[part 3 of 4: packages /MICROSAR/Dcm_swc/Interfaces to /MICROSAR/Dcm_swc/ComponentTypes]
AUTOSAR XML (schema 00048)
package /MICROSAR/Dcm_swc/Interfaces  (continued)
  378 x client server interface, all with is-service=true, service-kind=DIAGNOSTIC-COMMUNICATION-MANAGER:  (continued)
    DataServices_Data_DiagnServi_TABROW_NeuMeasu_Read_35
      operation ReadData: possible-error=[DataServices_Data_DiagnServi_TABROW_NeuMeasu_Read_35/E_NOT_OK, DataServices_Data_DiagnServi_TABROW_NeuMeasu_Read_35/DCM_E_PENDING]
        arg OpStatus: type=Dcm_OpStatusType, direction=IN
        arg Data: type=Dcm_Data5ByteType, direction=OUT
      operation ConditionCheckRead: possible-error=[DataServices_Data_DiagnServi_TABROW_NeuMeasu_Read_35/E_NOT_OK, DataServices_Data_DiagnServi_TABROW_NeuMeasu_Read_35/DCM_E_PENDING]
        arg OpStatus: type=Dcm_OpStatusType, direction=IN
        arg ErrorCode: type=Dcm_NegativeResponseCodeType, direction=OUT
      error E_NOT_OK: error-code=1
      error DCM_E_PENDING: error-code=10
    DataServices_Data_DiagnServi_TABROW_NeuMeasu_Read_34
      operation ReadData: possible-error=[DataServices_Data_DiagnServi_TABROW_NeuMeasu_Read_34/E_NOT_OK, DataServices_Data_DiagnServi_TABROW_NeuMeasu_Read_34/DCM_E_PENDING]
        arg OpStatus: type=Dcm_OpStatusType, direction=IN
        arg Data: type=Dcm_Data1ByteType, direction=OUT
      operation ConditionCheckRead: possible-error=[DataServices_Data_DiagnServi_TABROW_NeuMeasu_Read_34/E_NOT_OK, DataServices_Data_DiagnServi_TABROW_NeuMeasu_Read_34/DCM_E_PENDING]
        arg OpStatus: type=Dcm_OpStatusType, direction=IN
        arg ErrorCode: type=Dcm_NegativeResponseCodeType, direction=OUT
      error E_NOT_OK: error-code=1
      error DCM_E_PENDING: error-code=10
    DataServices_Data_DiagnServi_TABROW_NeuMeasu_Read_33
      operation ReadData: possible-error=[DataServices_Data_DiagnServi_TABROW_NeuMeasu_Read_33/E_NOT_OK, DataServices_Data_DiagnServi_TABROW_NeuMeasu_Read_33/DCM_E_PENDING]
        arg OpStatus: type=Dcm_OpStatusType, direction=IN
        arg Data: type=Dcm_Data3ByteType, direction=OUT
      operation ConditionCheckRead: possible-error=[DataServices_Data_DiagnServi_TABROW_NeuMeasu_Read_33/E_NOT_OK, DataServices_Data_DiagnServi_TABROW_NeuMeasu_Read_33/DCM_E_PENDING]
        arg OpStatus: type=Dcm_OpStatusType, direction=IN
        arg ErrorCode: type=Dcm_NegativeResponseCodeType, direction=OUT
      error E_NOT_OK: error-code=1
      error DCM_E_PENDING: error-code=10
    DataServices_Data_DiagnServi_TABROW_NeuMeasu_Read_39
      operation ReadData: possible-error=[DataServices_Data_DiagnServi_TABROW_NeuMeasu_Read_39/E_NOT_OK, DataServices_Data_DiagnServi_TABROW_NeuMeasu_Read_39/DCM_E_PENDING]
        arg OpStatus: type=Dcm_OpStatusType, direction=IN
        arg Data: type=Dcm_Data1ByteType, direction=OUT
      operation ConditionCheckRead: possible-error=[DataServices_Data_DiagnServi_TABROW_NeuMeasu_Read_39/E_NOT_OK, DataServices_Data_DiagnServi_TABROW_NeuMeasu_Read_39/DCM_E_PENDING]
        arg OpStatus: type=Dcm_OpStatusType, direction=IN
        arg ErrorCode: type=Dcm_NegativeResponseCodeType, direction=OUT
      error E_NOT_OK: error-code=1
      error DCM_E_PENDING: error-code=10
    DataServices_Data_DiagnServi_TABROW_NeuMeasu_Read_38
      operation ReadData: possible-error=[DataServices_Data_DiagnServi_TABROW_NeuMeasu_Read_38/E_NOT_OK, DataServices_Data_DiagnServi_TABROW_NeuMeasu_Read_38/DCM_E_PENDING]
        arg OpStatus: type=Dcm_OpStatusType, direction=IN
        arg Data: type=Dcm_Data1ByteType, direction=OUT
      operation ConditionCheckRead: possible-error=[DataServices_Data_DiagnServi_TABROW_NeuMeasu_Read_38/E_NOT_OK, DataServices_Data_DiagnServi_TABROW_NeuMeasu_Read_38/DCM_E_PENDING]
        arg OpStatus: type=Dcm_OpStatusType, direction=IN
        arg ErrorCode: type=Dcm_NegativeResponseCodeType, direction=OUT
      error E_NOT_OK: error-code=1
      error DCM_E_PENDING: error-code=10
    DataServices_Data_DiagnServi_TABROW_NeuMeasu_Read_37
      operation ReadData: possible-error=[DataServices_Data_DiagnServi_TABROW_NeuMeasu_Read_37/E_NOT_OK, DataServices_Data_DiagnServi_TABROW_NeuMeasu_Read_37/DCM_E_PENDING]
        arg OpStatus: type=Dcm_OpStatusType, direction=IN
        arg Data: type=Dcm_Data2ByteType, direction=OUT
      operation ConditionCheckRead: possible-error=[DataServices_Data_DiagnServi_TABROW_NeuMeasu_Read_37/E_NOT_OK, DataServices_Data_DiagnServi_TABROW_NeuMeasu_Read_37/DCM_E_PENDING]
        arg OpStatus: type=Dcm_OpStatusType, direction=IN
        arg ErrorCode: type=Dcm_NegativeResponseCodeType, direction=OUT
      error E_NOT_OK: error-code=1
      error DCM_E_PENDING: error-code=10
    DataServices_Data_DiagnServi_TABROW_NeuMeasu_Read_46_1_1_1_1_1_1_2
      operation ReadData: possible-error=[DataServices_Data_DiagnServi_TABROW_NeuMeasu_Read_46_1_1_1_1_1_1_2/E_NOT_OK, DataServices_Data_DiagnServi_TABROW_NeuMeasu_Read_46_1_1_1_1_1_1_2/DCM_E_PENDING]
        arg OpStatus: type=Dcm_OpStatusType, direction=IN
        arg Data: type=Dcm_Data152ByteType, direction=OUT
      operation ConditionCheckRead: possible-error=[DataServices_Data_DiagnServi_TABROW_NeuMeasu_Read_46_1_1_1_1_1_1_2/E_NOT_OK, DataServices_Data_DiagnServi_TABROW_NeuMeasu_Read_46_1_1_1_1_1_1_2/DCM_E_PENDING]
        arg OpStatus: type=Dcm_OpStatusType, direction=IN
        arg ErrorCode: type=Dcm_NegativeResponseCodeType, direction=OUT
      error E_NOT_OK: error-code=1
      error DCM_E_PENDING: error-code=10
    DataServices_Data_DiagnServi_TABROW_NeuMeasu_Read_46_1_1_1_1_1_1_1
      operation ReadData: possible-error=[DataServices_Data_DiagnServi_TABROW_NeuMeasu_Read_46_1_1_1_1_1_1_1/E_NOT_OK, DataServices_Data_DiagnServi_TABROW_NeuMeasu_Read_46_1_1_1_1_1_1_1/DCM_E_PENDING]
        arg OpStatus: type=Dcm_OpStatusType, direction=IN
        arg Data: type=Dcm_Data152ByteType, direction=OUT
      operation ConditionCheckRead: possible-error=[DataServices_Data_DiagnServi_TABROW_NeuMeasu_Read_46_1_1_1_1_1_1_1/E_NOT_OK, DataServices_Data_DiagnServi_TABROW_NeuMeasu_Read_46_1_1_1_1_1_1_1/DCM_E_PENDING]
        arg OpStatus: type=Dcm_OpStatusType, direction=IN
        arg ErrorCode: type=Dcm_NegativeResponseCodeType, direction=OUT
      error E_NOT_OK: error-code=1
      error DCM_E_PENDING: error-code=10
    DataServices_Data_DiagnServi_TABROW_NeuMeasu_Read_43
      operation ReadData: possible-error=[DataServices_Data_DiagnServi_TABROW_NeuMeasu_Read_43/E_NOT_OK, DataServices_Data_DiagnServi_TABROW_NeuMeasu_Read_43/DCM_E_PENDING]
        arg OpStatus: type=Dcm_OpStatusType, direction=IN
        arg Data: type=Dcm_Data64ByteType, direction=OUT
      operation ConditionCheckRead: possible-error=[DataServices_Data_DiagnServi_TABROW_NeuMeasu_Read_43/E_NOT_OK, DataServices_Data_DiagnServi_TABROW_NeuMeasu_Read_43/DCM_E_PENDING]
        arg OpStatus: type=Dcm_OpStatusType, direction=IN
        arg ErrorCode: type=Dcm_NegativeResponseCodeType, direction=OUT
      error E_NOT_OK: error-code=1
      error DCM_E_PENDING: error-code=10
    DataServices_Data_DiagnServi_TABROW_NeuMeasu_Read_42
      operation ReadData: possible-error=[DataServices_Data_DiagnServi_TABROW_NeuMeasu_Read_42/E_NOT_OK, DataServices_Data_DiagnServi_TABROW_NeuMeasu_Read_42/DCM_E_PENDING]
        arg OpStatus: type=Dcm_OpStatusType, direction=IN
        arg Data: type=Dcm_Data1ByteType, direction=OUT
      operation ConditionCheckRead: possible-error=[DataServices_Data_DiagnServi_TABROW_NeuMeasu_Read_42/E_NOT_OK, DataServices_Data_DiagnServi_TABROW_NeuMeasu_Read_42/DCM_E_PENDING]
        arg OpStatus: type=Dcm_OpStatusType, direction=IN
        arg ErrorCode: type=Dcm_NegativeResponseCodeType, direction=OUT
      error E_NOT_OK: error-code=1
      error DCM_E_PENDING: error-code=10
    DataServices_Data_DiagnServi_TABROW_NeuMeasu_Read_41
      operation ReadData: possible-error=[DataServices_Data_DiagnServi_TABROW_NeuMeasu_Read_41/E_NOT_OK, DataServices_Data_DiagnServi_TABROW_NeuMeasu_Read_41/DCM_E_PENDING]
        arg OpStatus: type=Dcm_OpStatusType, direction=IN
        arg Data: type=Dcm_Data14ByteType, direction=OUT
      operation ConditionCheckRead: possible-error=[DataServices_Data_DiagnServi_TABROW_NeuMeasu_Read_41/E_NOT_OK, DataServices_Data_DiagnServi_TABROW_NeuMeasu_Read_41/DCM_E_PENDING]
        arg OpStatus: type=Dcm_OpStatusType, direction=IN
        arg ErrorCode: type=Dcm_NegativeResponseCodeType, direction=OUT
      error E_NOT_OK: error-code=1
      error DCM_E_PENDING: error-code=10
    DataServices_Data_DiagnServi_TABROW_NeuMeasu_Read_40
      operation ReadData: possible-error=[DataServices_Data_DiagnServi_TABROW_NeuMeasu_Read_40/E_NOT_OK, DataServices_Data_DiagnServi_TABROW_NeuMeasu_Read_40/DCM_E_PENDING]
        arg OpStatus: type=Dcm_OpStatusType, direction=IN
        arg Data: type=Dcm_Data4ByteType, direction=OUT
      operation ConditionCheckRead: possible-error=[DataServices_Data_DiagnServi_TABROW_NeuMeasu_Read_40/E_NOT_OK, DataServices_Data_DiagnServi_TABROW_NeuMeasu_Read_40/DCM_E_PENDING]
        arg OpStatus: type=Dcm_OpStatusType, direction=IN
        arg ErrorCode: type=Dcm_NegativeResponseCodeType, direction=OUT
      error E_NOT_OK: error-code=1
      error DCM_E_PENDING: error-code=10
    DataServices_Data_DiagnServi_Assembly_part_number_Read
      operation ReadData: possible-error=[DataServices_Data_DiagnServi_Assembly_part_number_Read/E_NOT_OK, DataServices_Data_DiagnServi_Assembly_part_number_Read/DCM_E_PENDING]
        arg OpStatus: type=Dcm_OpStatusType, direction=IN
        arg Data: type=Dcm_Data11ByteType, direction=OUT
      operation ConditionCheckRead: possible-error=[DataServices_Data_DiagnServi_Assembly_part_number_Read/E_NOT_OK, DataServices_Data_DiagnServi_Assembly_part_number_Read/DCM_E_PENDING]
        arg OpStatus: type=Dcm_OpStatusType, direction=IN
        arg ErrorCode: type=Dcm_NegativeResponseCodeType, direction=OUT
      operation WriteData: possible-error=[DataServices_Data_DiagnServi_Assembly_part_number_Read/E_NOT_OK, DataServices_Data_DiagnServi_Assembly_part_number_Read/DCM_E_PENDING]
        arg Data: type=Dcm_Data11ByteType, direction=IN
        arg OpStatus: type=Dcm_OpStatusType, direction=IN
        arg ErrorCode: type=Dcm_NegativeResponseCodeType, direction=OUT
      error E_NOT_OK: error-code=1
      error DCM_E_PENDING: error-code=10
    DataServices_Data_DiagnServi_TABROW_NeuMeasu_Read_47
      operation ReadData: possible-error=[DataServices_Data_DiagnServi_TABROW_NeuMeasu_Read_47/E_NOT_OK, DataServices_Data_DiagnServi_TABROW_NeuMeasu_Read_47/DCM_E_PENDING]
        arg OpStatus: type=Dcm_OpStatusType, direction=IN
        arg Data: type=Dcm_Data2ByteType, direction=OUT
      operation ConditionCheckRead: possible-error=[DataServices_Data_DiagnServi_TABROW_NeuMeasu_Read_47/E_NOT_OK, DataServices_Data_DiagnServi_TABROW_NeuMeasu_Read_47/DCM_E_PENDING]
        arg OpStatus: type=Dcm_OpStatusType, direction=IN
        arg ErrorCode: type=Dcm_NegativeResponseCodeType, direction=OUT
      error E_NOT_OK: error-code=1
      error DCM_E_PENDING: error-code=10
    DataServices_Data_DiagnServi_TABROW_NeuMeasu_Read_46
      operation ReadData: possible-error=[DataServices_Data_DiagnServi_TABROW_NeuMeasu_Read_46/E_NOT_OK, DataServices_Data_DiagnServi_TABROW_NeuMeasu_Read_46/DCM_E_PENDING]
        arg OpStatus: type=Dcm_OpStatusType, direction=IN
        arg Data: type=Dcm_Data152ByteType, direction=OUT
      operation ConditionCheckRead: possible-error=[DataServices_Data_DiagnServi_TABROW_NeuMeasu_Read_46/E_NOT_OK, DataServices_Data_DiagnServi_TABROW_NeuMeasu_Read_46/DCM_E_PENDING]
        arg OpStatus: type=Dcm_OpStatusType, direction=IN
        arg ErrorCode: type=Dcm_NegativeResponseCodeType, direction=OUT
      error E_NOT_OK: error-code=1
      error DCM_E_PENDING: error-code=10
    DataServices_Data_DiagnServi_TABROW_NeuMeasu_Read_45
      operation ReadData: possible-error=[DataServices_Data_DiagnServi_TABROW_NeuMeasu_Read_45/E_NOT_OK, DataServices_Data_DiagnServi_TABROW_NeuMeasu_Read_45/DCM_E_PENDING]
        arg OpStatus: type=Dcm_OpStatusType, direction=IN
        arg Data: type=Dcm_Data6ByteType, direction=OUT
      operation ConditionCheckRead: possible-error=[DataServices_Data_DiagnServi_TABROW_NeuMeasu_Read_45/E_NOT_OK, DataServices_Data_DiagnServi_TABROW_NeuMeasu_Read_45/DCM_E_PENDING]
        arg OpStatus: type=Dcm_OpStatusType, direction=IN
        arg ErrorCode: type=Dcm_NegativeResponseCodeType, direction=OUT
      error E_NOT_OK: error-code=1
      error DCM_E_PENDING: error-code=10
    DataServices_Data_DiagnServi_TABROW_NeuMeasu_Read_49
      operation ReadData: possible-error=[DataServices_Data_DiagnServi_TABROW_NeuMeasu_Read_49/E_NOT_OK, DataServices_Data_DiagnServi_TABROW_NeuMeasu_Read_49/DCM_E_PENDING]
        arg OpStatus: type=Dcm_OpStatusType, direction=IN
        arg Data: type=Dcm_Data2ByteType, direction=OUT
      operation ConditionCheckRead: possible-error=[DataServices_Data_DiagnServi_TABROW_NeuMeasu_Read_49/E_NOT_OK, DataServices_Data_DiagnServi_TABROW_NeuMeasu_Read_49/DCM_E_PENDING]
        arg OpStatus: type=Dcm_OpStatusType, direction=IN
        arg ErrorCode: type=Dcm_NegativeResponseCodeType, direction=OUT
      error E_NOT_OK: error-code=1
      error DCM_E_PENDING: error-code=10
    DataServices_Data_DiagnServi_TABROW_NeuMeasu_Read_48
      operation ReadData: possible-error=[DataServices_Data_DiagnServi_TABROW_NeuMeasu_Read_48/E_NOT_OK, DataServices_Data_DiagnServi_TABROW_NeuMeasu_Read_48/DCM_E_PENDING]
        arg OpStatus: type=Dcm_OpStatusType, direction=IN
        arg Data: type=Dcm_Data24ByteType, direction=OUT
      operation ConditionCheckRead: possible-error=[DataServices_Data_DiagnServi_TABROW_NeuMeasu_Read_48/E_NOT_OK, DataServices_Data_DiagnServi_TABROW_NeuMeasu_Read_48/DCM_E_PENDING]
        arg OpStatus: type=Dcm_OpStatusType, direction=IN
        arg ErrorCode: type=Dcm_NegativeResponseCodeType, direction=OUT
      error E_NOT_OK: error-code=1
      error DCM_E_PENDING: error-code=10
    DataServices_Data_DiagnServi_TABROW_TABROECUPr_Read
      operation ReadData: possible-error=[DataServices_Data_DiagnServi_TABROW_TABROECUPr_Read/E_NOT_OK, DataServices_Data_DiagnServi_TABROW_TABROECUPr_Read/DCM_E_PENDING]
        arg OpStatus: type=Dcm_OpStatusType, direction=IN
        arg Data: type=Dcm_Data1ByteType, direction=OUT
      operation ConditionCheckRead: possible-error=[DataServices_Data_DiagnServi_TABROW_TABROECUPr_Read/E_NOT_OK, DataServices_Data_DiagnServi_TABROW_TABROECUPr_Read/DCM_E_PENDING]
        arg OpStatus: type=Dcm_OpStatusType, direction=IN
        arg ErrorCode: type=Dcm_NegativeResponseCodeType, direction=OUT
      error E_NOT_OK: error-code=1
      error DCM_E_PENDING: error-code=10
    DataServices_Data_TABROW_TABROSyste_Read_1_1_1_1_1_1_1_1_1_1_1_1
      operation ReadData: possible-error=[DataServices_Data_TABROW_TABROSyste_Read_1_1_1_1_1_1_1_1_1_1_1_1/E_NOT_OK, DataServices_Data_TABROW_TABROSyste_Read_1_1_1_1_1_1_1_1_1_1_1_1/DCM_E_PENDING]
        arg OpStatus: type=Dcm_OpStatusType, direction=IN
        arg Data: type=Dcm_Data14ByteType, direction=OUT
      operation ConditionCheckRead: possible-error=[DataServices_Data_TABROW_TABROSyste_Read_1_1_1_1_1_1_1_1_1_1_1_1/E_NOT_OK, DataServices_Data_TABROW_TABROSyste_Read_1_1_1_1_1_1_1_1_1_1_1_1/DCM_E_PENDING]
        arg OpStatus: type=Dcm_OpStatusType, direction=IN
        arg ErrorCode: type=Dcm_NegativeResponseCodeType, direction=OUT
      error E_NOT_OK: error-code=1
      error DCM_E_PENDING: error-code=10
    DataServices_Data_DiagnServi_TABROW_NeuMeasu_Read_10
      operation ReadData: possible-error=[DataServices_Data_DiagnServi_TABROW_NeuMeasu_Read_10/E_NOT_OK, DataServices_Data_DiagnServi_TABROW_NeuMeasu_Read_10/DCM_E_PENDING]
        arg OpStatus: type=Dcm_OpStatusType, direction=IN
        arg Data: type=Dcm_Data2ByteType, direction=OUT
      operation ConditionCheckRead: possible-error=[DataServices_Data_DiagnServi_TABROW_NeuMeasu_Read_10/E_NOT_OK, DataServices_Data_DiagnServi_TABROW_NeuMeasu_Read_10/DCM_E_PENDING]
        arg OpStatus: type=Dcm_OpStatusType, direction=IN
        arg ErrorCode: type=Dcm_NegativeResponseCodeType, direction=OUT
      error E_NOT_OK: error-code=1
      error DCM_E_PENDING: error-code=10
    DataServices_Data_DiagnServi_TABROW_NeuMeasu_Read_43_1_1_1_1_1_1_1_1_1_1_1
      operation ReadData: possible-error=[DataServices_Data_DiagnServi_TABROW_NeuMeasu_Read_43_1_1_1_1_1_1_1_1_1_1_1/E_NOT_OK, DataServices_Data_DiagnServi_TABROW_NeuMeasu_Read_43_1_1_1_1_1_1_1_1_1_1_1/DCM_E_PENDING]
        arg OpStatus: type=Dcm_OpStatusType, direction=IN
        arg Data: type=Dcm_Data64ByteType, direction=OUT
      operation ConditionCheckRead: possible-error=[DataServices_Data_DiagnServi_TABROW_NeuMeasu_Read_43_1_1_1_1_1_1_1_1_1_1_1/E_NOT_OK, DataServices_Data_DiagnServi_TABROW_NeuMeasu_Read_43_1_1_1_1_1_1_1_1_1_1_1/DCM_E_PENDING]
        arg OpStatus: type=Dcm_OpStatusType, direction=IN
        arg ErrorCode: type=Dcm_NegativeResponseCodeType, direction=OUT
      error E_NOT_OK: error-code=1
      error DCM_E_PENDING: error-code=10
    DataServices_Data_Minimum_Discharge_Voltage_Read_Data_By_Identifier
      operation ReadData: possible-error=[DataServices_Data_Minimum_Discharge_Voltage_Read_Data_By_Identifier/E_NOT_OK, DataServices_Data_Minimum_Discharge_Voltage_Read_Data_By_Identifier/DCM_E_PENDING]
        arg OpStatus: type=Dcm_OpStatusType, direction=IN
        arg Data: type=Dcm_Data2ByteType, direction=OUT
      operation ConditionCheckRead: possible-error=[DataServices_Data_Minimum_Discharge_Voltage_Read_Data_By_Identifier/E_NOT_OK, DataServices_Data_Minimum_Discharge_Voltage_Read_Data_By_Identifier/DCM_E_PENDING]
        arg OpStatus: type=Dcm_OpStatusType, direction=IN
        arg ErrorCode: type=Dcm_NegativeResponseCodeType, direction=OUT
      error E_NOT_OK: error-code=1
      error DCM_E_PENDING: error-code=10
    DataServices_Data_DiagnServi_TABROW_NeuMeasu_Read_19
      operation ReadData: possible-error=[DataServices_Data_DiagnServi_TABROW_NeuMeasu_Read_19/E_NOT_OK, DataServices_Data_DiagnServi_TABROW_NeuMeasu_Read_19/DCM_E_PENDING]
        arg OpStatus: type=Dcm_OpStatusType, direction=IN
        arg Data: type=Dcm_Data3ByteType, direction=OUT
      operation ConditionCheckRead: possible-error=[DataServices_Data_DiagnServi_TABROW_NeuMeasu_Read_19/E_NOT_OK, DataServices_Data_DiagnServi_TABROW_NeuMeasu_Read_19/DCM_E_PENDING]
        arg OpStatus: type=Dcm_OpStatusType, direction=IN
        arg ErrorCode: type=Dcm_NegativeResponseCodeType, direction=OUT
      error E_NOT_OK: error-code=1
      error DCM_E_PENDING: error-code=10
    DataServices_Data_DiagnServi_TABROW_NeuMeasu_Read_14
      operation ReadData: possible-error=[DataServices_Data_DiagnServi_TABROW_NeuMeasu_Read_14/E_NOT_OK, DataServices_Data_DiagnServi_TABROW_NeuMeasu_Read_14/DCM_E_PENDING]
        arg OpStatus: type=Dcm_OpStatusType, direction=IN
        arg Data: type=Dcm_Data1ByteType, direction=OUT
      operation ConditionCheckRead: possible-error=[DataServices_Data_DiagnServi_TABROW_NeuMeasu_Read_14/E_NOT_OK, DataServices_Data_DiagnServi_TABROW_NeuMeasu_Read_14/DCM_E_PENDING]
        arg OpStatus: type=Dcm_OpStatusType, direction=IN
        arg ErrorCode: type=Dcm_NegativeResponseCodeType, direction=OUT
      error E_NOT_OK: error-code=1
      error DCM_E_PENDING: error-code=10
    DataServices_Data_DiagnServi_TABROW_NeuMeasu_Read_70_1
      operation ReadData: possible-error=[DataServices_Data_DiagnServi_TABROW_NeuMeasu_Read_70_1/E_NOT_OK, DataServices_Data_DiagnServi_TABROW_NeuMeasu_Read_70_1/DCM_E_PENDING]
        arg OpStatus: type=Dcm_OpStatusType, direction=IN
        arg Data: type=Dcm_Data1ByteType, direction=OUT
      operation ConditionCheckRead: possible-error=[DataServices_Data_DiagnServi_TABROW_NeuMeasu_Read_70_1/E_NOT_OK, DataServices_Data_DiagnServi_TABROW_NeuMeasu_Read_70_1/DCM_E_PENDING]
        arg OpStatus: type=Dcm_OpStatusType, direction=IN
        arg ErrorCode: type=Dcm_NegativeResponseCodeType, direction=OUT
      error E_NOT_OK: error-code=1
      error DCM_E_PENDING: error-code=10
    DataServices_Data_DiagnServi_TABROW_NeuMeasu_Read_13
      operation ReadData: possible-error=[DataServices_Data_DiagnServi_TABROW_NeuMeasu_Read_13/E_NOT_OK, DataServices_Data_DiagnServi_TABROW_NeuMeasu_Read_13/DCM_E_PENDING]
        arg OpStatus: type=Dcm_OpStatusType, direction=IN
        arg Data: type=Dcm_Data6ByteType, direction=OUT
      operation ConditionCheckRead: possible-error=[DataServices_Data_DiagnServi_TABROW_NeuMeasu_Read_13/E_NOT_OK, DataServices_Data_DiagnServi_TABROW_NeuMeasu_Read_13/DCM_E_PENDING]
        arg OpStatus: type=Dcm_OpStatusType, direction=IN
        arg ErrorCode: type=Dcm_NegativeResponseCodeType, direction=OUT
      error E_NOT_OK: error-code=1
      error DCM_E_PENDING: error-code=10
    DataServices_Data_DiagnServi_TABROW_NeuMeasu_Read_12
      operation ReadData: possible-error=[DataServices_Data_DiagnServi_TABROW_NeuMeasu_Read_12/E_NOT_OK, DataServices_Data_DiagnServi_TABROW_NeuMeasu_Read_12/DCM_E_PENDING]
        arg OpStatus: type=Dcm_OpStatusType, direction=IN
        arg Data: type=Dcm_Data3ByteType, direction=OUT
      operation ConditionCheckRead: possible-error=[DataServices_Data_DiagnServi_TABROW_NeuMeasu_Read_12/E_NOT_OK, DataServices_Data_DiagnServi_TABROW_NeuMeasu_Read_12/DCM_E_PENDING]
        arg OpStatus: type=Dcm_OpStatusType, direction=IN
        arg ErrorCode: type=Dcm_NegativeResponseCodeType, direction=OUT
      error E_NOT_OK: error-code=1
      error DCM_E_PENDING: error-code=10
    DataServices_Data_DiagnServi_TABROW_NeuMeasu_Read_11
      operation ReadData: possible-error=[DataServices_Data_DiagnServi_TABROW_NeuMeasu_Read_11/E_NOT_OK, DataServices_Data_DiagnServi_TABROW_NeuMeasu_Read_11/DCM_E_PENDING]
        arg OpStatus: type=Dcm_OpStatusType, direction=IN
        arg Data: type=Dcm_Data3ByteType, direction=OUT
      operation ConditionCheckRead: possible-error=[DataServices_Data_DiagnServi_TABROW_NeuMeasu_Read_11/E_NOT_OK, DataServices_Data_DiagnServi_TABROW_NeuMeasu_Read_11/DCM_E_PENDING]
        arg OpStatus: type=Dcm_OpStatusType, direction=IN
        arg ErrorCode: type=Dcm_NegativeResponseCodeType, direction=OUT
      error E_NOT_OK: error-code=1
      error DCM_E_PENDING: error-code=10
    DataServices_Data_DiagnServi_TABROW_NeuMeasu_Read_18
      operation ReadData: possible-error=[DataServices_Data_DiagnServi_TABROW_NeuMeasu_Read_18/E_NOT_OK, DataServices_Data_DiagnServi_TABROW_NeuMeasu_Read_18/DCM_E_PENDING]
        arg OpStatus: type=Dcm_OpStatusType, direction=IN
        arg Data: type=Dcm_Data1ByteType, direction=OUT
      operation ConditionCheckRead: possible-error=[DataServices_Data_DiagnServi_TABROW_NeuMeasu_Read_18/E_NOT_OK, DataServices_Data_DiagnServi_TABROW_NeuMeasu_Read_18/DCM_E_PENDING]
        arg OpStatus: type=Dcm_OpStatusType, direction=IN
        arg ErrorCode: type=Dcm_NegativeResponseCodeType, direction=OUT
      error E_NOT_OK: error-code=1
      error DCM_E_PENDING: error-code=10
    DataServices_Data_DiagnServi_TABROW_NeuMeasu_Read_17
      operation ReadData: possible-error=[DataServices_Data_DiagnServi_TABROW_NeuMeasu_Read_17/E_NOT_OK, DataServices_Data_DiagnServi_TABROW_NeuMeasu_Read_17/DCM_E_PENDING]
        arg OpStatus: type=Dcm_OpStatusType, direction=IN
        arg Data: type=Dcm_Data1ByteType, direction=OUT
      operation ConditionCheckRead: possible-error=[DataServices_Data_DiagnServi_TABROW_NeuMeasu_Read_17/E_NOT_OK, DataServices_Data_DiagnServi_TABROW_NeuMeasu_Read_17/DCM_E_PENDING]
        arg OpStatus: type=Dcm_OpStatusType, direction=IN
        arg ErrorCode: type=Dcm_NegativeResponseCodeType, direction=OUT
      error E_NOT_OK: error-code=1
      error DCM_E_PENDING: error-code=10
    DataServices_Data_DiagnServi_TABROW_NeuMeasu_Read_16
      operation ReadData: possible-error=[DataServices_Data_DiagnServi_TABROW_NeuMeasu_Read_16/E_NOT_OK, DataServices_Data_DiagnServi_TABROW_NeuMeasu_Read_16/DCM_E_PENDING]
        arg OpStatus: type=Dcm_OpStatusType, direction=IN
        arg Data: type=Dcm_Data1ByteType, direction=OUT
      operation ConditionCheckRead: possible-error=[DataServices_Data_DiagnServi_TABROW_NeuMeasu_Read_16/E_NOT_OK, DataServices_Data_DiagnServi_TABROW_NeuMeasu_Read_16/DCM_E_PENDING]
        arg OpStatus: type=Dcm_OpStatusType, direction=IN
        arg ErrorCode: type=Dcm_NegativeResponseCodeType, direction=OUT
      error E_NOT_OK: error-code=1
      error DCM_E_PENDING: error-code=10
    DataServices_Data_DiagnServi_TABROW_NeuMeasu_Read_15
      operation ReadData: possible-error=[DataServices_Data_DiagnServi_TABROW_NeuMeasu_Read_15/E_NOT_OK, DataServices_Data_DiagnServi_TABROW_NeuMeasu_Read_15/DCM_E_PENDING]
        arg OpStatus: type=Dcm_OpStatusType, direction=IN
        arg Data: type=Dcm_Data1ByteType, direction=OUT
      operation ConditionCheckRead: possible-error=[DataServices_Data_DiagnServi_TABROW_NeuMeasu_Read_15/E_NOT_OK, DataServices_Data_DiagnServi_TABROW_NeuMeasu_Read_15/DCM_E_PENDING]
        arg OpStatus: type=Dcm_OpStatusType, direction=IN
        arg ErrorCode: type=Dcm_NegativeResponseCodeType, direction=OUT
      error E_NOT_OK: error-code=1
      error DCM_E_PENDING: error-code=10
    DataServices_Data_DiagnServi_TABROW_NeuMeasu_Read_27_2_1_1
      operation ReadData: possible-error=[DataServices_Data_DiagnServi_TABROW_NeuMeasu_Read_27_2_1_1/E_NOT_OK, DataServices_Data_DiagnServi_TABROW_NeuMeasu_Read_27_2_1_1/DCM_E_PENDING]
        arg OpStatus: type=Dcm_OpStatusType, direction=IN
        arg Data: type=Dcm_Data27ByteType, direction=OUT
      operation ConditionCheckRead: possible-error=[DataServices_Data_DiagnServi_TABROW_NeuMeasu_Read_27_2_1_1/E_NOT_OK, DataServices_Data_DiagnServi_TABROW_NeuMeasu_Read_27_2_1_1/DCM_E_PENDING]
        arg OpStatus: type=Dcm_OpStatusType, direction=IN
        arg ErrorCode: type=Dcm_NegativeResponseCodeType, direction=OUT
      error E_NOT_OK: error-code=1
      error DCM_E_PENDING: error-code=10
    DataServices_Data_DiagnServi_TABROW_NeuMeasu_Read_20
      operation ReadData: possible-error=[DataServices_Data_DiagnServi_TABROW_NeuMeasu_Read_20/E_NOT_OK, DataServices_Data_DiagnServi_TABROW_NeuMeasu_Read_20/DCM_E_PENDING]
        arg OpStatus: type=Dcm_OpStatusType, direction=IN
        arg Data: type=Dcm_Data1ByteType, direction=OUT
      operation ConditionCheckRead: possible-error=[DataServices_Data_DiagnServi_TABROW_NeuMeasu_Read_20/E_NOT_OK, DataServices_Data_DiagnServi_TABROW_NeuMeasu_Read_20/DCM_E_PENDING]
        arg OpStatus: type=Dcm_OpStatusType, direction=IN
        arg ErrorCode: type=Dcm_NegativeResponseCodeType, direction=OUT
      error E_NOT_OK: error-code=1
      error DCM_E_PENDING: error-code=10
    DataServices_Data_DiagnServi_Assembly_production_data_Read
      operation ReadData: possible-error=[DataServices_Data_DiagnServi_Assembly_production_data_Read/E_NOT_OK, DataServices_Data_DiagnServi_Assembly_production_data_Read/DCM_E_PENDING]
        arg OpStatus: type=Dcm_OpStatusType, direction=IN
        arg Data: type=Dcm_Data22ByteType, direction=OUT
      operation ConditionCheckRead: possible-error=[DataServices_Data_DiagnServi_Assembly_production_data_Read/E_NOT_OK, DataServices_Data_DiagnServi_Assembly_production_data_Read/DCM_E_PENDING]
        arg OpStatus: type=Dcm_OpStatusType, direction=IN
        arg ErrorCode: type=Dcm_NegativeResponseCodeType, direction=OUT
      operation WriteData: possible-error=[DataServices_Data_DiagnServi_Assembly_production_data_Read/E_NOT_OK, DataServices_Data_DiagnServi_Assembly_production_data_Read/DCM_E_PENDING]
        arg Data: type=Dcm_Data22ByteType, direction=IN
        arg OpStatus: type=Dcm_OpStatusType, direction=IN
        arg ErrorCode: type=Dcm_NegativeResponseCodeType, direction=OUT
      error E_NOT_OK: error-code=1
      error DCM_E_PENDING: error-code=10
    DataServices_Data_TABROW_VkmsTrainCount_Read_Data_By_Identifier
      operation ReadData: possible-error=[DataServices_Data_TABROW_VkmsTrainCount_Read_Data_By_Identifier/E_NOT_OK, DataServices_Data_TABROW_VkmsTrainCount_Read_Data_By_Identifier/DCM_E_PENDING]
        arg OpStatus: type=Dcm_OpStatusType, direction=IN
        arg Data: type=Dcm_Data3ByteType, direction=OUT
      operation ConditionCheckRead: possible-error=[DataServices_Data_TABROW_VkmsTrainCount_Read_Data_By_Identifier/E_NOT_OK, DataServices_Data_TABROW_VkmsTrainCount_Read_Data_By_Identifier/DCM_E_PENDING]
        arg OpStatus: type=Dcm_OpStatusType, direction=IN
        arg ErrorCode: type=Dcm_NegativeResponseCodeType, direction=OUT
      error E_NOT_OK: error-code=1
      error DCM_E_PENDING: error-code=10
    DataServices_Data_DiagnServi_Cell_part_number_Read
      operation ReadData: possible-error=[DataServices_Data_DiagnServi_Cell_part_number_Read/E_NOT_OK, DataServices_Data_DiagnServi_Cell_part_number_Read/DCM_E_PENDING]
        arg OpStatus: type=Dcm_OpStatusType, direction=IN
        arg Data: type=Dcm_Data11ByteType, direction=OUT
      operation ConditionCheckRead: possible-error=[DataServices_Data_DiagnServi_Cell_part_number_Read/E_NOT_OK, DataServices_Data_DiagnServi_Cell_part_number_Read/DCM_E_PENDING]
        arg OpStatus: type=Dcm_OpStatusType, direction=IN
        arg ErrorCode: type=Dcm_NegativeResponseCodeType, direction=OUT
      operation WriteData: possible-error=[DataServices_Data_DiagnServi_Cell_part_number_Read/E_NOT_OK, DataServices_Data_DiagnServi_Cell_part_number_Read/DCM_E_PENDING]
        arg Data: type=Dcm_Data11ByteType, direction=IN
        arg OpStatus: type=Dcm_OpStatusType, direction=IN
        arg ErrorCode: type=Dcm_NegativeResponseCodeType, direction=OUT
      error E_NOT_OK: error-code=1
      error DCM_E_PENDING: error-code=10
    DataServices_Data_TABROW_CellStateOfChargMaxim_ReadDataByIdent
      operation ReadData: possible-error=[DataServices_Data_TABROW_CellStateOfChargMaxim_ReadDataByIdent/E_NOT_OK, DataServices_Data_TABROW_CellStateOfChargMaxim_ReadDataByIdent/DCM_E_PENDING]
        arg OpStatus: type=Dcm_OpStatusType, direction=IN
        arg Data: type=Dcm_Data4ByteType, direction=OUT
      operation ConditionCheckRead: possible-error=[DataServices_Data_TABROW_CellStateOfChargMaxim_ReadDataByIdent/E_NOT_OK, DataServices_Data_TABROW_CellStateOfChargMaxim_ReadDataByIdent/DCM_E_PENDING]
        arg OpStatus: type=Dcm_OpStatusType, direction=IN
        arg ErrorCode: type=Dcm_NegativeResponseCodeType, direction=OUT
      error E_NOT_OK: error-code=1
      error DCM_E_PENDING: error-code=10
    DataServices_Data_DiagnServi_TABROW_NeuMeasu_Read_25
      operation ReadData: possible-error=[DataServices_Data_DiagnServi_TABROW_NeuMeasu_Read_25/E_NOT_OK, DataServices_Data_DiagnServi_TABROW_NeuMeasu_Read_25/DCM_E_PENDING]
        arg OpStatus: type=Dcm_OpStatusType, direction=IN
        arg Data: type=Dcm_Data2ByteType, direction=OUT
      operation ConditionCheckRead: possible-error=[DataServices_Data_DiagnServi_TABROW_NeuMeasu_Read_25/E_NOT_OK, DataServices_Data_DiagnServi_TABROW_NeuMeasu_Read_25/DCM_E_PENDING]
        arg OpStatus: type=Dcm_OpStatusType, direction=IN
        arg ErrorCode: type=Dcm_NegativeResponseCodeType, direction=OUT
      error E_NOT_OK: error-code=1
      error DCM_E_PENDING: error-code=10
    DataServices_Data_DiagnServi_TABROW_NeuMeasu_Read_24
      operation ReadData: possible-error=[DataServices_Data_DiagnServi_TABROW_NeuMeasu_Read_24/E_NOT_OK, DataServices_Data_DiagnServi_TABROW_NeuMeasu_Read_24/DCM_E_PENDING]
        arg OpStatus: type=Dcm_OpStatusType, direction=IN
        arg Data: type=Dcm_Data1ByteType, direction=OUT
      operation ConditionCheckRead: possible-error=[DataServices_Data_DiagnServi_TABROW_NeuMeasu_Read_24/E_NOT_OK, DataServices_Data_DiagnServi_TABROW_NeuMeasu_Read_24/DCM_E_PENDING]
        arg OpStatus: type=Dcm_OpStatusType, direction=IN
        arg ErrorCode: type=Dcm_NegativeResponseCodeType, direction=OUT
      error E_NOT_OK: error-code=1
      error DCM_E_PENDING: error-code=10
    DataServices_Data_DiagnServi_TABROW_NeuMeasu_Read_23
      operation ReadData: possible-error=[DataServices_Data_DiagnServi_TABROW_NeuMeasu_Read_23/E_NOT_OK, DataServices_Data_DiagnServi_TABROW_NeuMeasu_Read_23/DCM_E_PENDING]
        arg OpStatus: type=Dcm_OpStatusType, direction=IN
        arg Data: type=Dcm_Data6ByteType, direction=OUT
      operation ConditionCheckRead: possible-error=[DataServices_Data_DiagnServi_TABROW_NeuMeasu_Read_23/E_NOT_OK, DataServices_Data_DiagnServi_TABROW_NeuMeasu_Read_23/DCM_E_PENDING]
        arg OpStatus: type=Dcm_OpStatusType, direction=IN
        arg ErrorCode: type=Dcm_NegativeResponseCodeType, direction=OUT
      error E_NOT_OK: error-code=1
      error DCM_E_PENDING: error-code=10
    DataServices_Data_TABROW_ProgrPreco_Read
      operation ReadData: possible-error=[DataServices_Data_TABROW_ProgrPreco_Read/E_NOT_OK, DataServices_Data_TABROW_ProgrPreco_Read/DCM_E_PENDING]
        arg OpStatus: type=Dcm_OpStatusType, direction=IN
        arg Data: type=Dcm_Data256ByteType, direction=OUT
      operation ReadDataLength: possible-error=[DataServices_Data_TABROW_ProgrPreco_Read/E_NOT_OK, DataServices_Data_TABROW_ProgrPreco_Read/DCM_E_PENDING]
        arg OpStatus: type=Dcm_OpStatusType, direction=IN
        arg DataLength: type=uint16, direction=OUT
      operation ConditionCheckRead: possible-error=[DataServices_Data_TABROW_ProgrPreco_Read/E_NOT_OK, DataServices_Data_TABROW_ProgrPreco_Read/DCM_E_PENDING]
        arg OpStatus: type=Dcm_OpStatusType, direction=IN
        arg ErrorCode: type=Dcm_NegativeResponseCodeType, direction=OUT
      error E_NOT_OK: error-code=1
      error DCM_E_PENDING: error-code=10
    DataServices_Data_DiagnServi_TABROW_NeuMeasu_Read_29
      operation ReadData: possible-error=[DataServices_Data_DiagnServi_TABROW_NeuMeasu_Read_29/E_NOT_OK, DataServices_Data_DiagnServi_TABROW_NeuMeasu_Read_29/DCM_E_PENDING]
        arg OpStatus: type=Dcm_OpStatusType, direction=IN
        arg Data: type=Dcm_Data12ByteType, direction=OUT
      operation ConditionCheckRead: possible-error=[DataServices_Data_DiagnServi_TABROW_NeuMeasu_Read_29/E_NOT_OK, DataServices_Data_DiagnServi_TABROW_NeuMeasu_Read_29/DCM_E_PENDING]
        arg OpStatus: type=Dcm_OpStatusType, direction=IN
        arg ErrorCode: type=Dcm_NegativeResponseCodeType, direction=OUT
      error E_NOT_OK: error-code=1
      error DCM_E_PENDING: error-code=10
    DataServices_Data_DiagnServi_TABROW_NeuMeasu_Read_28
      operation ReadData: possible-error=[DataServices_Data_DiagnServi_TABROW_NeuMeasu_Read_28/E_NOT_OK, DataServices_Data_DiagnServi_TABROW_NeuMeasu_Read_28/DCM_E_PENDING]
        arg OpStatus: type=Dcm_OpStatusType, direction=IN
        arg Data: type=Dcm_Data8ByteType, direction=OUT
      operation ConditionCheckRead: possible-error=[DataServices_Data_DiagnServi_TABROW_NeuMeasu_Read_28/E_NOT_OK, DataServices_Data_DiagnServi_TABROW_NeuMeasu_Read_28/DCM_E_PENDING]
        arg OpStatus: type=Dcm_OpStatusType, direction=IN
        arg ErrorCode: type=Dcm_NegativeResponseCodeType, direction=OUT
      error E_NOT_OK: error-code=1
      error DCM_E_PENDING: error-code=10
    DataServices_Data_DiagnServi_TABROW_NeuMeasu_Read_27
      operation ReadData: possible-error=[DataServices_Data_DiagnServi_TABROW_NeuMeasu_Read_27/E_NOT_OK, DataServices_Data_DiagnServi_TABROW_NeuMeasu_Read_27/DCM_E_PENDING]
        arg OpStatus: type=Dcm_OpStatusType, direction=IN
        arg Data: type=Dcm_Data27ByteType, direction=OUT
      operation ConditionCheckRead: possible-error=[DataServices_Data_DiagnServi_TABROW_NeuMeasu_Read_27/E_NOT_OK, DataServices_Data_DiagnServi_TABROW_NeuMeasu_Read_27/DCM_E_PENDING]
        arg OpStatus: type=Dcm_OpStatusType, direction=IN
        arg ErrorCode: type=Dcm_NegativeResponseCodeType, direction=OUT
      error E_NOT_OK: error-code=1
      error DCM_E_PENDING: error-code=10
    DataServices_Data_DiagnServi_TABROW_NeuMeasu_Read_26
      operation ReadData: possible-error=[DataServices_Data_DiagnServi_TABROW_NeuMeasu_Read_26/E_NOT_OK, DataServices_Data_DiagnServi_TABROW_NeuMeasu_Read_26/DCM_E_PENDING]
        arg OpStatus: type=Dcm_OpStatusType, direction=IN
        arg Data: type=Dcm_Data1ByteType, direction=OUT
      operation ConditionCheckRead: possible-error=[DataServices_Data_DiagnServi_TABROW_NeuMeasu_Read_26/E_NOT_OK, DataServices_Data_DiagnServi_TABROW_NeuMeasu_Read_26/DCM_E_PENDING]
        arg OpStatus: type=Dcm_OpStatusType, direction=IN
        arg ErrorCode: type=Dcm_NegativeResponseCodeType, direction=OUT
      error E_NOT_OK: error-code=1
      error DCM_E_PENDING: error-code=10
    DataServices_Data_DiagnServi_TABROW_NeuMeasu_Read_72
      operation ReadData: possible-error=[DataServices_Data_DiagnServi_TABROW_NeuMeasu_Read_72/E_NOT_OK, DataServices_Data_DiagnServi_TABROW_NeuMeasu_Read_72/DCM_E_PENDING]
        arg OpStatus: type=Dcm_OpStatusType, direction=IN
        arg Data: type=Dcm_Data2ByteType, direction=OUT
      operation ConditionCheckRead: possible-error=[DataServices_Data_DiagnServi_TABROW_NeuMeasu_Read_72/E_NOT_OK, DataServices_Data_DiagnServi_TABROW_NeuMeasu_Read_72/DCM_E_PENDING]
        arg OpStatus: type=Dcm_OpStatusType, direction=IN
        arg ErrorCode: type=Dcm_NegativeResponseCodeType, direction=OUT
      error E_NOT_OK: error-code=1
      error DCM_E_PENDING: error-code=10
    DataServices_Data_DiagnServi_TABROW_NeuMeasu_Read_71
      operation ReadData: possible-error=[DataServices_Data_DiagnServi_TABROW_NeuMeasu_Read_71/E_NOT_OK, DataServices_Data_DiagnServi_TABROW_NeuMeasu_Read_71/DCM_E_PENDING]
        arg OpStatus: type=Dcm_OpStatusType, direction=IN
        arg Data: type=Dcm_Data4ByteType, direction=OUT
      operation ConditionCheckRead: possible-error=[DataServices_Data_DiagnServi_TABROW_NeuMeasu_Read_71/E_NOT_OK, DataServices_Data_DiagnServi_TABROW_NeuMeasu_Read_71/DCM_E_PENDING]
        arg OpStatus: type=Dcm_OpStatusType, direction=IN
        arg ErrorCode: type=Dcm_NegativeResponseCodeType, direction=OUT
      error E_NOT_OK: error-code=1
      error DCM_E_PENDING: error-code=10
    DataServices_Data_DiagnServi_TABROW_NeuMeasu_Read_70
      operation ReadData: possible-error=[DataServices_Data_DiagnServi_TABROW_NeuMeasu_Read_70/E_NOT_OK, DataServices_Data_DiagnServi_TABROW_NeuMeasu_Read_70/DCM_E_PENDING]
        arg OpStatus: type=Dcm_OpStatusType, direction=IN
        arg Data: type=Dcm_Data386ByteType, direction=OUT
      operation ConditionCheckRead: possible-error=[DataServices_Data_DiagnServi_TABROW_NeuMeasu_Read_70/E_NOT_OK, DataServices_Data_DiagnServi_TABROW_NeuMeasu_Read_70/DCM_E_PENDING]
        arg OpStatus: type=Dcm_OpStatusType, direction=IN
        arg ErrorCode: type=Dcm_NegativeResponseCodeType, direction=OUT
      error E_NOT_OK: error-code=1
      error DCM_E_PENDING: error-code=10
    DataServices_Data_DiagnServi_TABROW_NeuMeasu_Read_74
      operation ReadData: possible-error=[DataServices_Data_DiagnServi_TABROW_NeuMeasu_Read_74/E_NOT_OK, DataServices_Data_DiagnServi_TABROW_NeuMeasu_Read_74/DCM_E_PENDING]
        arg OpStatus: type=Dcm_OpStatusType, direction=IN
        arg Data: type=Dcm_Data2ByteType, direction=OUT
      operation ConditionCheckRead: possible-error=[DataServices_Data_DiagnServi_TABROW_NeuMeasu_Read_74/E_NOT_OK, DataServices_Data_DiagnServi_TABROW_NeuMeasu_Read_74/DCM_E_PENDING]
        arg OpStatus: type=Dcm_OpStatusType, direction=IN
        arg ErrorCode: type=Dcm_NegativeResponseCodeType, direction=OUT
      error E_NOT_OK: error-code=1
      error DCM_E_PENDING: error-code=10
    DataServices_Data_DiagnServi_TABROW_NeuMeasu_Read_73
      operation ReadData: possible-error=[DataServices_Data_DiagnServi_TABROW_NeuMeasu_Read_73/E_NOT_OK, DataServices_Data_DiagnServi_TABROW_NeuMeasu_Read_73/DCM_E_PENDING]
        arg OpStatus: type=Dcm_OpStatusType, direction=IN
        arg Data: type=Dcm_Data4ByteType, direction=OUT
      operation ConditionCheckRead: possible-error=[DataServices_Data_DiagnServi_TABROW_NeuMeasu_Read_73/E_NOT_OK, DataServices_Data_DiagnServi_TABROW_NeuMeasu_Read_73/DCM_E_PENDING]
        arg OpStatus: type=Dcm_OpStatusType, direction=IN
        arg ErrorCode: type=Dcm_NegativeResponseCodeType, direction=OUT
      error E_NOT_OK: error-code=1
      error DCM_E_PENDING: error-code=10
    DataServices_Data_TABROW_VWWorksSysteName_Read
      operation ReadData: possible-error=[DataServices_Data_TABROW_VWWorksSysteName_Read/E_NOT_OK, DataServices_Data_TABROW_VWWorksSysteName_Read/DCM_E_PENDING]
        arg OpStatus: type=Dcm_OpStatusType, direction=IN
        arg Data: type=Dcm_Data5ByteType, direction=OUT
      operation ConditionCheckRead: possible-error=[DataServices_Data_TABROW_VWWorksSysteName_Read/E_NOT_OK, DataServices_Data_TABROW_VWWorksSysteName_Read/DCM_E_PENDING]
        arg OpStatus: type=Dcm_OpStatusType, direction=IN
        arg ErrorCode: type=Dcm_NegativeResponseCodeType, direction=OUT
      error E_NOT_OK: error-code=1
      error DCM_E_PENDING: error-code=10
    DataServices_Data_DiagnServi_TABROW_NeuMeasu_Read_83
      operation ReadData: possible-error=[DataServices_Data_DiagnServi_TABROW_NeuMeasu_Read_83/E_NOT_OK, DataServices_Data_DiagnServi_TABROW_NeuMeasu_Read_83/DCM_E_PENDING]
        arg OpStatus: type=Dcm_OpStatusType, direction=IN
        arg Data: type=Dcm_Data4ByteType, direction=OUT
      operation ConditionCheckRead: possible-error=[DataServices_Data_DiagnServi_TABROW_NeuMeasu_Read_83/E_NOT_OK, DataServices_Data_DiagnServi_TABROW_NeuMeasu_Read_83/DCM_E_PENDING]
        arg OpStatus: type=Dcm_OpStatusType, direction=IN
        arg ErrorCode: type=Dcm_NegativeResponseCodeType, direction=OUT
      error E_NOT_OK: error-code=1
      error DCM_E_PENDING: error-code=10
    DataServices_Data_DiagnServi_TABROW_NeuMeasu_Read_9_2
      operation ReadData: possible-error=[DataServices_Data_DiagnServi_TABROW_NeuMeasu_Read_9_2/E_NOT_OK, DataServices_Data_DiagnServi_TABROW_NeuMeasu_Read_9_2/DCM_E_PENDING]
        arg OpStatus: type=Dcm_OpStatusType, direction=IN
        arg Data: type=Dcm_Data1ByteType, direction=OUT
      operation ConditionCheckRead: possible-error=[DataServices_Data_DiagnServi_TABROW_NeuMeasu_Read_9_2/E_NOT_OK, DataServices_Data_DiagnServi_TABROW_NeuMeasu_Read_9_2/DCM_E_PENDING]
        arg OpStatus: type=Dcm_OpStatusType, direction=IN
        arg ErrorCode: type=Dcm_NegativeResponseCodeType, direction=OUT
      error E_NOT_OK: error-code=1
      error DCM_E_PENDING: error-code=10
    DataServices_Data_DiagnServi_TABROW_NeuMeasu_Read_82
      operation ReadData: possible-error=[DataServices_Data_DiagnServi_TABROW_NeuMeasu_Read_82/E_NOT_OK, DataServices_Data_DiagnServi_TABROW_NeuMeasu_Read_82/DCM_E_PENDING]
        arg OpStatus: type=Dcm_OpStatusType, direction=IN
        arg Data: type=Dcm_Data1ByteType, direction=OUT
      operation ConditionCheckRead: possible-error=[DataServices_Data_DiagnServi_TABROW_NeuMeasu_Read_82/E_NOT_OK, DataServices_Data_DiagnServi_TABROW_NeuMeasu_Read_82/DCM_E_PENDING]
        arg OpStatus: type=Dcm_OpStatusType, direction=IN
        arg ErrorCode: type=Dcm_NegativeResponseCodeType, direction=OUT
      error E_NOT_OK: error-code=1
      error DCM_E_PENDING: error-code=10
    DataServices_Data_DiagnServi_TABROW_NeuMeasu_Read_29_1_1
      operation ReadData: possible-error=[DataServices_Data_DiagnServi_TABROW_NeuMeasu_Read_29_1_1/E_NOT_OK, DataServices_Data_DiagnServi_TABROW_NeuMeasu_Read_29_1_1/DCM_E_PENDING]
        arg OpStatus: type=Dcm_OpStatusType, direction=IN
        arg Data: type=Dcm_Data4ByteType, direction=OUT
      operation ConditionCheckRead: possible-error=[DataServices_Data_DiagnServi_TABROW_NeuMeasu_Read_29_1_1/E_NOT_OK, DataServices_Data_DiagnServi_TABROW_NeuMeasu_Read_29_1_1/DCM_E_PENDING]
        arg OpStatus: type=Dcm_OpStatusType, direction=IN
        arg ErrorCode: type=Dcm_NegativeResponseCodeType, direction=OUT
      error E_NOT_OK: error-code=1
      error DCM_E_PENDING: error-code=10
    DataServices_Data_DiagnServi_TABROW_NeuMeasu_Read_29_1_2
      operation ReadData: possible-error=[DataServices_Data_DiagnServi_TABROW_NeuMeasu_Read_29_1_2/E_NOT_OK, DataServices_Data_DiagnServi_TABROW_NeuMeasu_Read_29_1_2/DCM_E_PENDING]
        arg OpStatus: type=Dcm_OpStatusType, direction=IN
        arg Data: type=Dcm_Data4ByteType, direction=OUT
      operation ConditionCheckRead: possible-error=[DataServices_Data_DiagnServi_TABROW_NeuMeasu_Read_29_1_2/E_NOT_OK, DataServices_Data_DiagnServi_TABROW_NeuMeasu_Read_29_1_2/DCM_E_PENDING]
        arg OpStatus: type=Dcm_OpStatusType, direction=IN
        arg ErrorCode: type=Dcm_NegativeResponseCodeType, direction=OUT
      error E_NOT_OK: error-code=1
      error DCM_E_PENDING: error-code=10
    DataServices_Data_DiagnServi_TABROW_NeuMeasu_Read_84
      operation ReadData: possible-error=[DataServices_Data_DiagnServi_TABROW_NeuMeasu_Read_84/E_NOT_OK, DataServices_Data_DiagnServi_TABROW_NeuMeasu_Read_84/DCM_E_PENDING]
        arg OpStatus: type=Dcm_OpStatusType, direction=IN
        arg Data: type=Dcm_Data4ByteType, direction=OUT
      operation ConditionCheckRead: possible-error=[DataServices_Data_DiagnServi_TABROW_NeuMeasu_Read_84/E_NOT_OK, DataServices_Data_DiagnServi_TABROW_NeuMeasu_Read_84/DCM_E_PENDING]
        arg OpStatus: type=Dcm_OpStatusType, direction=IN
        arg ErrorCode: type=Dcm_NegativeResponseCodeType, direction=OUT
      error E_NOT_OK: error-code=1
      error DCM_E_PENDING: error-code=10
    DataServices_Data_DiagnServi_TABROW_NeuMeasu_Read_9_1
      operation ReadData: possible-error=[DataServices_Data_DiagnServi_TABROW_NeuMeasu_Read_9_1/E_NOT_OK, DataServices_Data_DiagnServi_TABROW_NeuMeasu_Read_9_1/DCM_E_PENDING]
        arg OpStatus: type=Dcm_OpStatusType, direction=IN
        arg Data: type=Dcm_Data1ByteType, direction=OUT
      operation ConditionCheckRead: possible-error=[DataServices_Data_DiagnServi_TABROW_NeuMeasu_Read_9_1/E_NOT_OK, DataServices_Data_DiagnServi_TABROW_NeuMeasu_Read_9_1/DCM_E_PENDING]
        arg OpStatus: type=Dcm_OpStatusType, direction=IN
        arg ErrorCode: type=Dcm_NegativeResponseCodeType, direction=OUT
      error E_NOT_OK: error-code=1
      error DCM_E_PENDING: error-code=10
    DataServices_Data_TABROW_BatteTempeMaxim_ReadDataByIdent
      operation ReadData: possible-error=[DataServices_Data_TABROW_BatteTempeMaxim_ReadDataByIdent/E_NOT_OK, DataServices_Data_TABROW_BatteTempeMaxim_ReadDataByIdent/DCM_E_PENDING]
        arg OpStatus: type=Dcm_OpStatusType, direction=IN
        arg Data: type=Dcm_Data4ByteType, direction=OUT
      operation ConditionCheckRead: possible-error=[DataServices_Data_TABROW_BatteTempeMaxim_ReadDataByIdent/E_NOT_OK, DataServices_Data_TABROW_BatteTempeMaxim_ReadDataByIdent/DCM_E_PENDING]
        arg OpStatus: type=Dcm_OpStatusType, direction=IN
        arg ErrorCode: type=Dcm_NegativeResponseCodeType, direction=OUT
      error E_NOT_OK: error-code=1
      error DCM_E_PENDING: error-code=10
    DataServices_Data_DiagnServi_TABROW_NeuMeasu_Read_50
      operation ReadData: possible-error=[DataServices_Data_DiagnServi_TABROW_NeuMeasu_Read_50/E_NOT_OK, DataServices_Data_DiagnServi_TABROW_NeuMeasu_Read_50/DCM_E_PENDING]
        arg OpStatus: type=Dcm_OpStatusType, direction=IN
        arg Data: type=Dcm_Data2ByteType, direction=OUT
      operation ConditionCheckRead: possible-error=[DataServices_Data_DiagnServi_TABROW_NeuMeasu_Read_50/E_NOT_OK, DataServices_Data_DiagnServi_TABROW_NeuMeasu_Read_50/DCM_E_PENDING]
        arg OpStatus: type=Dcm_OpStatusType, direction=IN
        arg ErrorCode: type=Dcm_NegativeResponseCodeType, direction=OUT
      error E_NOT_OK: error-code=1
      error DCM_E_PENDING: error-code=10
    DataServices_Data_DiagnServi_Type_number_BCUe_Read
      operation ReadData: possible-error=[DataServices_Data_DiagnServi_Type_number_BCUe_Read/E_NOT_OK, DataServices_Data_DiagnServi_Type_number_BCUe_Read/DCM_E_PENDING]
        arg OpStatus: type=Dcm_OpStatusType, direction=IN
        arg Data: type=Dcm_Data11ByteType, direction=OUT
      operation ConditionCheckRead: possible-error=[DataServices_Data_DiagnServi_Type_number_BCUe_Read/E_NOT_OK, DataServices_Data_DiagnServi_Type_number_BCUe_Read/DCM_E_PENDING]
        arg OpStatus: type=Dcm_OpStatusType, direction=IN
        arg ErrorCode: type=Dcm_NegativeResponseCodeType, direction=OUT
      operation WriteData: possible-error=[DataServices_Data_DiagnServi_Type_number_BCUe_Read/E_NOT_OK, DataServices_Data_DiagnServi_Type_number_BCUe_Read/DCM_E_PENDING]
        arg Data: type=Dcm_Data11ByteType, direction=IN
        arg OpStatus: type=Dcm_OpStatusType, direction=IN
        arg ErrorCode: type=Dcm_NegativeResponseCodeType, direction=OUT
      error E_NOT_OK: error-code=1
      error DCM_E_PENDING: error-code=10
    DataServices_Data_DiagnServi_TABROW_NeuMeasu_Read_53
      operation ReadData: possible-error=[DataServices_Data_DiagnServi_TABROW_NeuMeasu_Read_53/E_NOT_OK, DataServices_Data_DiagnServi_TABROW_NeuMeasu_Read_53/DCM_E_PENDING]
        arg OpStatus: type=Dcm_OpStatusType, direction=IN
        arg Data: type=Dcm_Data12ByteType, direction=OUT
      operation ConditionCheckRead: possible-error=[DataServices_Data_DiagnServi_TABROW_NeuMeasu_Read_53/E_NOT_OK, DataServices_Data_DiagnServi_TABROW_NeuMeasu_Read_53/DCM_E_PENDING]
        arg OpStatus: type=Dcm_OpStatusType, direction=IN
        arg ErrorCode: type=Dcm_NegativeResponseCodeType, direction=OUT
      error E_NOT_OK: error-code=1
      error DCM_E_PENDING: error-code=10
    DataServices_Data_DiagnServi_TABROW_NeuMeasu_Read_52
      operation ReadData: possible-error=[DataServices_Data_DiagnServi_TABROW_NeuMeasu_Read_52/E_NOT_OK, DataServices_Data_DiagnServi_TABROW_NeuMeasu_Read_52/DCM_E_PENDING]
        arg OpStatus: type=Dcm_OpStatusType, direction=IN
        arg Data: type=Dcm_Data48ByteType, direction=OUT
      operation ConditionCheckRead: possible-error=[DataServices_Data_DiagnServi_TABROW_NeuMeasu_Read_52/E_NOT_OK, DataServices_Data_DiagnServi_TABROW_NeuMeasu_Read_52/DCM_E_PENDING]
        arg OpStatus: type=Dcm_OpStatusType, direction=IN
        arg ErrorCode: type=Dcm_NegativeResponseCodeType, direction=OUT
      error E_NOT_OK: error-code=1
      error DCM_E_PENDING: error-code=10
    DataServices_Data_DiagnServi_TABROW_NeuMeasu_Read_51
      operation ReadData: possible-error=[DataServices_Data_DiagnServi_TABROW_NeuMeasu_Read_51/E_NOT_OK, DataServices_Data_DiagnServi_TABROW_NeuMeasu_Read_51/DCM_E_PENDING]
        arg OpStatus: type=Dcm_OpStatusType, direction=IN
        arg Data: type=Dcm_Data1ByteType, direction=OUT
      operation ConditionCheckRead: possible-error=[DataServices_Data_DiagnServi_TABROW_NeuMeasu_Read_51/E_NOT_OK, DataServices_Data_DiagnServi_TABROW_NeuMeasu_Read_51/DCM_E_PENDING]
        arg OpStatus: type=Dcm_OpStatusType, direction=IN
        arg ErrorCode: type=Dcm_NegativeResponseCodeType, direction=OUT
      error E_NOT_OK: error-code=1
      error DCM_E_PENDING: error-code=10
    DataServices_Data_DiagnServi_TABROW_NeuMeasu_Read_56
      operation ReadData: possible-error=[DataServices_Data_DiagnServi_TABROW_NeuMeasu_Read_56/E_NOT_OK, DataServices_Data_DiagnServi_TABROW_NeuMeasu_Read_56/DCM_E_PENDING]
        arg OpStatus: type=Dcm_OpStatusType, direction=IN
        arg Data: type=Dcm_Data1ByteType, direction=OUT
      operation ConditionCheckRead: possible-error=[DataServices_Data_DiagnServi_TABROW_NeuMeasu_Read_56/E_NOT_OK, DataServices_Data_DiagnServi_TABROW_NeuMeasu_Read_56/DCM_E_PENDING]
        arg OpStatus: type=Dcm_OpStatusType, direction=IN
        arg ErrorCode: type=Dcm_NegativeResponseCodeType, direction=OUT
      error E_NOT_OK: error-code=1
      error DCM_E_PENDING: error-code=10
    DataServices_Data_DiagnServi_TABROW_NeuMeasu_Read_55
      operation ReadData: possible-error=[DataServices_Data_DiagnServi_TABROW_NeuMeasu_Read_55/E_NOT_OK, DataServices_Data_DiagnServi_TABROW_NeuMeasu_Read_55/DCM_E_PENDING]
        arg OpStatus: type=Dcm_OpStatusType, direction=IN
        arg Data: type=Dcm_Data110ByteType, direction=OUT
      operation ConditionCheckRead: possible-error=[DataServices_Data_DiagnServi_TABROW_NeuMeasu_Read_55/E_NOT_OK, DataServices_Data_DiagnServi_TABROW_NeuMeasu_Read_55/DCM_E_PENDING]
        arg OpStatus: type=Dcm_OpStatusType, direction=IN
        arg ErrorCode: type=Dcm_NegativeResponseCodeType, direction=OUT
      error E_NOT_OK: error-code=1
      error DCM_E_PENDING: error-code=10
    DataServices_Data_DiagnServi_TABROW_NeuMeasu_Read_61
      operation ReadData: possible-error=[DataServices_Data_DiagnServi_TABROW_NeuMeasu_Read_61/E_NOT_OK, DataServices_Data_DiagnServi_TABROW_NeuMeasu_Read_61/DCM_E_PENDING]
        arg OpStatus: type=Dcm_OpStatusType, direction=IN
        arg Data: type=Dcm_Data3ByteType, direction=OUT
      operation ConditionCheckRead: possible-error=[DataServices_Data_DiagnServi_TABROW_NeuMeasu_Read_61/E_NOT_OK, DataServices_Data_DiagnServi_TABROW_NeuMeasu_Read_61/DCM_E_PENDING]
        arg OpStatus: type=Dcm_OpStatusType, direction=IN
        arg ErrorCode: type=Dcm_NegativeResponseCodeType, direction=OUT
      error E_NOT_OK: error-code=1
      error DCM_E_PENDING: error-code=10
    DataServices_Data_DiagnServi_TABROW_NeuMeasu_Read_60
      operation ReadData: possible-error=[DataServices_Data_DiagnServi_TABROW_NeuMeasu_Read_60/E_NOT_OK, DataServices_Data_DiagnServi_TABROW_NeuMeasu_Read_60/DCM_E_PENDING]
        arg OpStatus: type=Dcm_OpStatusType, direction=IN
        arg Data: type=Dcm_Data2ByteType, direction=OUT
      operation ConditionCheckRead: possible-error=[DataServices_Data_DiagnServi_TABROW_NeuMeasu_Read_60/E_NOT_OK, DataServices_Data_DiagnServi_TABROW_NeuMeasu_Read_60/DCM_E_PENDING]
        arg OpStatus: type=Dcm_OpStatusType, direction=IN
        arg ErrorCode: type=Dcm_NegativeResponseCodeType, direction=OUT
      error E_NOT_OK: error-code=1
      error DCM_E_PENDING: error-code=10
    DataServices_Data_DiagnServi_TABROW_NeuMeasu_Read_63
      operation ReadData: possible-error=[DataServices_Data_DiagnServi_TABROW_NeuMeasu_Read_63/E_NOT_OK, DataServices_Data_DiagnServi_TABROW_NeuMeasu_Read_63/DCM_E_PENDING]
        arg OpStatus: type=Dcm_OpStatusType, direction=IN
        arg Data: type=Dcm_Data32ByteType, direction=OUT
      operation ConditionCheckRead: possible-error=[DataServices_Data_DiagnServi_TABROW_NeuMeasu_Read_63/E_NOT_OK, DataServices_Data_DiagnServi_TABROW_NeuMeasu_Read_63/DCM_E_PENDING]
        arg OpStatus: type=Dcm_OpStatusType, direction=IN
        arg ErrorCode: type=Dcm_NegativeResponseCodeType, direction=OUT
      error E_NOT_OK: error-code=1
      error DCM_E_PENDING: error-code=10
    DataServices_Data_DiagnServi_BMC_clamp_30c_Read
      operation ReadData: possible-error=[DataServices_Data_DiagnServi_BMC_clamp_30c_Read/E_NOT_OK, DataServices_Data_DiagnServi_BMC_clamp_30c_Read/DCM_E_PENDING]
        arg OpStatus: type=Dcm_OpStatusType, direction=IN
        arg Data: type=Dcm_Data1ByteType, direction=OUT
      operation ConditionCheckRead: possible-error=[DataServices_Data_DiagnServi_BMC_clamp_30c_Read/E_NOT_OK, DataServices_Data_DiagnServi_BMC_clamp_30c_Read/DCM_E_PENDING]
        arg OpStatus: type=Dcm_OpStatusType, direction=IN
        arg ErrorCode: type=Dcm_NegativeResponseCodeType, direction=OUT
      error E_NOT_OK: error-code=1
      error DCM_E_PENDING: error-code=10
    DataServices_Data_TABROW_CellVoltaSum_ReadDataByIdent
      operation ReadData: possible-error=[DataServices_Data_TABROW_CellVoltaSum_ReadDataByIdent/E_NOT_OK, DataServices_Data_TABROW_CellVoltaSum_ReadDataByIdent/DCM_E_PENDING]
        arg OpStatus: type=Dcm_OpStatusType, direction=IN
        arg Data: type=Dcm_Data2ByteType, direction=OUT
      operation ConditionCheckRead: possible-error=[DataServices_Data_TABROW_CellVoltaSum_ReadDataByIdent/E_NOT_OK, DataServices_Data_TABROW_CellVoltaSum_ReadDataByIdent/DCM_E_PENDING]
        arg OpStatus: type=Dcm_OpStatusType, direction=IN
        arg ErrorCode: type=Dcm_NegativeResponseCodeType, direction=OUT
      error E_NOT_OK: error-code=1
      error DCM_E_PENDING: error-code=10
    DataServices_Data_DiagnServi_TABROW_NeuMeasu_Read_27_3_1_1
      operation ReadData: possible-error=[DataServices_Data_DiagnServi_TABROW_NeuMeasu_Read_27_3_1_1/E_NOT_OK, DataServices_Data_DiagnServi_TABROW_NeuMeasu_Read_27_3_1_1/DCM_E_PENDING]
        arg OpStatus: type=Dcm_OpStatusType, direction=IN
        arg Data: type=Dcm_Data27ByteType, direction=OUT
      operation ConditionCheckRead: possible-error=[DataServices_Data_DiagnServi_TABROW_NeuMeasu_Read_27_3_1_1/E_NOT_OK, DataServices_Data_DiagnServi_TABROW_NeuMeasu_Read_27_3_1_1/DCM_E_PENDING]
        arg OpStatus: type=Dcm_OpStatusType, direction=IN
        arg ErrorCode: type=Dcm_NegativeResponseCodeType, direction=OUT
      error E_NOT_OK: error-code=1
      error DCM_E_PENDING: error-code=10
    DataServices_Data_Battery_isolation_measurement_actual_and_requested_state_Read_Data_By_Identifier
      operation ReadData: possible-error=[DataServices_Data_Battery_isolation_measurement_actual_and_requested_state_Read_Data_By_Identifier/E_NOT_OK, DataServices_Data_Battery_isolation_measurement_actual_and_requested_state_Read_Data_By_Identifier/DCM_E_PENDING]
        arg OpStatus: type=Dcm_OpStatusType, direction=IN
        arg Data: type=Dcm_Data2ByteType, direction=OUT
      operation ConditionCheckRead: possible-error=[DataServices_Data_Battery_isolation_measurement_actual_and_requested_state_Read_Data_By_Identifier/E_NOT_OK, DataServices_Data_Battery_isolation_measurement_actual_and_requested_state_Read_Data_By_Identifier/DCM_E_PENDING]
        arg OpStatus: type=Dcm_OpStatusType, direction=IN
        arg ErrorCode: type=Dcm_NegativeResponseCodeType, direction=OUT
      error E_NOT_OK: error-code=1
      error DCM_E_PENDING: error-code=10
    DataServices_Data_TABROW_ServiDiscoState_Read_Data_By_Identifier
      operation ReadData: possible-error=[DataServices_Data_TABROW_ServiDiscoState_Read_Data_By_Identifier/E_NOT_OK, DataServices_Data_TABROW_ServiDiscoState_Read_Data_By_Identifier/DCM_E_PENDING]
        arg OpStatus: type=Dcm_OpStatusType, direction=IN
        arg Data: type=Dcm_Data1ByteType, direction=OUT
      operation ConditionCheckRead: possible-error=[DataServices_Data_TABROW_ServiDiscoState_Read_Data_By_Identifier/E_NOT_OK, DataServices_Data_TABROW_ServiDiscoState_Read_Data_By_Identifier/DCM_E_PENDING]
        arg OpStatus: type=Dcm_OpStatusType, direction=IN
        arg ErrorCode: type=Dcm_NegativeResponseCodeType, direction=OUT
      error E_NOT_OK: error-code=1
      error DCM_E_PENDING: error-code=10
    SecurityAccess_Unlock_L1
      operation GetSeed: possible-error=[SecurityAccess_Unlock_L1/E_NOT_OK, SecurityAccess_Unlock_L1/DCM_E_PENDING]
        arg OpStatus: type=Dcm_OpStatusType, direction=IN
        arg Seed: type=Dcm_Data4ByteType, direction=OUT
        arg ErrorCode: type=Dcm_NegativeResponseCodeType, direction=OUT
      operation CompareKey: possible-error=[SecurityAccess_Unlock_L1/E_NOT_OK, SecurityAccess_Unlock_L1/DCM_E_PENDING, SecurityAccess_Unlock_L1/DCM_E_COMPARE_KEY_FAILED]
        arg Key: type=Dcm_Data4ByteType, direction=IN
        arg OpStatus: type=Dcm_OpStatusType, direction=IN
        arg ErrorCode: type=Dcm_NegativeResponseCodeType, direction=OUT
      error E_NOT_OK: error-code=1
      error DCM_E_PENDING: error-code=10
      error DCM_E_COMPARE_KEY_FAILED: error-code=11
    DataServices_Data_TABROW_RegulXSoftwIdentNumbe_Read
      operation ReadData: possible-error=[DataServices_Data_TABROW_RegulXSoftwIdentNumbe_Read/E_NOT_OK, DataServices_Data_TABROW_RegulXSoftwIdentNumbe_Read/DCM_E_PENDING]
        arg OpStatus: type=Dcm_OpStatusType, direction=IN
        arg Data: type=Dcm_Data50ByteType, direction=OUT
      operation ConditionCheckRead: possible-error=[DataServices_Data_TABROW_RegulXSoftwIdentNumbe_Read/E_NOT_OK, DataServices_Data_TABROW_RegulXSoftwIdentNumbe_Read/DCM_E_PENDING]
        arg OpStatus: type=Dcm_OpStatusType, direction=IN
        arg ErrorCode: type=Dcm_NegativeResponseCodeType, direction=OUT
      operation WriteData: possible-error=[DataServices_Data_TABROW_RegulXSoftwIdentNumbe_Read/E_NOT_OK, DataServices_Data_TABROW_RegulXSoftwIdentNumbe_Read/DCM_E_PENDING]
        arg Data: type=Dcm_Data50ByteType, direction=IN
        arg OpStatus: type=Dcm_OpStatusType, direction=IN
        arg ErrorCode: type=Dcm_NegativeResponseCodeType, direction=OUT
      error E_NOT_OK: error-code=1
      error DCM_E_PENDING: error-code=10
    DataServices_Data_TABROW_ConfiHash_Read
      operation ReadData: possible-error=[DataServices_Data_TABROW_ConfiHash_Read/E_NOT_OK, DataServices_Data_TABROW_ConfiHash_Read/DCM_E_PENDING]
        arg OpStatus: type=Dcm_OpStatusType, direction=IN
        arg Data: type=Dcm_Data32ByteType, direction=OUT
      operation ConditionCheckRead: possible-error=[DataServices_Data_TABROW_ConfiHash_Read/E_NOT_OK, DataServices_Data_TABROW_ConfiHash_Read/DCM_E_PENDING]
        arg OpStatus: type=Dcm_OpStatusType, direction=IN
        arg ErrorCode: type=Dcm_NegativeResponseCodeType, direction=OUT
      error E_NOT_OK: error-code=1
      error DCM_E_PENDING: error-code=10
    DataServices_Data_TABROW_VehicIdentNumbe_Read
      operation ReadData: possible-error=[DataServices_Data_TABROW_VehicIdentNumbe_Read/E_NOT_OK, DataServices_Data_TABROW_VehicIdentNumbe_Read/DCM_E_PENDING]
        arg OpStatus: type=Dcm_OpStatusType, direction=IN
        arg Data: type=Dcm_Data17ByteType, direction=OUT
      operation ConditionCheckRead: possible-error=[DataServices_Data_TABROW_VehicIdentNumbe_Read/E_NOT_OK, DataServices_Data_TABROW_VehicIdentNumbe_Read/DCM_E_PENDING]
        arg OpStatus: type=Dcm_OpStatusType, direction=IN
        arg ErrorCode: type=Dcm_NegativeResponseCodeType, direction=OUT
      error E_NOT_OK: error-code=1
      error DCM_E_PENDING: error-code=10
    DataServices_Data_TABROW_ProgrHash_Read
      operation ReadData: possible-error=[DataServices_Data_TABROW_ProgrHash_Read/E_NOT_OK, DataServices_Data_TABROW_ProgrHash_Read/DCM_E_PENDING]
        arg OpStatus: type=Dcm_OpStatusType, direction=IN
        arg Data: type=Dcm_Data32ByteType, direction=OUT
      operation ConditionCheckRead: possible-error=[DataServices_Data_TABROW_ProgrHash_Read/E_NOT_OK, DataServices_Data_TABROW_ProgrHash_Read/DCM_E_PENDING]
        arg OpStatus: type=Dcm_OpStatusType, direction=IN
        arg ErrorCode: type=Dcm_NegativeResponseCodeType, direction=OUT
      error E_NOT_OK: error-code=1
      error DCM_E_PENDING: error-code=10
  7 x mode switch interface, all with is-service=true, service-kind=DIAGNOSTIC-COMMUNICATION-MANAGER:
    Dcm_Read_ExtendedSFDRole
      mode group Dcm_Read_ExtendedSFDRole: type=ExtendedSFD
    Dcm_Read_EptiSFDRole
      mode group Dcm_Read_EptiSFDRole: type=EptiSFD
    Dcm_Read_E2eSFDRole
      mode group Dcm_Read_E2eSFDRole: type=E2eSFD
    Dcm_Read_OtaSFDRole
      mode group Dcm_Read_OtaSFDRole: type=OtaSFD
    Dcm_Read_SuperUserSFDRole
      mode group Dcm_Read_SuperUserSFDRole: type=SuperUserSFD
    Dcm_Read_BasicSFDRole
      mode group Dcm_Read_BasicSFDRole: type=BasicSFD
    Dcm_Read_ProductionSFDRole
      mode group Dcm_Read_ProductionSFDRole: type=ProductionSFD
  8 x client server interface, all with is-service=true, service-kind=DIAGNOSTIC-COMMUNICATION-MANAGER:
    DataServices_Data_TABROW_SFDDevelModeActiv_Read
      operation ReadData: possible-error=[DataServices_Data_TABROW_SFDDevelModeActiv_Read/E_NOT_OK, DataServices_Data_TABROW_SFDDevelModeActiv_Read/DCM_E_PENDING]
        arg OpStatus: type=Dcm_OpStatusType, direction=IN
        arg Data: type=Dcm_Data1ByteType, direction=OUT
      operation ConditionCheckRead: possible-error=[DataServices_Data_TABROW_SFDDevelModeActiv_Read/E_NOT_OK, DataServices_Data_TABROW_SFDDevelModeActiv_Read/DCM_E_PENDING]
        arg OpStatus: type=Dcm_OpStatusType, direction=IN
        arg ErrorCode: type=Dcm_NegativeResponseCodeType, direction=OUT
      operation WriteData: possible-error=[DataServices_Data_TABROW_SFDDevelModeActiv_Read/E_NOT_OK, DataServices_Data_TABROW_SFDDevelModeActiv_Read/DCM_E_PENDING]
        arg Data: type=Dcm_Data1ByteType, direction=IN
        arg OpStatus: type=Dcm_OpStatusType, direction=IN
        arg ErrorCode: type=Dcm_NegativeResponseCodeType, direction=OUT
      error E_NOT_OK: error-code=1
      error DCM_E_PENDING: error-code=10
    DataServices_Data_TABROW_VishnDID_Read
      operation ReadData: possible-error=[DataServices_Data_TABROW_VishnDID_Read/E_NOT_OK, DataServices_Data_TABROW_VishnDID_Read/DCM_E_PENDING]
        arg OpStatus: type=Dcm_OpStatusType, direction=IN
        arg Data: type=Dcm_Data100ByteType, direction=OUT
      operation ConditionCheckRead: possible-error=[DataServices_Data_TABROW_VishnDID_Read/E_NOT_OK, DataServices_Data_TABROW_VishnDID_Read/DCM_E_PENDING]
        arg OpStatus: type=Dcm_OpStatusType, direction=IN
        arg ErrorCode: type=Dcm_NegativeResponseCodeType, direction=OUT
      error E_NOT_OK: error-code=1
      error DCM_E_PENDING: error-code=10
    DataServices_Data_Vishnu_DID
      operation ReadData: possible-error=[DataServices_Data_Vishnu_DID/E_NOT_OK, DataServices_Data_Vishnu_DID/DCM_E_PENDING]
        arg OpStatus: type=Dcm_OpStatusType, direction=IN
        arg Data: type=Dcm_Data8ByteType, direction=OUT
      operation ConditionCheckRead: possible-error=[DataServices_Data_Vishnu_DID/E_NOT_OK, DataServices_Data_Vishnu_DID/DCM_E_PENDING]
        arg OpStatus: type=Dcm_OpStatusType, direction=IN
        arg ErrorCode: type=Dcm_NegativeResponseCodeType, direction=OUT
      operation WriteData: possible-error=[DataServices_Data_Vishnu_DID/E_NOT_OK, DataServices_Data_Vishnu_DID/DCM_E_PENDING]
        arg Data: type=Dcm_Data8ByteType, direction=IN
        arg OpStatus: type=Dcm_OpStatusType, direction=IN
        arg ErrorCode: type=Dcm_NegativeResponseCodeType, direction=OUT
      error E_NOT_OK: error-code=1
      error DCM_E_PENDING: error-code=10
    DataServices_Data_TABROW_CanTPData_Read
      operation ReadData: possible-error=[DataServices_Data_TABROW_CanTPData_Read/E_NOT_OK, DataServices_Data_TABROW_CanTPData_Read/DCM_E_PENDING]
        arg OpStatus: type=Dcm_OpStatusType, direction=IN
        arg Data: type=Dcm_Data150ByteType, direction=OUT
      operation ConditionCheckRead: possible-error=[DataServices_Data_TABROW_CanTPData_Read/E_NOT_OK, DataServices_Data_TABROW_CanTPData_Read/DCM_E_PENDING]
        arg OpStatus: type=Dcm_OpStatusType, direction=IN
        arg ErrorCode: type=Dcm_NegativeResponseCodeType, direction=OUT
      operation WriteData: possible-error=[DataServices_Data_TABROW_CanTPData_Read/E_NOT_OK, DataServices_Data_TABROW_CanTPData_Read/DCM_E_PENDING]
        arg Data: type=Dcm_Data150ByteType, direction=IN
        arg OpStatus: type=Dcm_OpStatusType, direction=IN
        arg ErrorCode: type=Dcm_NegativeResponseCodeType, direction=OUT
      error E_NOT_OK: error-code=1
      error DCM_E_PENDING: error-code=10
    DataServices_Data_TABROW_PIMDID_Read
      operation ReadData: possible-error=[DataServices_Data_TABROW_PIMDID_Read/E_NOT_OK, DataServices_Data_TABROW_PIMDID_Read/DCM_E_PENDING]
        arg OpStatus: type=Dcm_OpStatusType, direction=IN
        arg Data: type=Dcm_Data10ByteType, direction=OUT
      operation ConditionCheckRead: possible-error=[DataServices_Data_TABROW_PIMDID_Read/E_NOT_OK, DataServices_Data_TABROW_PIMDID_Read/DCM_E_PENDING]
        arg OpStatus: type=Dcm_OpStatusType, direction=IN
        arg ErrorCode: type=Dcm_NegativeResponseCodeType, direction=OUT
      operation WriteData: possible-error=[DataServices_Data_TABROW_PIMDID_Read/E_NOT_OK, DataServices_Data_TABROW_PIMDID_Read/DCM_E_PENDING]
        arg Data: type=Dcm_Data10ByteType, direction=IN
        arg OpStatus: type=Dcm_OpStatusType, direction=IN
        arg ErrorCode: type=Dcm_NegativeResponseCodeType, direction=OUT
      error E_NOT_OK: error-code=1
      error DCM_E_PENDING: error-code=10
    RoutineServices_Routine_DiagnServi_TABROW_NewRoutiBasicSetti_Start_Routine
      operation Start: possible-error=[RoutineServices_Routine_DiagnServi_TABROW_NewRoutiBasicSetti_Start_Routine/E_NOT_OK, RoutineServices_Routine_DiagnServi_TABROW_NewRoutiBasicSetti_Start_Routine/DCM_E_PENDING, RoutineServices_Routine_DiagnServi_TABROW_NewRoutiBasicSetti_Start_Routine/DCM_E_FORCE_RCRRP]
        arg OpStatus: type=Dcm_OpStatusType, direction=IN
        arg ResData: type=Dcm_StartDataOut_Routine_DiagnServi_TABROW_NewRoutiBasicSetti_Start_Routine_ResDataType, direction=OUT
        arg ErrorCode: type=Dcm_NegativeResponseCodeType, direction=OUT
      operation Stop: possible-error=[RoutineServices_Routine_DiagnServi_TABROW_NewRoutiBasicSetti_Start_Routine/E_NOT_OK, RoutineServices_Routine_DiagnServi_TABROW_NewRoutiBasicSetti_Start_Routine/DCM_E_PENDING, RoutineServices_Routine_DiagnServi_TABROW_NewRoutiBasicSetti_Start_Routine/DCM_E_FORCE_RCRRP]
        arg OpStatus: type=Dcm_OpStatusType, direction=IN
        arg ResData: type=Dcm_StopDataOut_Routine_DiagnServi_TABROW_NewRoutiBasicSetti_Start_Routine_ResDataType, direction=OUT
        arg ErrorCode: type=Dcm_NegativeResponseCodeType, direction=OUT
      operation RequestResults: possible-error=[RoutineServices_Routine_DiagnServi_TABROW_NewRoutiBasicSetti_Start_Routine/E_NOT_OK, RoutineServices_Routine_DiagnServi_TABROW_NewRoutiBasicSetti_Start_Routine/DCM_E_PENDING, RoutineServices_Routine_DiagnServi_TABROW_NewRoutiBasicSetti_Start_Routine/DCM_E_FORCE_RCRRP]
        arg OpStatus: type=Dcm_OpStatusType, direction=IN
        arg ResData: type=Dcm_RequestDataOut_Routine_DiagnServi_TABROW_NewRoutiBasicSetti_Start_Routine_ResDataType, direction=OUT
        arg ErrorCode: type=Dcm_NegativeResponseCodeType, direction=OUT
      error E_NOT_OK: error-code=1
      error DCM_E_PENDING: error-code=10
      error DCM_E_FORCE_RCRRP: error-code=12
    SecurityAccess_UnLock_L2
      operation GetSeed: possible-error=[SecurityAccess_UnLock_L2/E_NOT_OK, SecurityAccess_UnLock_L2/DCM_E_PENDING]
        arg OpStatus: type=Dcm_OpStatusType, direction=IN
        arg Seed: type=Dcm_Data4ByteType, direction=OUT
        arg ErrorCode: type=Dcm_NegativeResponseCodeType, direction=OUT
      operation CompareKey: possible-error=[SecurityAccess_UnLock_L2/E_NOT_OK, SecurityAccess_UnLock_L2/DCM_E_PENDING, SecurityAccess_UnLock_L2/DCM_E_COMPARE_KEY_FAILED]
        arg Key: type=Dcm_Data4ByteType, direction=IN
        arg OpStatus: type=Dcm_OpStatusType, direction=IN
        arg ErrorCode: type=Dcm_NegativeResponseCodeType, direction=OUT
      error E_NOT_OK: error-code=1
      error DCM_E_PENDING: error-code=10
      error DCM_E_COMPARE_KEY_FAILED: error-code=11
    DataServices_Data_TABROW_HVBatteBackFlowTempeWrite_Read
      operation ReadData: possible-error=[DataServices_Data_TABROW_HVBatteBackFlowTempeWrite_Read/E_NOT_OK, DataServices_Data_TABROW_HVBatteBackFlowTempeWrite_Read/DCM_E_PENDING]
        arg OpStatus: type=Dcm_OpStatusType, direction=IN
        arg Data: type=Dcm_Data8ByteType, direction=OUT
      operation ConditionCheckRead: possible-error=[DataServices_Data_TABROW_HVBatteBackFlowTempeWrite_Read/E_NOT_OK, DataServices_Data_TABROW_HVBatteBackFlowTempeWrite_Read/DCM_E_PENDING]
        arg OpStatus: type=Dcm_OpStatusType, direction=IN
        arg ErrorCode: type=Dcm_NegativeResponseCodeType, direction=OUT
      error E_NOT_OK: error-code=1
      error DCM_E_PENDING: error-code=10
package /MICROSAR/Dcm_swc/ComponentTypes
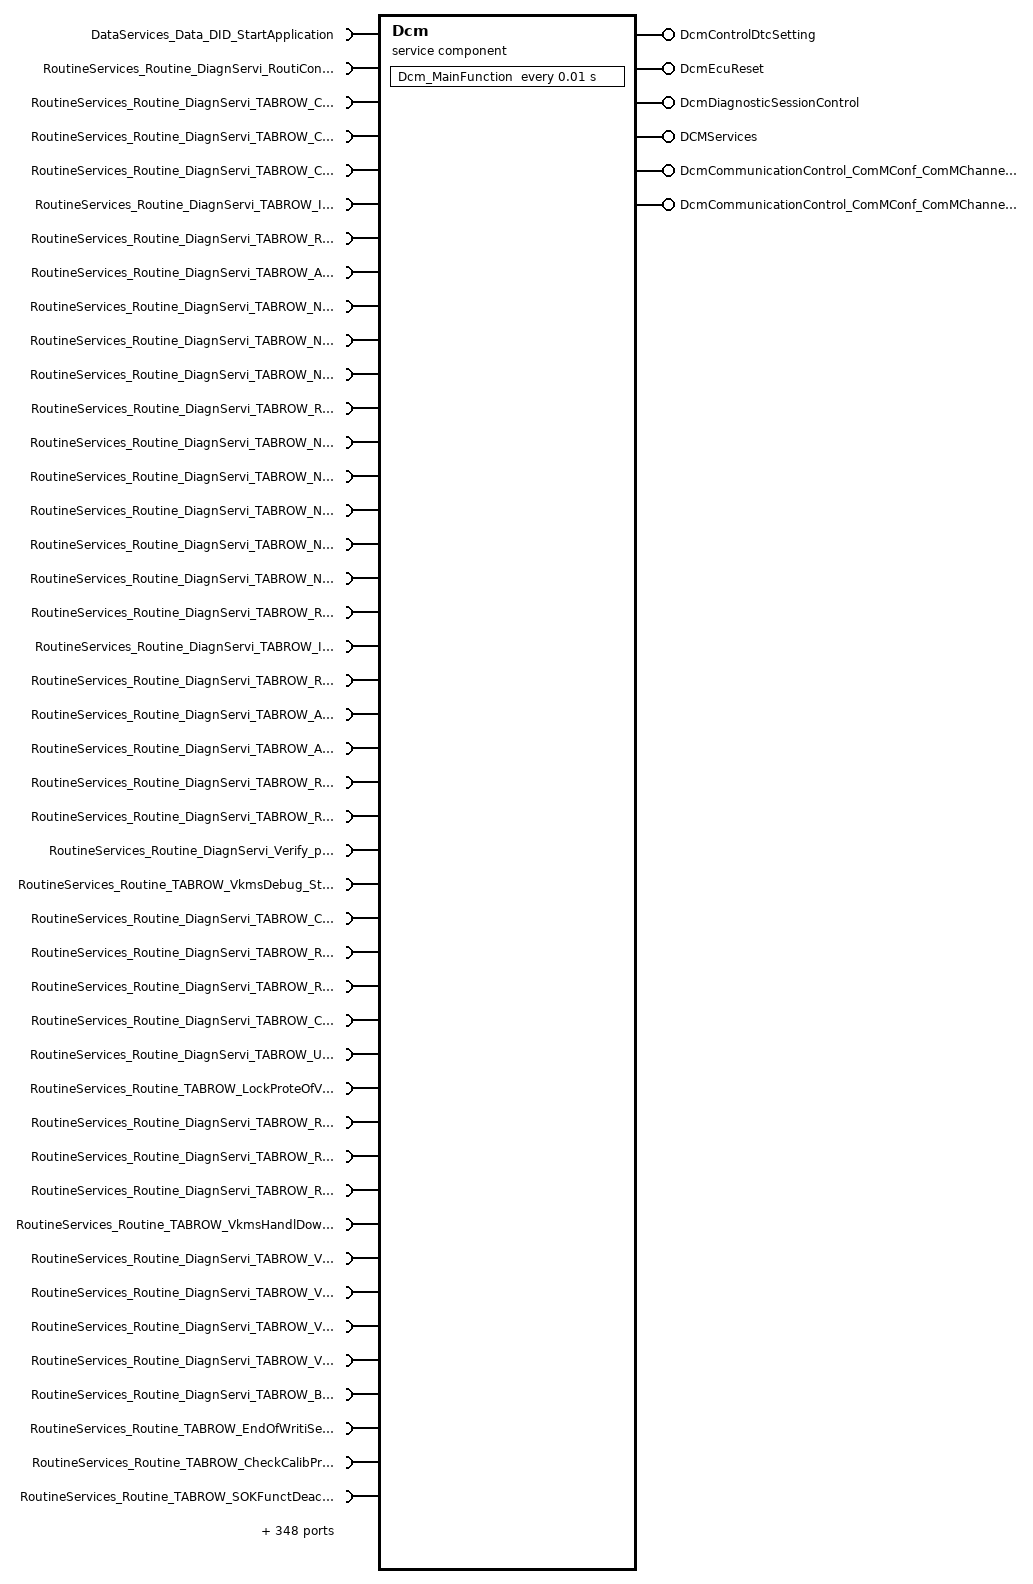
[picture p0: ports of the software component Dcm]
  service sw component type Dcm: category=SERVICE_COMPONENT
    4 x provide port:
      DcmControlDtcSetting: provided-interface=DcmControlDtcSetting
      DcmEcuReset: mode-switch-sender-com-spec{mode-group=DcmEcuReset, mode-switched-ack=timeout=0}, provided-interface=DcmEcuReset
      DcmDiagnosticSessionControl: provided-interface=DcmDiagnosticSessionControl
      DCMServices: provided-interface=DCMServices
    require port DataServices_Data_DID_StartApplication: required-interface=DataServices_Data_DID_StartApplication
    provide port DcmCommunicationControl_ComMConf_ComMChannel_CN_BMC_CAN01_78a85e89: provided-interface=DcmCommunicationControl_ComMConf_ComMChannel_CN_BMC_CAN01_78a85e89
    provide port DcmCommunicationControl_ComMConf_ComMChannel_CN_HCP5_CANFD01_54d90215: provided-interface=DcmCommunicationControl_ComMConf_ComMChannel_CN_HCP5_CANFD01_54d90215
    393 x require port:
      RoutineServices_Routine_DiagnServi_RoutiContrCheckProgrPreco: required-interface=RoutineServices_Routine_DiagnServi_RoutiContrCheckProgrPreco
      RoutineServices_Routine_DiagnServi_TABROW_CalcuIntegValidData_Start_Routine: required-interface=RoutineServices_Routine_DiagnServi_TABROW_CalcuIntegValidData_Start_Routine
      RoutineServices_Routine_DiagnServi_TABROW_CalcuIndivHashValue_Start_Routine: required-interface=RoutineServices_Routine_DiagnServi_TABROW_CalcuIndivHashValue_Start_Routine
      RoutineServices_Routine_DiagnServi_TABROW_CalcuModulHashValue_Start_Routine_COP: required-interface=RoutineServices_Routine_DiagnServi_TABROW_CalcuModulHashValue_Start_Routine_COP
      RoutineServices_Routine_DiagnServi_TABROW_IsolaMeasuDeactMode_Start_Routine: required-interface=RoutineServices_Routine_DiagnServi_TABROW_IsolaMeasuDeactMode_Start_Routine
      RoutineServices_Routine_DiagnServi_TABROW_ResetOfContaError_Start_Routine: required-interface=RoutineServices_Routine_DiagnServi_TABROW_ResetOfContaError_Start_Routine
      RoutineServices_Routine_DiagnServi_TABROW_AdaptOfVoltaMeasuChann_Start_Routine: required-interface=RoutineServices_Routine_DiagnServi_TABROW_AdaptOfVoltaMeasuChann_Start_Routine
      RoutineServices_Routine_DiagnServi_TABROW_NeuRoutiBasicSetti_Start_Routine_1: required-interface=RoutineServices_Routine_DiagnServi_TABROW_NeuRoutiBasicSetti_Start_Routine_1
      RoutineServices_Routine_DiagnServi_TABROW_NeuRoutiBasicSetti_Start_Routine_3: required-interface=RoutineServices_Routine_DiagnServi_TABROW_NeuRoutiBasicSetti_Start_Routine_3
      RoutineServices_Routine_DiagnServi_TABROW_NeuRoutiBasicSetti_Start_Routine_2: required-interface=RoutineServices_Routine_DiagnServi_TABROW_NeuRoutiBasicSetti_Start_Routine_2
      RoutineServices_Routine_DiagnServi_TABROW_ResetOfModulParam_Start_Routine: required-interface=RoutineServices_Routine_DiagnServi_TABROW_ResetOfModulParam_Start_Routine
      RoutineServices_Routine_DiagnServi_TABROW_NeuRoutiBasicSetti_Start_Routine: required-interface=RoutineServices_Routine_DiagnServi_TABROW_NeuRoutiBasicSetti_Start_Routine
      RoutineServices_Routine_DiagnServi_TABROW_NeuRoutiBasicSetti_Start_Routine_4: required-interface=RoutineServices_Routine_DiagnServi_TABROW_NeuRoutiBasicSetti_Start_Routine_4
      RoutineServices_Routine_DiagnServi_TABROW_NeuRoutiImmedResul_Start_Routine: required-interface=RoutineServices_Routine_DiagnServi_TABROW_NeuRoutiImmedResul_Start_Routine
      RoutineServices_Routine_DiagnServi_TABROW_NeuRoutiBasicSetti_Start_Routine_5: required-interface=RoutineServices_Routine_DiagnServi_TABROW_NeuRoutiBasicSetti_Start_Routine_5
      RoutineServices_Routine_DiagnServi_TABROW_NeuRoutiBasicSetti_Start_Routine_4_2: required-interface=RoutineServices_Routine_DiagnServi_TABROW_NeuRoutiBasicSetti_Start_Routine_4_2
      RoutineServices_Routine_DiagnServi_TABROW_ResetHVBatteAfterSepar_Start_Routine: required-interface=RoutineServices_Routine_DiagnServi_TABROW_ResetHVBatteAfterSepar_Start_Routine
      RoutineServices_Routine_DiagnServi_TABROW_IsolaMeasuDeactMode_Start_Routine_1: required-interface=RoutineServices_Routine_DiagnServi_TABROW_IsolaMeasuDeactMode_Start_Routine_1
      RoutineServices_Routine_DiagnServi_TABROW_ResetOfAllAdapt_Start_Routine_COP: required-interface=RoutineServices_Routine_DiagnServi_TABROW_ResetOfAllAdapt_Start_Routine_COP
      RoutineServices_Routine_DiagnServi_TABROW_AdaptOfBatteBankMode_Start_Routine: required-interface=RoutineServices_Routine_DiagnServi_TABROW_AdaptOfBatteBankMode_Start_Routine
      RoutineServices_Routine_DiagnServi_TABROW_AdaptOfCellBalan_Start_Routine: required-interface=RoutineServices_Routine_DiagnServi_TABROW_AdaptOfCellBalan_Start_Routine
      RoutineServices_Routine_DiagnServi_TABROW_ResetToFactoSetti_Start_Routine_COP: required-interface=RoutineServices_Routine_DiagnServi_TABROW_ResetToFactoSetti_Start_Routine_COP
      RoutineServices_Routine_DiagnServi_TABROW_ResetHardCrashFlag_Start_Routine: required-interface=RoutineServices_Routine_DiagnServi_TABROW_ResetHardCrashFlag_Start_Routine
      RoutineServices_Routine_DiagnServi_Verify_partial_software_checksum_Start_Routine: required-interface=RoutineServices_Routine_DiagnServi_Verify_partial_software_checksum_Start_Routine
      RoutineServices_Routine_TABROW_VkmsDebug_Start_Routine: required-interface=RoutineServices_Routine_TABROW_VkmsDebug_Start_Routine
      RoutineServices_Routine_DiagnServi_TABROW_ClearDowngProteData_Start_Routine_COP: required-interface=RoutineServices_Routine_DiagnServi_TABROW_ClearDowngProteData_Start_Routine_COP
      RoutineServices_Routine_DiagnServi_TABROW_ResetHealiInhib_Start_Routine: required-interface=RoutineServices_Routine_DiagnServi_TABROW_ResetHealiInhib_Start_Routine
      RoutineServices_Routine_DiagnServi_TABROW_RequeConfiOfProteOfVehicDiagn_Start_Routine: required-interface=RoutineServices_Routine_DiagnServi_TABROW_RequeConfiOfProteOfVehicDiagn_Start_Routine
      RoutineServices_Routine_DiagnServi_TABROW_CalcuConfiStateFingeOfProteOfVehicDiagn_Start_Routine: required-interface=RoutineServices_Routine_DiagnServi_TABROW_CalcuConfiStateFingeOfProteOfVehicDiagn_Start_Routine
      RoutineServices_Routine_DiagnServi_TABROW_UnlocProteOfVehicDiagn_Start_Routine: required-interface=RoutineServices_Routine_DiagnServi_TABROW_UnlocProteOfVehicDiagn_Start_Routine
      RoutineServices_Routine_TABROW_LockProteOfVehicDiagn_Start_Routine: required-interface=RoutineServices_Routine_TABROW_LockProteOfVehicDiagn_Start_Routine
      RoutineServices_Routine_DiagnServi_TABROW_ResetProteOfVehicDiagn_Start_Routine: required-interface=RoutineServices_Routine_DiagnServi_TABROW_ResetProteOfVehicDiagn_Start_Routine
      RoutineServices_Routine_DiagnServi_TABROW_RequeDataOfProteOfVehicDiagn_Start_Routine: required-interface=RoutineServices_Routine_DiagnServi_TABROW_RequeDataOfProteOfVehicDiagn_Start_Routine
      RoutineServices_Routine_DiagnServi_TABROW_RequeLoggiDataOfProteOfVehicDiagn_Start_Routine: required-interface=RoutineServices_Routine_DiagnServi_TABROW_RequeLoggiDataOfProteOfVehicDiagn_Start_Routine
      RoutineServices_Routine_TABROW_VkmsHandlDownl_Start_Routine: required-interface=RoutineServices_Routine_TABROW_VkmsHandlDownl_Start_Routine
      RoutineServices_Routine_DiagnServi_TABROW_VkmsCheckVerifHash_Start_Routine: required-interface=RoutineServices_Routine_DiagnServi_TABROW_VkmsCheckVerifHash_Start_Routine
      RoutineServices_Routine_DiagnServi_TABROW_VkmsGetIdentHash_Start_Routine: required-interface=RoutineServices_Routine_DiagnServi_TABROW_VkmsGetIdentHash_Start_Routine
      RoutineServices_Routine_DiagnServi_TABROW_VkmsGetPssHash_Start_Routine: required-interface=RoutineServices_Routine_DiagnServi_TABROW_VkmsGetPssHash_Start_Routine
      RoutineServices_Routine_DiagnServi_TABROW_VkmsGetState_Start_Routine: required-interface=RoutineServices_Routine_DiagnServi_TABROW_VkmsGetState_Start_Routine
      RoutineServices_Routine_DiagnServi_TABROW_BeginOfWritiOfSecurDataOfProteOfVehicDiagn_Start_Routine: required-interface=RoutineServices_Routine_DiagnServi_TABROW_BeginOfWritiOfSecurDataOfProteOfVehicDiagn_Start_Routine
      RoutineServices_Routine_TABROW_EndOfWritiSecurDataOfProteOfVehicDiagn_Start_Routine: required-interface=RoutineServices_Routine_TABROW_EndOfWritiSecurDataOfProteOfVehicDiagn_Start_Routine
      RoutineServices_Routine_TABROW_CheckCalibPreCondi_Start_Routine: required-interface=RoutineServices_Routine_TABROW_CheckCalibPreCondi_Start_Routine
      RoutineServices_Routine_TABROW_SOKFunctDeact_Start_Routine_COP: required-interface=RoutineServices_Routine_TABROW_SOKFunctDeact_Start_Routine_COP
      RoutineServices_Routine_Get_Energy_from_SOC_Start_Routine: required-interface=RoutineServices_Routine_Get_Energy_from_SOC_Start_Routine
      RoutineServices_Routine_DiagnServi_Get_Charge_Power_Start_Routine: required-interface=RoutineServices_Routine_DiagnServi_Get_Charge_Power_Start_Routine
      RoutineServices_Routine_DiagnServi_RoutiContrCheckProgrDepen: required-interface=RoutineServices_Routine_DiagnServi_RoutiContrCheckProgrDepen
      DataServices_Data_HV_battery_continuous_charging_power_Read_Data_By_Identifier: required-interface=DataServices_Data_HV_battery_continuous_charging_power_Read_Data_By_Identifier
      DataServices_Data_HV_battery_performance_indicator_discharging_Read_Data_By_Identifier: required-interface=DataServices_Data_HV_battery_performance_indicator_discharging_Read_Data_By_Identifier
      DataServices_Data_BMC_Mode_Read_Data_By_Identifier: required-interface=DataServices_Data_BMC_Mode_Read_Data_By_Identifier
      DataServices_Data_DiagnServi_TABROW_NeuMeasu_Read_59_2: required-interface=DataServices_Data_DiagnServi_TABROW_NeuMeasu_Read_59_2
      DataServices_Data_TABROW_TABROSyste_Read_1_1_1_1_1_1_1: required-interface=DataServices_Data_TABROW_TABROSyste_Read_1_1_1_1_1_1_1
      DataServices_Data_TABROW_SOKSignaFaileList_Read_Data_By_Identifier: required-interface=DataServices_Data_TABROW_SOKSignaFaileList_Read_Data_By_Identifier
      DataServices_Data_DiagnServi_TABROW_NeuMeasu_Read_46_1_1_1_1_1: required-interface=DataServices_Data_DiagnServi_TABROW_NeuMeasu_Read_46_1_1_1_1_1
      DataServices_Data_TABROW_VWECUHardwVersiNumbe_Read: required-interface=DataServices_Data_TABROW_VWECUHardwVersiNumbe_Read
      DataServices_Data_DiagnServi_TABROW_NeuMeasu_Read_63_1_1_1: required-interface=DataServices_Data_DiagnServi_TABROW_NeuMeasu_Read_63_1_1_1
      DataServices_Data_TABROW_TABROSyste_Read_1_1_1_1_1_1: required-interface=DataServices_Data_TABROW_TABROSyste_Read_1_1_1_1_1_1
      DataServices_Data_DiagnServi_TABROW_NeuECUIdent_Read: required-interface=DataServices_Data_DiagnServi_TABROW_NeuECUIdent_Read
      DataServices_Data_DiagnServi_TABROW_NeuMeasu_Read_22_1: required-interface=DataServices_Data_DiagnServi_TABROW_NeuMeasu_Read_22_1
      DataServices_Data_TABROW_VWLogicSoftwBlockLockValue_Read: required-interface=DataServices_Data_TABROW_VWLogicSoftwBlockLockValue_Read
      DataServices_Data_DiagnServi_TABROW_NeuMeasu_Read_57_1: required-interface=DataServices_Data_DiagnServi_TABROW_NeuMeasu_Read_57_1
      DataServices_Data_TABROW_StatePCM_ReadDataByIdent: required-interface=DataServices_Data_TABROW_StatePCM_ReadDataByIdent
      DataServices_Data_DiagnServi_TABROW_SysteSupplIdent_Read: required-interface=DataServices_Data_DiagnServi_TABROW_SysteSupplIdent_Read
      DataServices_Data_High_voltage_battery_total_voltage_Read_Data_By_Identifier: required-interface=DataServices_Data_High_voltage_battery_total_voltage_Read_Data_By_Identifier
      DataServices_Data_Battery_technical_state_of_charge_Read_Data_By_Identifier: required-interface=DataServices_Data_Battery_technical_state_of_charge_Read_Data_By_Identifier
      DataServices_Data_DiagnServi_TABROW_NeuMeasu_Read_46_1: required-interface=DataServices_Data_DiagnServi_TABROW_NeuMeasu_Read_46_1
      DataServices_Data_TABROW_BMCHVKFehleHVIL_Read_Data_By_Identifier: required-interface=DataServices_Data_TABROW_BMCHVKFehleHVIL_Read_Data_By_Identifier
      DataServices_Data_DiagnServi_TABROW_VWAppliSoftwVersiNumbe_Read: required-interface=DataServices_Data_DiagnServi_TABROW_VWAppliSoftwVersiNumbe_Read
      DataServices_Data_HV_Spannung_Nebenverbraucher_Read_Data_By_Identifier: required-interface=DataServices_Data_HV_Spannung_Nebenverbraucher_Read_Data_By_Identifier
      DataServices_Data_TABROW_TABROSyste_Read_1_1_1_1_1_1_1_1: required-interface=DataServices_Data_TABROW_TABROSyste_Read_1_1_1_1_1_1_1_1
      DataServices_Data_DiagnServi_TABROW_EnginCoolaTempe_Read: required-interface=DataServices_Data_DiagnServi_TABROW_EnginCoolaTempe_Read
      DataServices_Data_TABROW_SOKTimeInfor_Read_Data_By_Identifier: required-interface=DataServices_Data_TABROW_SOKTimeInfor_Read_Data_By_Identifier
      DataServices_Data_Battery_banks_allowed_modes_Read_Data_By_Identifier: required-interface=DataServices_Data_Battery_banks_allowed_modes_Read_Data_By_Identifier
      DataServices_Data_Battery_flow_temperature_Read_Data_By_Identifier: required-interface=DataServices_Data_Battery_flow_temperature_Read_Data_By_Identifier
      DataServices_Data_DiagnServi_TABROW_NeuMeasu_Read_9_2_1_1: required-interface=DataServices_Data_DiagnServi_TABROW_NeuMeasu_Read_9_2_1_1
      DataServices_Data_DiagnServi_TABROW_NeuMeasu_Read_46_1_1: required-interface=DataServices_Data_DiagnServi_TABROW_NeuMeasu_Read_46_1_1
      DataServices_Data_DiagnServi_TABROW_NeuMeasu_Read_46_1_1_1: required-interface=DataServices_Data_DiagnServi_TABROW_NeuMeasu_Read_46_1_1_1
      DataServices_Data_Strommesung_Read_Data_By_Identifier: required-interface=DataServices_Data_Strommesung_Read_Data_By_Identifier
      DataServices_Data_BMC_Hybrid_Kundendienstfehler_Read_Data_By_Identifier: required-interface=DataServices_Data_BMC_Hybrid_Kundendienstfehler_Read_Data_By_Identifier
      DataServices_Data_TABROW_IsolaResisSysteMinus_ReadDataByIdent: required-interface=DataServices_Data_TABROW_IsolaResisSysteMinus_ReadDataByIdent
      DataServices_Data_DiagnServi_TABROW_NeuMeasu_Read_43_1_1_1_1_1: required-interface=DataServices_Data_DiagnServi_TABROW_NeuMeasu_Read_43_1_1_1_1_1
      DataServices_Data_BMC_IWU_Status_Read_Data_By_Identifier: required-interface=DataServices_Data_BMC_IWU_Status_Read_Data_By_Identifier
      DataServices_Data_DiagnServi_Type_number_BMCE_Read: required-interface=DataServices_Data_DiagnServi_Type_number_BMCE_Read
      DataServices_Data_HV_battery_continuous_discharge_power_Read_Data_By_Identifier: required-interface=DataServices_Data_HV_battery_continuous_discharge_power_Read_Data_By_Identifier
      DataServices_Data_DiagnServi_TABROW_BootlTPBlock_Read: required-interface=DataServices_Data_DiagnServi_TABROW_BootlTPBlock_Read
      DataServices_Data_DiagnServi_ReadDataByIdentVWLogicBlockDowngProteVersi: required-interface=DataServices_Data_DiagnServi_ReadDataByIdentVWLogicBlockDowngProteVersi
      DataServices_Data_DiagnServi_TABROW_NeuMeasu_Read_29_1_1_1_1: required-interface=DataServices_Data_DiagnServi_TABROW_NeuMeasu_Read_29_1_1_1_1
      DataServices_Data_TABROW_ModeOfProteOfVehicDiagn_ReadDataByIdentifier: required-interface=DataServices_Data_TABROW_ModeOfProteOfVehicDiagn_ReadDataByIdentifier
      DataServices_Data_TABROW_TABROSyste_Read_1_1_1_1_1_1_1_1_1_1_1_1_1: required-interface=DataServices_Data_TABROW_TABROSyste_Read_1_1_1_1_1_1_1_1_1_1_1_1_1
      DataServices_Data_Battery_energy_content_maximum_Read_Data_By_Identifier: required-interface=DataServices_Data_Battery_energy_content_maximum_Read_Data_By_Identifier
      DataServices_Data_DiagnServi_TABROW_TechnSpeciVersi_Read: required-interface=DataServices_Data_DiagnServi_TABROW_TechnSpeciVersi_Read
      DataServices_Data_BMC_Strom_Read_Data_By_Identifier: required-interface=DataServices_Data_BMC_Strom_Read_Data_By_Identifier
      DataServices_Data_DiagnServi_TABROW_UnlocStatuOfECUOfProteOfVehicDiagn_Read: required-interface=DataServices_Data_DiagnServi_TABROW_UnlocStatuOfECUOfProteOfVehicDiagn_Read
      DataServices_Data_DiagnServi_TABROW_DID0x0EF_Read: required-interface=DataServices_Data_DiagnServi_TABROW_DID0x0EF_Read
      DataServices_Data_DiagnServi_TABROW_ContrModulVolta_Read: required-interface=DataServices_Data_DiagnServi_TABROW_ContrModulVolta_Read
      DataServices_Data_TABROW_VkmsMissiKeyHisto_Read_Data_By_Identifier: required-interface=DataServices_Data_TABROW_VkmsMissiKeyHisto_Read_Data_By_Identifier
      DataServices_Data_DiagnServi_TABROW_AUTOSStandAppliSoftwIdent_Read: required-interface=DataServices_Data_DiagnServi_TABROW_AUTOSStandAppliSoftwIdent_Read
      DataServices_Data_DiagnServi_TABROW_TABRORespo_Read_Data_By_Identifier: required-interface=DataServices_Data_DiagnServi_TABROW_TABRORespo_Read_Data_By_Identifier
      DataServices_Data_Battery_energy_content_actual_Read_Data_By_Identifier: required-interface=DataServices_Data_Battery_energy_content_actual_Read_Data_By_Identifier
      DataServices_Data_TABROW_SOKGenerInfor_Read_Data_By_Identifier: required-interface=DataServices_Data_TABROW_SOKGenerInfor_Read_Data_By_Identifier
      DataServices_Data_DiagnServi_ReadDataByIdentVWLogicSoftwBlockVersi: required-interface=DataServices_Data_DiagnServi_ReadDataByIdentVWLogicSoftwBlockVersi
      DataServices_Data_HV_battery_maximum_charging_current_Read_Data_By_Identifier: required-interface=DataServices_Data_HV_battery_maximum_charging_current_Read_Data_By_Identifier
      DataServices_Data_DiagnServi_TABROW_VWFAZITIdentStrin_Read: required-interface=DataServices_Data_DiagnServi_TABROW_VWFAZITIdentStrin_Read
      DataServices_Data_DiagnServi_TABROW_NeuMeasu_Read_27_2_1: required-interface=DataServices_Data_DiagnServi_TABROW_NeuMeasu_Read_27_2_1
      DataServices_Data_TABROW_StateOfBatteShutoCrash_ReadDataByIdent: required-interface=DataServices_Data_TABROW_StateOfBatteShutoCrash_ReadDataByIdent
      DataServices_Data_BMC_Vorlade_Zielspannung_Read_Data_By_Identifier: required-interface=DataServices_Data_BMC_Vorlade_Zielspannung_Read_Data_By_Identifier
      DataServices_Data_TABROW_TABROSyste_Read_1_1_1_1_1_1_1_1_1_1: required-interface=DataServices_Data_TABROW_TABROSyste_Read_1_1_1_1_1_1_1_1_1_1
      DataServices_Data_DiagnServi_TABROW_NeuMeasu_Read_43_1_1_1_1_1_1_1: required-interface=DataServices_Data_DiagnServi_TABROW_NeuMeasu_Read_43_1_1_1_1_1_1_1
      DataServices_Data_HV_Battery_thermal_load_Read_Data_By_Identifier: required-interface=DataServices_Data_HV_Battery_thermal_load_Read_Data_By_Identifier
      DataServices_Data_DiagnServi_TABROW_NeuMeasu_Read_29_1_1_1_1_1: required-interface=DataServices_Data_DiagnServi_TABROW_NeuMeasu_Read_29_1_1_1_1_1
      DataServices_Data_Prozessorauslastung_Read_Data_By_Identifier: required-interface=DataServices_Data_Prozessorauslastung_Read_Data_By_Identifier
      DataServices_Data_State_Of_Charge_Battery_customer_Read_Data_By_Identifier: required-interface=DataServices_Data_State_Of_Charge_Battery_customer_Read_Data_By_Identifier
      DataServices_Data_DiagnServi_TABROW_ActivOfDevelMessa_Read: required-interface=DataServices_Data_DiagnServi_TABROW_ActivOfDevelMessa_Read
      DataServices_Data_DiagnServi_TABROW_NeuMeasu_Read_60_3: required-interface=DataServices_Data_DiagnServi_TABROW_NeuMeasu_Read_60_3
      DataServices_Data_DiagnServi_TABROW_NeuMeasu_Read_60_1: required-interface=DataServices_Data_DiagnServi_TABROW_NeuMeasu_Read_60_1
      DataServices_Data_DiagnServi_TABROW_CalcuLOADValue_Read: required-interface=DataServices_Data_DiagnServi_TABROW_CalcuLOADValue_Read
      DataServices_Data_HV_battery_performance_indicator_charging_Read_Data_By_Identifier: required-interface=DataServices_Data_HV_battery_performance_indicator_charging_Read_Data_By_Identifier
      DataServices_Data_Zero_Potential_Status_Read_Data_By_Identifier: required-interface=DataServices_Data_Zero_Potential_Status_Read_Data_By_Identifier
      DataServices_Data_DiagnServi_TABROW_NeuMeasu_Read_57_2_1: required-interface=DataServices_Data_DiagnServi_TABROW_NeuMeasu_Read_57_2_1
      DataServices_Data_DiagnServi_BMC_serial_number_Read: required-interface=DataServices_Data_DiagnServi_BMC_serial_number_Read
      DataServices_Data_HV_coordinator_requestet_voltage_hv_battery_Read_Data_By_Identifier: required-interface=DataServices_Data_HV_coordinator_requestet_voltage_hv_battery_Read_Data_By_Identifier
      DataServices_Data_DiagnServi_TABROW_DID0xEFD_Read_{1..3}: required-interface=DataServices_Data_DiagnServi_TABROW_DID0xEFD_Read_{1..3}
      DataServices_Data_DiagnServi_TABROW_NeuMeasu_Read_46_1_1_1_1: required-interface=DataServices_Data_DiagnServi_TABROW_NeuMeasu_Read_46_1_1_1_1
      DataServices_Data_TABROW_ECUStandMode1_Read: required-interface=DataServices_Data_TABROW_ECUStandMode1_Read
      DataServices_Data_TABROW_TABROSyste_Read_1_1_1_1_1: required-interface=DataServices_Data_TABROW_TABROSyste_Read_1_1_1_1_1
      DataServices_Data_DiagnServi_TABROW_NeuMeasu_Read_29_1: required-interface=DataServices_Data_DiagnServi_TABROW_NeuMeasu_Read_29_1
      DataServices_Data_DiagnServi_TABROW_NeuMeasu_Read_29_3: required-interface=DataServices_Data_DiagnServi_TABROW_NeuMeasu_Read_29_3
      DataServices_Data_DiagnServi_TABROW_NeuMeasu_Read_46_1_1_1_1_1_1_2_1: required-interface=DataServices_Data_DiagnServi_TABROW_NeuMeasu_Read_46_1_1_1_1_1_1_2_1
      DataServices_Data_DiagnServi_TABROW_NeuMeasu_Read_29_2: required-interface=DataServices_Data_DiagnServi_TABROW_NeuMeasu_Read_29_2
      DataServices_Data_DiagnServi_TABROW_NeuMeasu_Read_29_5: required-interface=DataServices_Data_DiagnServi_TABROW_NeuMeasu_Read_29_5
      DataServices_Data_DiagnServi_TABROW_NeuMeasu_Read_46_1_1_1_1_1_1_2_3: required-interface=DataServices_Data_DiagnServi_TABROW_NeuMeasu_Read_46_1_1_1_1_1_1_2_3
      DataServices_Data_DiagnServi_TABROW_NeuMeasu_Read_29_4: required-interface=DataServices_Data_DiagnServi_TABROW_NeuMeasu_Read_29_4
      DataServices_Data_DiagnServi_TABROW_NeuMeasu_Read_46_1_1_1_1_1_1_2_2: required-interface=DataServices_Data_DiagnServi_TABROW_NeuMeasu_Read_46_1_1_1_1_1_1_2_2
      DataServices_Data_DiagnServi_TABROW_MonitStatuThisDriviCycle_Read: required-interface=DataServices_Data_DiagnServi_TABROW_MonitStatuThisDriviCycle_Read
      DataServices_Data_TABROW_TABROSyste_Read_1_1_1_1_1_1_1_1_1: required-interface=DataServices_Data_TABROW_TABROSyste_Read_1_1_1_1_1_1_1_1_1
      DataServices_Data_TABROW_TABROSyste_Read_1_1_1: required-interface=DataServices_Data_TABROW_TABROSyste_Read_1_1_1
      DataServices_Data_DiagnServi_TABROW_VWAppliDataSetIdent_Read: required-interface=DataServices_Data_DiagnServi_TABROW_VWAppliDataSetIdent_Read
      DataServices_Data_DiagnServi_TABROW_NeuMeasu_Read_43_1_1_1_1_1_1_1_1: required-interface=DataServices_Data_DiagnServi_TABROW_NeuMeasu_Read_43_1_1_1_1_1_1_1_1
      DataServices_Data_TABROW_BatteTempeAvera_ReadDataByIdent: required-interface=DataServices_Data_TABROW_BatteTempeAvera_ReadDataByIdent
      DataServices_Data_HV_battery_maximum_discharge_current_Read_Data_By_Identifier: required-interface=DataServices_Data_HV_battery_maximum_discharge_current_Read_Data_By_Identifier
      DataServices_Data_DiagnServi_TABROW_NeuMeasu_Read_49_1: required-interface=DataServices_Data_DiagnServi_TABROW_NeuMeasu_Read_49_1
      DataServices_Data_TABROW_VWLogicSoftwBlockCountOfProgrAttem_Read: required-interface=DataServices_Data_TABROW_VWLogicSoftwBlockCountOfProgrAttem_Read
      DataServices_Data_DiagnServi_TABROW_VWSparePartNumbe_Read: required-interface=DataServices_Data_DiagnServi_TABROW_VWSparePartNumbe_Read
      DataServices_Data_Battery_banks_actual_voltage_Read_Data_By_Identifier: required-interface=DataServices_Data_Battery_banks_actual_voltage_Read_Data_By_Identifier
      DataServices_Data_DiagnServi_TABROW_ECUNA_Read: required-interface=DataServices_Data_DiagnServi_TABROW_ECUNA_Read
      DataServices_Data_HV_battery_maximum_charging_power_Read_Data_By_Identifier: required-interface=DataServices_Data_HV_battery_maximum_charging_power_Read_Data_By_Identifier
      DataServices_Data_DiagnServi_TABROW_NeuMeasu_Read_9_2_1_1_2: required-interface=DataServices_Data_DiagnServi_TABROW_NeuMeasu_Read_9_2_1_1_2
      DataServices_Data_DiagnServi_TABROW_NeuMeasu_Read_9_2_1_1_1: required-interface=DataServices_Data_DiagnServi_TABROW_NeuMeasu_Read_9_2_1_1_1
      DataServices_Data_DiagnServi_TABROW_NeuMeasu_Read_63_1_1: required-interface=DataServices_Data_DiagnServi_TABROW_NeuMeasu_Read_63_1_1
      DataServices_Data_DiagnServi_Module_part_number_Read: required-interface=DataServices_Data_DiagnServi_Module_part_number_Read
      DataServices_Data_Battery_displayed_state_of_charge_Read_Data_By_Identifier: required-interface=DataServices_Data_Battery_displayed_state_of_charge_Read_Data_By_Identifier
      DataServices_Data_DiagnServi_TABROW_NeuMeasu_Read_27_4_1: required-interface=DataServices_Data_DiagnServi_TABROW_NeuMeasu_Read_27_4_1
      DataServices_Data_DiagnServi_TABROW_NeuMeasu_Read_27_1: required-interface=DataServices_Data_DiagnServi_TABROW_NeuMeasu_Read_27_1
      DataServices_Data_DiagnServi_TABROW_NeuMeasu_Read_27_3: required-interface=DataServices_Data_DiagnServi_TABROW_NeuMeasu_Read_27_3
      DataServices_Data_DiagnServi_TABROW_NeuMeasu_Read_27_2: required-interface=DataServices_Data_DiagnServi_TABROW_NeuMeasu_Read_27_2
      DataServices_Data_DiagnServi_TABROW_NeuMeasu_Read_27_5: required-interface=DataServices_Data_DiagnServi_TABROW_NeuMeasu_Read_27_5
      DataServices_Data_DiagnServi_TABROW_NeuMeasu_Read_27_4: required-interface=DataServices_Data_DiagnServi_TABROW_NeuMeasu_Read_27_4
      DataServices_Data_DiagnServi_TABROW_NeuMeasu_Read_27_7: required-interface=DataServices_Data_DiagnServi_TABROW_NeuMeasu_Read_27_7
      DataServices_Data_DiagnServi_TABROW_NeuMeasu_Read_27_6: required-interface=DataServices_Data_DiagnServi_TABROW_NeuMeasu_Read_27_6
      DataServices_Data_DiagnServi_TABROW_NeuMeasu_Read_27_8: required-interface=DataServices_Data_DiagnServi_TABROW_NeuMeasu_Read_27_8
      DataServices_Data_TABROW_StandAmbieCondi_ReadDataByIdent: required-interface=DataServices_Data_TABROW_StandAmbieCondi_ReadDataByIdent
      DataServices_Data_DiagnServi_SOH_Read: required-interface=DataServices_Data_DiagnServi_SOH_Read
      DataServices_Data_DiagnServi_TABROW_DID0xEFD_Read_1_1_1: required-interface=DataServices_Data_DiagnServi_TABROW_DID0xEFD_Read_1_1_1
      DataServices_Data_DiagnServi_TABROW_NeuMeasu_Read_8_1: required-interface=DataServices_Data_DiagnServi_TABROW_NeuMeasu_Read_8_1
      DataServices_Data_DiagnServi_TABROW_NeuMeasu_Read_8_2: required-interface=DataServices_Data_DiagnServi_TABROW_NeuMeasu_Read_8_2
      DataServices_Data_DiagnServi_TABROW_ProduDeact_Read: required-interface=DataServices_Data_DiagnServi_TABROW_ProduDeact_Read
      DataServices_Data_DiagnServi_TABROW_NeuMeasu_Read_57_11: required-interface=DataServices_Data_DiagnServi_TABROW_NeuMeasu_Read_57_11
      DataServices_Data_DiagnServi_TABROW_NeuMeasu_Read_57_13: required-interface=DataServices_Data_DiagnServi_TABROW_NeuMeasu_Read_57_13
      DataServices_Data_DiagnServi_TABROW_NeuMeasu_Read_57_14: required-interface=DataServices_Data_DiagnServi_TABROW_NeuMeasu_Read_57_14
      DataServices_Data_DiagnServi_TABROW_AccelPedalPositD_Read: required-interface=DataServices_Data_DiagnServi_TABROW_AccelPedalPositD_Read
      DataServices_Data_DiagnServi_TABROW_Finge_Read: required-interface=DataServices_Data_DiagnServi_TABROW_Finge_Read
      DataServices_Data_TABROW_TABROSyste_Read_1_1: required-interface=DataServices_Data_TABROW_TABROSyste_Read_1_1
      DataServices_Data_TABROW_ECUStandMode2_Read: required-interface=DataServices_Data_TABROW_ECUStandMode2_Read
      DataServices_Data_DiagnServi_TABROW_NeuMeasu2_Read: required-interface=DataServices_Data_DiagnServi_TABROW_NeuMeasu2_Read
      DataServices_Data_DiagnServi_TABROW_NeuCalibData_Read: required-interface=DataServices_Data_DiagnServi_TABROW_NeuCalibData_Read
      DataServices_Data_DiagnServi_TABROW_NeuMeasu_Read_46_1_1_1_1_1_1: required-interface=DataServices_Data_DiagnServi_TABROW_NeuMeasu_Read_46_1_1_1_1_1_1
      DataServices_Data_DiagnServi_TABROW_TABROOBDDr_Read_Data_By_Identifier: required-interface=DataServices_Data_DiagnServi_TABROW_TABROOBDDr_Read_Data_By_Identifier
      DataServices_Data_DiagnServi_TABROW_NeuMeasu_Read_36_3: required-interface=DataServices_Data_DiagnServi_TABROW_NeuMeasu_Read_36_3
      DataServices_Data_DiagnServi_TABROW_NeuMeasu_Read_36_1: required-interface=DataServices_Data_DiagnServi_TABROW_NeuMeasu_Read_36_1
      DataServices_Data_DiagnServi_TABROW_NeuMeasu_Read_43_1_1_1_1_1_1_1_1_1_1: required-interface=DataServices_Data_DiagnServi_TABROW_NeuMeasu_Read_43_1_1_1_1_1_1_1_1_1_1
      DataServices_Data_DiagnServi_TABROW_NeuMeasu_Read_43_1_1_1_1_1_1: required-interface=DataServices_Data_DiagnServi_TABROW_NeuMeasu_Read_43_1_1_1_1_1_1
      DataServices_Data_TABROW_InUseMonitPerfoRatio_Read_Data_By_Identifier: required-interface=DataServices_Data_TABROW_InUseMonitPerfoRatio_Read_Data_By_Identifier
      DataServices_Data_DiagnServi_TABROW_NeuMeasu_Read_27_1_1_1_1: required-interface=DataServices_Data_DiagnServi_TABROW_NeuMeasu_Read_27_1_1_1_1
      DataServices_Data_TABROW_BMCHVKEoHVLState_Read_Data_By_Identifier: required-interface=DataServices_Data_TABROW_BMCHVKEoHVLState_Read_Data_By_Identifier
      DataServices_Data_DiagnServi_TABROW_NeuMeasu_Read_27_1_1_1_2: required-interface=DataServices_Data_DiagnServi_TABROW_NeuMeasu_Read_27_1_1_1_2
      DataServices_Data_DiagnServi_BMCE_part_number_Read: required-interface=DataServices_Data_DiagnServi_BMCE_part_number_Read
      DataServices_Data_DiagnServi_TABROW_NeuMeasu_Read_8: required-interface=DataServices_Data_DiagnServi_TABROW_NeuMeasu_Read_8
      DataServices_Data_DiagnServi_TABROW_NeuMeasu_Read_9: required-interface=DataServices_Data_DiagnServi_TABROW_NeuMeasu_Read_9
      DataServices_Data_TABROW_BMCHVKFehleInter_Read_Data_By_Identifier: required-interface=DataServices_Data_TABROW_BMCHVKFehleInter_Read_Data_By_Identifier
      DataServices_Data_DiagnServi_TABROW_NeuMeasu_Read_2: required-interface=DataServices_Data_DiagnServi_TABROW_NeuMeasu_Read_2
      DataServices_Data_DiagnServi_TABROW_NeuMeasu_Read_3: required-interface=DataServices_Data_DiagnServi_TABROW_NeuMeasu_Read_3
      DataServices_Data_TABROW_VkmsVkmsv_Read_Data_By_Identifier: required-interface=DataServices_Data_TABROW_VkmsVkmsv_Read_Data_By_Identifier
      DataServices_Data_DiagnServi_TABROW_NeuMeasu_Read_1: required-interface=DataServices_Data_DiagnServi_TABROW_NeuMeasu_Read_1
      DataServices_Data_DiagnServi_TABROW_NeuMeasu_Read_6: required-interface=DataServices_Data_DiagnServi_TABROW_NeuMeasu_Read_6
      DataServices_Data_TABROW_StatuProdu_Read_Data_By_Identifier: required-interface=DataServices_Data_TABROW_StatuProdu_Read_Data_By_Identifier
      DataServices_Data_DiagnServi_TABROW_NeuMeasu_Read_7: required-interface=DataServices_Data_DiagnServi_TABROW_NeuMeasu_Read_7
      DataServices_Data_DiagnServi_TABROW_NeuMeasu_Read_4: required-interface=DataServices_Data_DiagnServi_TABROW_NeuMeasu_Read_4
      DataServices_Data_DiagnServi_TABROW_NeuMeasu_Read_5: required-interface=DataServices_Data_DiagnServi_TABROW_NeuMeasu_Read_5
      DataServices_Data_TABROW_SysteIdent_Read: required-interface=DataServices_Data_TABROW_SysteIdent_Read
      DataServices_Data_DiagnServi_TABROW_MonitStatuSinceDTCsClear_Read: required-interface=DataServices_Data_DiagnServi_TABROW_MonitStatuSinceDTCsClear_Read
      DataServices_Data_TABROW_TABROSyste_Read_1_1_1_1_1_1_1_1_1_1_1_1_1_1_1: required-interface=DataServices_Data_TABROW_TABROSyste_Read_1_1_1_1_1_1_1_1_1_1_1_1_1_1_1
      DataServices_Data_DiagnServi_TABROW_NeuMeasu_Read_29_1_1_1_1_1_1: required-interface=DataServices_Data_DiagnServi_TABROW_NeuMeasu_Read_29_1_1_1_1_1_1
      DataServices_Data_DiagnServi_TABROW_DID0xEFD_Read: required-interface=DataServices_Data_DiagnServi_TABROW_DID0xEFD_Read
      DataServices_Data_DiagnServi_ReadDataByIdentASAMODXFileVersi: required-interface=DataServices_Data_DiagnServi_ReadDataByIdentASAMODXFileVersi
      DataServices_Data_DiagnServi_TABROW_AdaptOfChineSeriaNumbe_Read: required-interface=DataServices_Data_DiagnServi_TABROW_AdaptOfChineSeriaNumbe_Read
      DataServices_Data_BMC_Status_DCLS_Read_Data_By_Identifier: required-interface=DataServices_Data_BMC_Status_DCLS_Read_Data_By_Identifier
      DataServices_Data_TABROW_VkmsKeyList_Read_Data_By_Identifier: required-interface=DataServices_Data_TABROW_VkmsKeyList_Read_Data_By_Identifier
      DataServices_Data_DiagnServi_TABROW_Milea_Read: required-interface=DataServices_Data_DiagnServi_TABROW_Milea_Read
      DataServices_Data_DiagnServi_TABROW_VehicSpeedSenso_Read: required-interface=DataServices_Data_DiagnServi_TABROW_VehicSpeedSenso_Read
      DataServices_Data_DiagnServi_TABROW_NeuMeasu_Read_29_1_1_1_1_1_1_1: required-interface=DataServices_Data_DiagnServi_TABROW_NeuMeasu_Read_29_1_1_1_1_1_1_1
      DataServices_Data_DiagnServi_BCUe_part_number_Read: required-interface=DataServices_Data_DiagnServi_BCUe_part_number_Read
      DataServices_Data_DiagnServi_TABROW_IntegValidDataConfiList_Read: required-interface=DataServices_Data_DiagnServi_TABROW_IntegValidDataConfiList_Read
      DataServices_Data_TABROW_SOKFreshInfor_Read_Data_By_Identifier: required-interface=DataServices_Data_TABROW_SOKFreshInfor_Read_Data_By_Identifier
      DataServices_Data_DiagnServi_TABROW_NeuMeasu_Read_58_1: required-interface=DataServices_Data_DiagnServi_TABROW_NeuMeasu_Read_58_1
      DataServices_Data_DiagnServi_TABROW_NeuMeasu_Read_43_1_1_1_1_1_1_1_1_1: required-interface=DataServices_Data_DiagnServi_TABROW_NeuMeasu_Read_43_1_1_1_1_1_1_1_1_1
      DataServices_Data_Battery_return_flow_temperature_Read_Data_By_Identifier: required-interface=DataServices_Data_Battery_return_flow_temperature_Read_Data_By_Identifier
      DataServices_Data_DiagnServi_TABROW_NeuMeasu1_Read: required-interface=DataServices_Data_DiagnServi_TABROW_NeuMeasu1_Read
      DataServices_Data_DiagnServi_TABROW_NeuMeasu_Read_43_1: required-interface=DataServices_Data_DiagnServi_TABROW_NeuMeasu_Read_43_1
      DataServices_Data_TABROW_VWECUHardwNumbe_Read: required-interface=DataServices_Data_TABROW_VWECUHardwNumbe_Read
      DataServices_Data_DiagnServi_TABROW_NeuMeasu_Read_9_2_1: required-interface=DataServices_Data_DiagnServi_TABROW_NeuMeasu_Read_9_2_1
      DataServices_Data_Battery_banks_actual_mode_Read_Data_By_Identifier: required-interface=DataServices_Data_Battery_banks_actual_mode_Read_Data_By_Identifier
      DataServices_Data_DiagnServi_ReadDataByIdentASAMODXFileIdent: required-interface=DataServices_Data_DiagnServi_ReadDataByIdentASAMODXFileIdent
      DataServices_Data_DiagnServi_TABROW_NeuMeasu_Read_21_1: required-interface=DataServices_Data_DiagnServi_TABROW_NeuMeasu_Read_21_1
      DataServices_Data_DiagnServi_TABROW_NeuMeasu_Read_21_2: required-interface=DataServices_Data_DiagnServi_TABROW_NeuMeasu_Read_21_2
      DataServices_Data_DiagnServi_TABROW_NeuMeasu_Read_33_1_1_1_1_1_1_1_1_1_1_1_1_1_1_1_1_1_1_1_1_1_1_1_2_1_1_1: required-interface=DataServices_Data_DiagnServi_TABROW_NeuMeasu_Read_33_1_1_1_1_1_1_1_1_1_1_1_1_1_1_1_1_1_1_1_1_1_1_1_2_1_1_1
      DataServices_Data_TABROW_CellVoltaMinim_ReadDataByIdent: required-interface=DataServices_Data_TABROW_CellVoltaMinim_ReadDataByIdent
      DataServices_Data_DiagnServi_ReadDataByIdentBasicSettiStatu: required-interface=DataServices_Data_DiagnServi_ReadDataByIdentBasicSettiStatu
      DataServices_Data_DiagnServi_TABROW_NeuMeasu_Read_43_1_1_1_1: required-interface=DataServices_Data_DiagnServi_TABROW_NeuMeasu_Read_43_1_1_1_1
      DataServices_Data_TABROW_FingeAndProgrDateOfLogicSoftwBlock_Read: required-interface=DataServices_Data_TABROW_FingeAndProgrDateOfLogicSoftwBlock_Read
      DataServices_Data_DiagnServi_TABROW_NeuMeasu_Read_30_2: required-interface=DataServices_Data_DiagnServi_TABROW_NeuMeasu_Read_30_2
      DataServices_Data_DiagnServi_TABROW_NeuMeasu_Read_30_3: required-interface=DataServices_Data_DiagnServi_TABROW_NeuMeasu_Read_30_3
      DataServices_Data_DiagnServi_TABROW_ActivDiagnSessi_Read: required-interface=DataServices_Data_DiagnServi_TABROW_ActivDiagnSessi_Read
      DataServices_Data_TABROW_VWSysteNameOrEnginType_Read: required-interface=DataServices_Data_TABROW_VWSysteNameOrEnginType_Read
      DataServices_Data_DiagnServi_TABROW_NeuMeasu_Read_27_1_1_1_1_1: required-interface=DataServices_Data_DiagnServi_TABROW_NeuMeasu_Read_27_1_1_1_1_1
      DataServices_Data_DiagnServi_TABROW_NeuMeasu_Read_43_1_1_1: required-interface=DataServices_Data_DiagnServi_TABROW_NeuMeasu_Read_43_1_1_1
      DataServices_Data_HV_battery_maximum_discharge_power_Read_Data_By_Identifier: required-interface=DataServices_Data_HV_battery_maximum_discharge_power_Read_Data_By_Identifier
      DataServices_Data_DiagnServi_TABROW_NeuMeasu_Read_30_1: required-interface=DataServices_Data_DiagnServi_TABROW_NeuMeasu_Read_30_1
      DataServices_Data_TABROW_StateOfBatteMIL_ReadDataByIdent: required-interface=DataServices_Data_TABROW_StateOfBatteMIL_ReadDataByIdent
      DataServices_Data_TABROW_BatteTempeMinim_ReadDataByIdent: required-interface=DataServices_Data_TABROW_BatteTempeMinim_ReadDataByIdent
      DataServices_Data_TABROW_StateOfBattePowerReduc_ReadDataByIdent: required-interface=DataServices_Data_TABROW_StateOfBattePowerReduc_ReadDataByIdent
      DataServices_Data_DiagnServi_TABROW_NeuMeasu_Read_27_3_1: required-interface=DataServices_Data_DiagnServi_TABROW_NeuMeasu_Read_27_3_1
      DataServices_Data_DiagnServi_HV_battery_modules_actual_voltage_Read: required-interface=DataServices_Data_DiagnServi_HV_battery_modules_actual_voltage_Read
      DataServices_Data_TABROW_IsolaResisSystePlus_ReadDataByIdent: required-interface=DataServices_Data_TABROW_IsolaResisSystePlus_ReadDataByIdent
      DataServices_Data_DiagnServi_TABROW_VWDataSetNumbeOrECUDataContaNumbe_Read: required-interface=DataServices_Data_DiagnServi_TABROW_VWDataSetNumbeOrECUDataContaNumbe_Read
      DataServices_Data_DiagnServi_TABROW_NeuMeasu_Read_29_1_1_1: required-interface=DataServices_Data_DiagnServi_TABROW_NeuMeasu_Read_29_1_1_1
      DataServices_Data_DiagnServi_TABROW_NeuMeasu_Read_7_1: required-interface=DataServices_Data_DiagnServi_TABROW_NeuMeasu_Read_7_1
      DataServices_Data_DiagnServi_TABROW_NeuMeasu_Read_7_2: required-interface=DataServices_Data_DiagnServi_TABROW_NeuMeasu_Read_7_2
      DataServices_Data_TABROW_BMCHVKFehleSD_Read_Data_By_Identifier: required-interface=DataServices_Data_TABROW_BMCHVKFehleSD_Read_Data_By_Identifier
      DataServices_Data_TABROW_CellVoltaMaxim_ReadDataByIdent: required-interface=DataServices_Data_TABROW_CellVoltaMaxim_ReadDataByIdent
      DataServices_Data_DiagnServi_TABROW_CalibIdent_Read: required-interface=DataServices_Data_DiagnServi_TABROW_CalibIdent_Read
      DataServices_Data_DiagnServi_TABROW_DID0xEFD_Read_1_2: required-interface=DataServices_Data_DiagnServi_TABROW_DID0xEFD_Read_1_2
      DataServices_Data_DiagnServi_TABROW_DID0xEFD_Read_1_1: required-interface=DataServices_Data_DiagnServi_TABROW_DID0xEFD_Read_1_1
      DataServices_Data_DiagnServi_TABROW_VWDataSetName_Read: required-interface=DataServices_Data_DiagnServi_TABROW_VWDataSetName_Read
      DataServices_Data_DC_charging_station_actual_voltage_Read_Data_By_Identifier: required-interface=DataServices_Data_DC_charging_station_actual_voltage_Read_Data_By_Identifier
      DataServices_Data_TABROW_CellStateOfChargMinim_ReadDataByIdent: required-interface=DataServices_Data_TABROW_CellStateOfChargMinim_ReadDataByIdent
      DataServices_Data_TABROW_TABROSyste_Read_1_1_1_1_1_1_1_1_1_1_1: required-interface=DataServices_Data_TABROW_TABROSyste_Read_1_1_1_1_1_1_1_1_1_1_1
      DataServices_Data_DiagnServi_TABROW_NeuMeasu_Read: required-interface=DataServices_Data_DiagnServi_TABROW_NeuMeasu_Read
      DataServices_Data_TABROW_TABROSyste_Read_1: required-interface=DataServices_Data_TABROW_TABROSyste_Read_1
      DataServices_Data_Maximum_Charge_Voltage_Read_Data_By_Identifier: required-interface=DataServices_Data_Maximum_Charge_Voltage_Read_Data_By_Identifier
      DataServices_Data_DiagnServi_TABROW_ECUSeriaNumbe_Read: required-interface=DataServices_Data_DiagnServi_TABROW_ECUSeriaNumbe_Read
      DataServices_Data_TABROW_SOKVerifFaileList_Read_Data_By_Identifier: required-interface=DataServices_Data_TABROW_SOKVerifFaileList_Read_Data_By_Identifier
      DataServices_Data_DiagnServi_TABROW_VWCodinValue_Read: required-interface=DataServices_Data_DiagnServi_TABROW_VWCodinValue_Read
      DataServices_Data_TABROW_TABROSyste_Read_4: required-interface=DataServices_Data_TABROW_TABROSyste_Read_4
      DataServices_Data_TABROW_TABROSyste_Read_2: required-interface=DataServices_Data_TABROW_TABROSyste_Read_2
      DataServices_Data_TABROW_TABROSyste_Read_3: required-interface=DataServices_Data_TABROW_TABROSyste_Read_3
      DataServices_Data_DiagnServi_TABROW_NeuMeasu_Read_63_1: required-interface=DataServices_Data_DiagnServi_TABROW_NeuMeasu_Read_63_1
      DataServices_Data_Charisma_requestet_driving_program_hv_battery_Read_Data_By_Identifier: required-interface=DataServices_Data_Charisma_requestet_driving_program_hv_battery_Read_Data_By_Identifier
      DataServices_Data_DiagnServi_TABROW_NeuMeasu_Read_27_1_1: required-interface=DataServices_Data_DiagnServi_TABROW_NeuMeasu_Read_27_1_1
      DataServices_Data_DiagnServi_TABROW_NeuMeasu_Read_27_1_2: required-interface=DataServices_Data_DiagnServi_TABROW_NeuMeasu_Read_27_1_2
      DataServices_Data_DiagnServi_TABROW_NeuMeasu_Read_43_1_1: required-interface=DataServices_Data_DiagnServi_TABROW_NeuMeasu_Read_43_1_1
      DataServices_Data_DiagnServi_Type_number_assembly_Read: required-interface=DataServices_Data_DiagnServi_Type_number_assembly_Read
      DataServices_Data_TABROW_OBDType_Read: required-interface=DataServices_Data_TABROW_OBDType_Read
      DataServices_Data_TABROW_SOKMissiKeyList_Read_Data_By_Identifier: required-interface=DataServices_Data_TABROW_SOKMissiKeyList_Read_Data_By_Identifier
      DataServices_Data_DiagnServi_TABROW_TABROFDSPr_Read: required-interface=DataServices_Data_DiagnServi_TABROW_TABROFDSPr_Read
      DataServices_Data_Battery_amount_of_modules_Read_Data_By_Identifier: required-interface=DataServices_Data_Battery_amount_of_modules_Read_Data_By_Identifier
      DataServices_Data_DiagnServi_TABROW_EnginRPM_Read: required-interface=DataServices_Data_DiagnServi_TABROW_EnginRPM_Read
      DataServices_Data_DiagnServi_TABROW_Produ_Read: required-interface=DataServices_Data_DiagnServi_TABROW_Produ_Read
      DataServices_Data_Battery_contactors_actual_states_Read_Data_By_Identifier: required-interface=DataServices_Data_Battery_contactors_actual_states_Read_Data_By_Identifier
      DataServices_Data_DiagnServi_TABROW_NeuMeasu_Read_27_1_1_1: required-interface=DataServices_Data_DiagnServi_TABROW_NeuMeasu_Read_27_1_1_1
      DataServices_Data_DiagnServi_TABROW_NeuMeasu_Read_27_1_1_2: required-interface=DataServices_Data_DiagnServi_TABROW_NeuMeasu_Read_27_1_1_2
      DataServices_Data_TABROW_OBDClassDescr_Read_Data_By_Identifier: required-interface=DataServices_Data_TABROW_OBDClassDescr_Read_Data_By_Identifier
      DataServices_Data_DiagnServi_TABROW_TimeSinceEnginStart_Read: required-interface=DataServices_Data_DiagnServi_TABROW_TimeSinceEnginStart_Read
      DataServices_Data_TABROW_TABROSyste_Read_1_1_1_1: required-interface=DataServices_Data_TABROW_TABROSyste_Read_1_1_1_1
      DataServices_Data_DiagnServi_TABROW_NeuMeasu_Read_32: required-interface=DataServices_Data_DiagnServi_TABROW_NeuMeasu_Read_32
      DataServices_Data_DiagnServi_TABROW_NeuMeasu_Read_31: required-interface=DataServices_Data_DiagnServi_TABROW_NeuMeasu_Read_31
      DataServices_Data_DiagnServi_TABROW_NeuMeasu_Read_30: required-interface=DataServices_Data_DiagnServi_TABROW_NeuMeasu_Read_30
      DataServices_Data_DiagnServi_TABROW_NeuMeasu_Read_28_2: required-interface=DataServices_Data_DiagnServi_TABROW_NeuMeasu_Read_28_2
      DataServices_Data_DiagnServi_TABROW_NeuMeasu_Read_28_1: required-interface=DataServices_Data_DiagnServi_TABROW_NeuMeasu_Read_28_1
      DataServices_Data_DiagnServi_TABROW_NeuMeasu_Read_28_4: required-interface=DataServices_Data_DiagnServi_TABROW_NeuMeasu_Read_28_4
      DataServices_Data_TABROW_StatuECUStandMode_Read: required-interface=DataServices_Data_TABROW_StatuECUStandMode_Read
      DataServices_Data_DiagnServi_TABROW_NeuMeasu_Read_28_3: required-interface=DataServices_Data_DiagnServi_TABROW_NeuMeasu_Read_28_3
      DataServices_Data_DiagnServi_TABROW_NeuMeasu_Read_28_6: required-interface=DataServices_Data_DiagnServi_TABROW_NeuMeasu_Read_28_6
      DataServices_Data_DiagnServi_TABROW_NeuMeasu_Read_28_5: required-interface=DataServices_Data_DiagnServi_TABROW_NeuMeasu_Read_28_5
      DataServices_Data_DiagnServi_TABROW_NeuMeasu_Read_33_1_1_1_1_1_1_1_1_1_1_1_1_1_1_1_1_1_1_1_1_1_1_1_2_1: required-interface=DataServices_Data_DiagnServi_TABROW_NeuMeasu_Read_33_1_1_1_1_1_1_1_1_1_1_1_1_1_1_1_1_1_1_1_1_1_1_1_2_1
      DataServices_Data_TABROW_TABROVWDat_Read_1: required-interface=DataServices_Data_TABROW_TABROVWDat_Read_1
      DataServices_Data_DiagnServi_TABROW_NeuMeasu_Read_36: required-interface=DataServices_Data_DiagnServi_TABROW_NeuMeasu_Read_36
      DataServices_Data_DiagnServi_TABROW_NeuMeasu_Read_35: required-interface=DataServices_Data_DiagnServi_TABROW_NeuMeasu_Read_35
      DataServices_Data_DiagnServi_TABROW_NeuMeasu_Read_34: required-interface=DataServices_Data_DiagnServi_TABROW_NeuMeasu_Read_34
      DataServices_Data_DiagnServi_TABROW_NeuMeasu_Read_33: required-interface=DataServices_Data_DiagnServi_TABROW_NeuMeasu_Read_33
      DataServices_Data_DiagnServi_TABROW_NeuMeasu_Read_39: required-interface=DataServices_Data_DiagnServi_TABROW_NeuMeasu_Read_39
      DataServices_Data_DiagnServi_TABROW_NeuMeasu_Read_38: required-interface=DataServices_Data_DiagnServi_TABROW_NeuMeasu_Read_38
      DataServices_Data_DiagnServi_TABROW_NeuMeasu_Read_37: required-interface=DataServices_Data_DiagnServi_TABROW_NeuMeasu_Read_37
      DataServices_Data_DiagnServi_TABROW_NeuMeasu_Read_46_1_1_1_1_1_1_2: required-interface=DataServices_Data_DiagnServi_TABROW_NeuMeasu_Read_46_1_1_1_1_1_1_2
      DataServices_Data_DiagnServi_TABROW_NeuMeasu_Read_46_1_1_1_1_1_1_1: required-interface=DataServices_Data_DiagnServi_TABROW_NeuMeasu_Read_46_1_1_1_1_1_1_1
      DataServices_Data_DiagnServi_TABROW_NeuMeasu_Read_43: required-interface=DataServices_Data_DiagnServi_TABROW_NeuMeasu_Read_43
      DataServices_Data_DiagnServi_TABROW_NeuMeasu_Read_42: required-interface=DataServices_Data_DiagnServi_TABROW_NeuMeasu_Read_42
      DataServices_Data_DiagnServi_TABROW_NeuMeasu_Read_41: required-interface=DataServices_Data_DiagnServi_TABROW_NeuMeasu_Read_41
      DataServices_Data_DiagnServi_TABROW_NeuMeasu_Read_40: required-interface=DataServices_Data_DiagnServi_TABROW_NeuMeasu_Read_40
      DataServices_Data_DiagnServi_Assembly_part_number_Read: required-interface=DataServices_Data_DiagnServi_Assembly_part_number_Read
      DataServices_Data_DiagnServi_TABROW_NeuMeasu_Read_47: required-interface=DataServices_Data_DiagnServi_TABROW_NeuMeasu_Read_47
      DataServices_Data_DiagnServi_TABROW_NeuMeasu_Read_46: required-interface=DataServices_Data_DiagnServi_TABROW_NeuMeasu_Read_46
      DataServices_Data_DiagnServi_TABROW_NeuMeasu_Read_45: required-interface=DataServices_Data_DiagnServi_TABROW_NeuMeasu_Read_45
      DataServices_Data_DiagnServi_TABROW_NeuMeasu_Read_49: required-interface=DataServices_Data_DiagnServi_TABROW_NeuMeasu_Read_49
      DataServices_Data_DiagnServi_TABROW_NeuMeasu_Read_48: required-interface=DataServices_Data_DiagnServi_TABROW_NeuMeasu_Read_48
      DataServices_Data_DiagnServi_TABROW_TABROECUPr_Read: required-interface=DataServices_Data_DiagnServi_TABROW_TABROECUPr_Read
      DataServices_Data_TABROW_TABROSyste_Read_1_1_1_1_1_1_1_1_1_1_1_1: required-interface=DataServices_Data_TABROW_TABROSyste_Read_1_1_1_1_1_1_1_1_1_1_1_1
      DataServices_Data_DiagnServi_TABROW_NeuMeasu_Read_10: required-interface=DataServices_Data_DiagnServi_TABROW_NeuMeasu_Read_10
      DataServices_Data_DiagnServi_TABROW_NeuMeasu_Read_43_1_1_1_1_1_1_1_1_1_1_1: required-interface=DataServices_Data_DiagnServi_TABROW_NeuMeasu_Read_43_1_1_1_1_1_1_1_1_1_1_1
      DataServices_Data_Minimum_Discharge_Voltage_Read_Data_By_Identifier: required-interface=DataServices_Data_Minimum_Discharge_Voltage_Read_Data_By_Identifier
      DataServices_Data_DiagnServi_TABROW_NeuMeasu_Read_19: required-interface=DataServices_Data_DiagnServi_TABROW_NeuMeasu_Read_19
      DataServices_Data_DiagnServi_TABROW_NeuMeasu_Read_14: required-interface=DataServices_Data_DiagnServi_TABROW_NeuMeasu_Read_14
      DataServices_Data_DiagnServi_TABROW_NeuMeasu_Read_70_1: required-interface=DataServices_Data_DiagnServi_TABROW_NeuMeasu_Read_70_1
      DataServices_Data_DiagnServi_TABROW_NeuMeasu_Read_13: required-interface=DataServices_Data_DiagnServi_TABROW_NeuMeasu_Read_13
      DataServices_Data_DiagnServi_TABROW_NeuMeasu_Read_12: required-interface=DataServices_Data_DiagnServi_TABROW_NeuMeasu_Read_12
      DataServices_Data_DiagnServi_TABROW_NeuMeasu_Read_11: required-interface=DataServices_Data_DiagnServi_TABROW_NeuMeasu_Read_11
      DataServices_Data_DiagnServi_TABROW_NeuMeasu_Read_18: required-interface=DataServices_Data_DiagnServi_TABROW_NeuMeasu_Read_18
      DataServices_Data_DiagnServi_TABROW_NeuMeasu_Read_17: required-interface=DataServices_Data_DiagnServi_TABROW_NeuMeasu_Read_17
      DataServices_Data_DiagnServi_TABROW_NeuMeasu_Read_16: required-interface=DataServices_Data_DiagnServi_TABROW_NeuMeasu_Read_16
      DataServices_Data_DiagnServi_TABROW_NeuMeasu_Read_15: required-interface=DataServices_Data_DiagnServi_TABROW_NeuMeasu_Read_15
      DataServices_Data_DiagnServi_TABROW_NeuMeasu_Read_27_2_1_1: required-interface=DataServices_Data_DiagnServi_TABROW_NeuMeasu_Read_27_2_1_1
      DataServices_Data_DiagnServi_TABROW_NeuMeasu_Read_20: required-interface=DataServices_Data_DiagnServi_TABROW_NeuMeasu_Read_20
      DataServices_Data_DiagnServi_Assembly_production_data_Read: required-interface=DataServices_Data_DiagnServi_Assembly_production_data_Read
      DataServices_Data_TABROW_VkmsTrainCount_Read_Data_By_Identifier: required-interface=DataServices_Data_TABROW_VkmsTrainCount_Read_Data_By_Identifier
      DataServices_Data_DiagnServi_Cell_part_number_Read: required-interface=DataServices_Data_DiagnServi_Cell_part_number_Read
      DataServices_Data_TABROW_CellStateOfChargMaxim_ReadDataByIdent: required-interface=DataServices_Data_TABROW_CellStateOfChargMaxim_ReadDataByIdent
      DataServices_Data_DiagnServi_TABROW_NeuMeasu_Read_25: required-interface=DataServices_Data_DiagnServi_TABROW_NeuMeasu_Read_25
      DataServices_Data_DiagnServi_TABROW_NeuMeasu_Read_24: required-interface=DataServices_Data_DiagnServi_TABROW_NeuMeasu_Read_24
      DataServices_Data_DiagnServi_TABROW_NeuMeasu_Read_23: required-interface=DataServices_Data_DiagnServi_TABROW_NeuMeasu_Read_23
      DataServices_Data_TABROW_ProgrPreco_Read: required-interface=DataServices_Data_TABROW_ProgrPreco_Read
      DataServices_Data_DiagnServi_TABROW_NeuMeasu_Read_29: required-interface=DataServices_Data_DiagnServi_TABROW_NeuMeasu_Read_29
      DataServices_Data_DiagnServi_TABROW_NeuMeasu_Read_28: required-interface=DataServices_Data_DiagnServi_TABROW_NeuMeasu_Read_28
      DataServices_Data_DiagnServi_TABROW_NeuMeasu_Read_27: required-interface=DataServices_Data_DiagnServi_TABROW_NeuMeasu_Read_27
      DataServices_Data_DiagnServi_TABROW_NeuMeasu_Read_26: required-interface=DataServices_Data_DiagnServi_TABROW_NeuMeasu_Read_26
      DataServices_Data_DiagnServi_TABROW_NeuMeasu_Read_72: required-interface=DataServices_Data_DiagnServi_TABROW_NeuMeasu_Read_72
      DataServices_Data_DiagnServi_TABROW_NeuMeasu_Read_71: required-interface=DataServices_Data_DiagnServi_TABROW_NeuMeasu_Read_71
      DataServices_Data_DiagnServi_TABROW_NeuMeasu_Read_70: required-interface=DataServices_Data_DiagnServi_TABROW_NeuMeasu_Read_70
      DataServices_Data_DiagnServi_TABROW_NeuMeasu_Read_74: required-interface=DataServices_Data_DiagnServi_TABROW_NeuMeasu_Read_74
      DataServices_Data_DiagnServi_TABROW_NeuMeasu_Read_73: required-interface=DataServices_Data_DiagnServi_TABROW_NeuMeasu_Read_73
      DataServices_Data_TABROW_VWWorksSysteName_Read: required-interface=DataServices_Data_TABROW_VWWorksSysteName_Read
      DataServices_Data_DiagnServi_TABROW_NeuMeasu_Read_83: required-interface=DataServices_Data_DiagnServi_TABROW_NeuMeasu_Read_83
      DataServices_Data_DiagnServi_TABROW_NeuMeasu_Read_9_2: required-interface=DataServices_Data_DiagnServi_TABROW_NeuMeasu_Read_9_2
      DataServices_Data_DiagnServi_TABROW_NeuMeasu_Read_82: required-interface=DataServices_Data_DiagnServi_TABROW_NeuMeasu_Read_82
      DataServices_Data_DiagnServi_TABROW_NeuMeasu_Read_29_1_1: required-interface=DataServices_Data_DiagnServi_TABROW_NeuMeasu_Read_29_1_1
      DataServices_Data_DiagnServi_TABROW_NeuMeasu_Read_29_1_2: required-interface=DataServices_Data_DiagnServi_TABROW_NeuMeasu_Read_29_1_2
      DataServices_Data_DiagnServi_TABROW_NeuMeasu_Read_84: required-interface=DataServices_Data_DiagnServi_TABROW_NeuMeasu_Read_84
      DataServices_Data_DiagnServi_TABROW_NeuMeasu_Read_9_1: required-interface=DataServices_Data_DiagnServi_TABROW_NeuMeasu_Read_9_1
      DataServices_Data_TABROW_BatteTempeMaxim_ReadDataByIdent: required-interface=DataServices_Data_TABROW_BatteTempeMaxim_ReadDataByIdent
      DataServices_Data_DiagnServi_TABROW_NeuMeasu_Read_50: required-interface=DataServices_Data_DiagnServi_TABROW_NeuMeasu_Read_50
      DataServices_Data_DiagnServi_Type_number_BCUe_Read: required-interface=DataServices_Data_DiagnServi_Type_number_BCUe_Read
      DataServices_Data_DiagnServi_TABROW_NeuMeasu_Read_53: required-interface=DataServices_Data_DiagnServi_TABROW_NeuMeasu_Read_53
      DataServices_Data_DiagnServi_TABROW_NeuMeasu_Read_52: required-interface=DataServices_Data_DiagnServi_TABROW_NeuMeasu_Read_52
      DataServices_Data_DiagnServi_TABROW_NeuMeasu_Read_51: required-interface=DataServices_Data_DiagnServi_TABROW_NeuMeasu_Read_51
      DataServices_Data_DiagnServi_TABROW_NeuMeasu_Read_56: required-interface=DataServices_Data_DiagnServi_TABROW_NeuMeasu_Read_56
      DataServices_Data_DiagnServi_TABROW_NeuMeasu_Read_55: required-interface=DataServices_Data_DiagnServi_TABROW_NeuMeasu_Read_55
      DataServices_Data_DiagnServi_TABROW_NeuMeasu_Read_61: required-interface=DataServices_Data_DiagnServi_TABROW_NeuMeasu_Read_61
      DataServices_Data_DiagnServi_TABROW_NeuMeasu_Read_60: required-interface=DataServices_Data_DiagnServi_TABROW_NeuMeasu_Read_60
      DataServices_Data_DiagnServi_TABROW_NeuMeasu_Read_63: required-interface=DataServices_Data_DiagnServi_TABROW_NeuMeasu_Read_63
      DataServices_Data_DiagnServi_BMC_clamp_30c_Read: required-interface=DataServices_Data_DiagnServi_BMC_clamp_30c_Read
      DataServices_Data_TABROW_CellVoltaSum_ReadDataByIdent: required-interface=DataServices_Data_TABROW_CellVoltaSum_ReadDataByIdent
      DataServices_Data_DiagnServi_TABROW_NeuMeasu_Read_27_3_1_1: required-interface=DataServices_Data_DiagnServi_TABROW_NeuMeasu_Read_27_3_1_1
      DataServices_Data_Battery_isolation_measurement_actual_and_requested_state_Read_Data_By_Identifier: required-interface=DataServices_Data_Battery_isolation_measurement_actual_and_requested_state_Read_Data_By_Identifier
      DataServices_Data_TABROW_ServiDiscoState_Read_Data_By_Identifier: required-interface=DataServices_Data_TABROW_ServiDiscoState_Read_Data_By_Identifier
      SecurityAccess_Unlock_L1: required-interface=SecurityAccess_Unlock_L1
      DataServices_Data_TABROW_RegulXSoftwIdentNumbe_Read: required-interface=DataServices_Data_TABROW_RegulXSoftwIdentNumbe_Read
      DataServices_Data_TABROW_ConfiHash_Read: required-interface=DataServices_Data_TABROW_ConfiHash_Read
      DataServices_Data_TABROW_VehicIdentNumbe_Read: required-interface=DataServices_Data_TABROW_VehicIdentNumbe_Read
      DataServices_Data_TABROW_ProgrHash_Read: required-interface=DataServices_Data_TABROW_ProgrHash_Read
      Dcm_Read_ExtendedSFDRole: mode-switch-receiver-com-spec=enhanced-mode-api=true, required-interface=Dcm_Read_ExtendedSFDRole
      Dcm_Read_EptiSFDRole: mode-switch-receiver-com-spec=enhanced-mode-api=true, required-interface=Dcm_Read_EptiSFDRole
      Dcm_Read_E2eSFDRole: mode-switch-receiver-com-spec=enhanced-mode-api=true, required-interface=Dcm_Read_E2eSFDRole
      Dcm_Read_OtaSFDRole: mode-switch-receiver-com-spec=enhanced-mode-api=true, required-interface=Dcm_Read_OtaSFDRole
      Dcm_Read_SuperUserSFDRole: mode-switch-receiver-com-spec=enhanced-mode-api=true, required-interface=Dcm_Read_SuperUserSFDRole
      Dcm_Read_BasicSFDRole: mode-switch-receiver-com-spec=enhanced-mode-api=true, required-interface=Dcm_Read_BasicSFDRole
      Dcm_Read_ProductionSFDRole: mode-switch-receiver-com-spec=enhanced-mode-api=true, required-interface=Dcm_Read_ProductionSFDRole
      DataServices_Data_TABROW_SFDDevelModeActiv_Read: required-interface=DataServices_Data_TABROW_SFDDevelModeActiv_Read
      DataServices_Data_TABROW_VishnDID_Read: required-interface=DataServices_Data_TABROW_VishnDID_Read
      DataServices_Data_Vishnu_DID: required-interface=DataServices_Data_Vishnu_DID
      DataServices_Data_TABROW_CanTPData_Read: required-interface=DataServices_Data_TABROW_CanTPData_Read
      DataServices_Data_TABROW_PIMDID_Read: required-interface=DataServices_Data_TABROW_PIMDID_Read
      RoutineServices_Routine_DiagnServi_TABROW_NewRoutiBasicSetti_Start_Routine: required-interface=RoutineServices_Routine_DiagnServi_TABROW_NewRoutiBasicSetti_Start_Routine
      SecurityAccess_UnLock_L2: required-interface=SecurityAccess_UnLock_L2
      DataServices_Data_TABROW_HVBatteBackFlowTempeWrite_Read: required-interface=DataServices_Data_TABROW_HVBatteBackFlowTempeWrite_Read
    behavior DcmInternalBehavior: data-type-mapping=DcmMappingSet, handle-termination-and-restart=NO-SUPPORT, included-data-type-set=data-type=[Dcm_ConfirmationStatusType, Dcm_OpStatusType, Dcm_NegativeResponseCodeType, Dcm_ProtocolType, Dcm_RequestKindType, Dcm_SecLevelType, Dcm_SesCtrlType, Dcm_ControlDtcSettingType, Dcm_EcuResetType, Dcm_DiagnosticSessionControlType, Dcm_CommunicationModeType]
      timing event Timer_Dcm_MainFunction: start-on-event=Dcm_MainFunction, period=0.01
      6 x operation invoked event:
        OpEventGetActiveProtocol_GetActiveProtocol_DCMServices: start-on-event=GetActiveProtocol, operation=DCMServices.GetActiveProtocol
        OpEventGetSesCtrlType_GetSesCtrlType_DCMServices: start-on-event=GetSesCtrlType, operation=DCMServices.GetSesCtrlType
        OpEventResetToDefaultSession_ResetToDefaultSession_DCMServices: start-on-event=ResetToDefaultSession, operation=DCMServices.ResetToDefaultSession
        OpEventSetActiveDiagnostic_SetActiveDiagnostic_DCMServices: start-on-event=SetActiveDiagnostic, operation=DCMServices.SetActiveDiagnostic
        OpEventGetRequestKind_GetRequestKind_DCMServices: start-on-event=GetRequestKind, operation=DCMServices.GetRequestKind
        OpEventGetSecurityLevel_GetSecurityLevel_DCMServices: start-on-event=GetSecurityLevel, operation=DCMServices.GetSecurityLevel
      port-api-options:
        enable-take-address=true, indirect-api=false, port=DcmControlDtcSetting
        enable-take-address=true, indirect-api=false, port=DcmEcuReset
        enable-take-address=true, indirect-api=false, port=DcmDiagnosticSessionControl
        enable-take-address=true, indirect-api=false, port=DcmCommunicationControl_ComMConf_ComMChannel_CN_BMC_CAN01_78a85e89
        enable-take-address=true, indirect-api=false, port=DcmCommunicationControl_ComMConf_ComMChannel_CN_HCP5_CANFD01_54d90215
        enable-take-address=true, indirect-api=false, port=DCMServices
        enable-take-address=true, indirect-api=false, port=SecurityAccess_Unlock_L1
        enable-take-address=true, indirect-api=false, port=RoutineServices_Routine_DiagnServi_RoutiContrCheckProgrPreco
        enable-take-address=true, indirect-api=false, port=RoutineServices_Routine_DiagnServi_TABROW_CalcuIntegValidData_Start_Routine
        enable-take-address=true, indirect-api=false, port=RoutineServices_Routine_DiagnServi_TABROW_CalcuIndivHashValue_Start_Routine
        enable-take-address=true, indirect-api=false, port=RoutineServices_Routine_DiagnServi_TABROW_CalcuModulHashValue_Start_Routine_COP
        enable-take-address=true, indirect-api=false, port=RoutineServices_Routine_DiagnServi_TABROW_IsolaMeasuDeactMode_Start_Routine
        enable-take-address=true, indirect-api=false, port=RoutineServices_Routine_DiagnServi_TABROW_ResetOfContaError_Start_Routine
        enable-take-address=true, indirect-api=false, port=RoutineServices_Routine_DiagnServi_TABROW_AdaptOfVoltaMeasuChann_Start_Routine
        enable-take-address=true, indirect-api=false, port=RoutineServices_Routine_DiagnServi_TABROW_NeuRoutiBasicSetti_Start_Routine_1
        enable-take-address=true, indirect-api=false, port=RoutineServices_Routine_DiagnServi_TABROW_NeuRoutiBasicSetti_Start_Routine_3
        enable-take-address=true, indirect-api=false, port=RoutineServices_Routine_DiagnServi_TABROW_NeuRoutiBasicSetti_Start_Routine_2
        enable-take-address=true, indirect-api=false, port=RoutineServices_Routine_DiagnServi_TABROW_ResetOfModulParam_Start_Routine
        enable-take-address=true, indirect-api=false, port=RoutineServices_Routine_DiagnServi_TABROW_NeuRoutiBasicSetti_Start_Routine
        enable-take-address=true, indirect-api=false, port=RoutineServices_Routine_DiagnServi_TABROW_NeuRoutiBasicSetti_Start_Routine_4
        enable-take-address=true, indirect-api=false, port=RoutineServices_Routine_DiagnServi_TABROW_NeuRoutiImmedResul_Start_Routine
        enable-take-address=true, indirect-api=false, port=RoutineServices_Routine_DiagnServi_TABROW_NeuRoutiBasicSetti_Start_Routine_5
        enable-take-address=true, indirect-api=false, port=RoutineServices_Routine_DiagnServi_TABROW_NeuRoutiBasicSetti_Start_Routine_4_2
        enable-take-address=true, indirect-api=false, port=RoutineServices_Routine_DiagnServi_TABROW_ResetHVBatteAfterSepar_Start_Routine
        enable-take-address=true, indirect-api=false, port=RoutineServices_Routine_DiagnServi_TABROW_IsolaMeasuDeactMode_Start_Routine_1
        enable-take-address=true, indirect-api=false, port=RoutineServices_Routine_DiagnServi_TABROW_ResetOfAllAdapt_Start_Routine_COP
        enable-take-address=true, indirect-api=false, port=RoutineServices_Routine_DiagnServi_TABROW_AdaptOfBatteBankMode_Start_Routine
        enable-take-address=true, indirect-api=false, port=RoutineServices_Routine_DiagnServi_TABROW_AdaptOfCellBalan_Start_Routine
        enable-take-address=true, indirect-api=false, port=RoutineServices_Routine_DiagnServi_TABROW_ResetToFactoSetti_Start_Routine_COP
        enable-take-address=true, indirect-api=false, port=RoutineServices_Routine_DiagnServi_TABROW_ResetHardCrashFlag_Start_Routine
        enable-take-address=true, indirect-api=false, port=RoutineServices_Routine_DiagnServi_Verify_partial_software_checksum_Start_Routine
        enable-take-address=true, indirect-api=false, port=RoutineServices_Routine_TABROW_VkmsDebug_Start_Routine
        enable-take-address=true, indirect-api=false, port=RoutineServices_Routine_DiagnServi_TABROW_ClearDowngProteData_Start_Routine_COP
        enable-take-address=true, indirect-api=false, port=RoutineServices_Routine_DiagnServi_TABROW_ResetHealiInhib_Start_Routine
        enable-take-address=true, indirect-api=false, port=RoutineServices_Routine_DiagnServi_TABROW_RequeConfiOfProteOfVehicDiagn_Start_Routine
        enable-take-address=true, indirect-api=false, port=RoutineServices_Routine_DiagnServi_TABROW_CalcuConfiStateFingeOfProteOfVehicDiagn_Start_Routine
        enable-take-address=true, indirect-api=false, port=RoutineServices_Routine_DiagnServi_TABROW_UnlocProteOfVehicDiagn_Start_Routine
        enable-take-address=true, indirect-api=false, port=RoutineServices_Routine_TABROW_LockProteOfVehicDiagn_Start_Routine
        enable-take-address=true, indirect-api=false, port=RoutineServices_Routine_DiagnServi_TABROW_ResetProteOfVehicDiagn_Start_Routine
        enable-take-address=true, indirect-api=false, port=RoutineServices_Routine_DiagnServi_TABROW_RequeDataOfProteOfVehicDiagn_Start_Routine
        enable-take-address=true, indirect-api=false, port=RoutineServices_Routine_DiagnServi_TABROW_RequeLoggiDataOfProteOfVehicDiagn_Start_Routine
        enable-take-address=true, indirect-api=false, port=RoutineServices_Routine_TABROW_VkmsHandlDownl_Start_Routine
        enable-take-address=true, indirect-api=false, port=RoutineServices_Routine_DiagnServi_TABROW_VkmsCheckVerifHash_Start_Routine
        enable-take-address=true, indirect-api=false, port=RoutineServices_Routine_DiagnServi_TABROW_VkmsGetIdentHash_Start_Routine
        enable-take-address=true, indirect-api=false, port=RoutineServices_Routine_DiagnServi_TABROW_VkmsGetPssHash_Start_Routine
        enable-take-address=true, indirect-api=false, port=RoutineServices_Routine_DiagnServi_TABROW_VkmsGetState_Start_Routine
        enable-take-address=true, indirect-api=false, port=RoutineServices_Routine_DiagnServi_TABROW_BeginOfWritiOfSecurDataOfProteOfVehicDiagn_Start_Routine
        enable-take-address=true, indirect-api=false, port=RoutineServices_Routine_TABROW_EndOfWritiSecurDataOfProteOfVehicDiagn_Start_Routine
        enable-take-address=true, indirect-api=false, port=RoutineServices_Routine_TABROW_CheckCalibPreCondi_Start_Routine
        enable-take-address=true, indirect-api=false, port=RoutineServices_Routine_TABROW_SOKFunctDeact_Start_Routine_COP
        enable-take-address=true, indirect-api=false, port=RoutineServices_Routine_Get_Energy_from_SOC_Start_Routine
        enable-take-address=true, indirect-api=false, port=RoutineServices_Routine_DiagnServi_Get_Charge_Power_Start_Routine
        enable-take-address=true, indirect-api=false, port=RoutineServices_Routine_DiagnServi_RoutiContrCheckProgrDepen
        enable-take-address=true, indirect-api=false, port=DataServices_Data_DID_StartApplication
        enable-take-address=true, indirect-api=false, port=DataServices_Data_HV_battery_continuous_charging_power_Read_Data_By_Identifier
        enable-take-address=true, indirect-api=false, port=DataServices_Data_HV_battery_performance_indicator_discharging_Read_Data_By_Identifier
        enable-take-address=true, indirect-api=false, port=DataServices_Data_BMC_Mode_Read_Data_By_Identifier
        enable-take-address=true, indirect-api=false, port=DataServices_Data_DiagnServi_TABROW_NeuMeasu_Read_59_2
        enable-take-address=true, indirect-api=false, port=DataServices_Data_TABROW_TABROSyste_Read_1_1_1_1_1_1_1
        enable-take-address=true, indirect-api=false, port=DataServices_Data_TABROW_SOKSignaFaileList_Read_Data_By_Identifier
        enable-take-address=true, indirect-api=false, port=DataServices_Data_DiagnServi_TABROW_NeuMeasu_Read_46_1_1_1_1_1
        enable-take-address=true, indirect-api=false, port=DataServices_Data_TABROW_VWECUHardwVersiNumbe_Read
        enable-take-address=true, indirect-api=false, port=DataServices_Data_DiagnServi_TABROW_NeuMeasu_Read_63_1_1_1
        enable-take-address=true, indirect-api=false, port=DataServices_Data_TABROW_TABROSyste_Read_1_1_1_1_1_1
        enable-take-address=true, indirect-api=false, port=DataServices_Data_DiagnServi_TABROW_NeuECUIdent_Read
        enable-take-address=true, indirect-api=false, port=DataServices_Data_DiagnServi_TABROW_NeuMeasu_Read_22_1
        enable-take-address=true, indirect-api=false, port=DataServices_Data_TABROW_VWLogicSoftwBlockLockValue_Read
        enable-take-address=true, indirect-api=false, port=DataServices_Data_DiagnServi_TABROW_NeuMeasu_Read_57_1
        enable-take-address=true, indirect-api=false, port=DataServices_Data_TABROW_StatePCM_ReadDataByIdent
        enable-take-address=true, indirect-api=false, port=DataServices_Data_DiagnServi_TABROW_SysteSupplIdent_Read
        enable-take-address=true, indirect-api=false, port=DataServices_Data_High_voltage_battery_total_voltage_Read_Data_By_Identifier
        enable-take-address=true, indirect-api=false, port=DataServices_Data_Battery_technical_state_of_charge_Read_Data_By_Identifier
        enable-take-address=true, indirect-api=false, port=DataServices_Data_DiagnServi_TABROW_NeuMeasu_Read_46_1
        enable-take-address=true, indirect-api=false, port=DataServices_Data_TABROW_BMCHVKFehleHVIL_Read_Data_By_Identifier
        enable-take-address=true, indirect-api=false, port=DataServices_Data_DiagnServi_TABROW_VWAppliSoftwVersiNumbe_Read
        enable-take-address=true, indirect-api=false, port=DataServices_Data_HV_Spannung_Nebenverbraucher_Read_Data_By_Identifier
        enable-take-address=true, indirect-api=false, port=DataServices_Data_TABROW_TABROSyste_Read_1_1_1_1_1_1_1_1
        enable-take-address=true, indirect-api=false, port=DataServices_Data_DiagnServi_TABROW_EnginCoolaTempe_Read
        enable-take-address=true, indirect-api=false, port=DataServices_Data_TABROW_SOKTimeInfor_Read_Data_By_Identifier
        enable-take-address=true, indirect-api=false, port=DataServices_Data_Battery_banks_allowed_modes_Read_Data_By_Identifier
        enable-take-address=true, indirect-api=false, port=DataServices_Data_Battery_flow_temperature_Read_Data_By_Identifier
        enable-take-address=true, indirect-api=false, port=DataServices_Data_DiagnServi_TABROW_NeuMeasu_Read_9_2_1_1
        enable-take-address=true, indirect-api=false, port=DataServices_Data_DiagnServi_TABROW_NeuMeasu_Read_46_1_1
        enable-take-address=true, indirect-api=false, port=DataServices_Data_DiagnServi_TABROW_NeuMeasu_Read_46_1_1_1
        enable-take-address=true, indirect-api=false, port=DataServices_Data_Strommesung_Read_Data_By_Identifier
        enable-take-address=true, indirect-api=false, port=DataServices_Data_BMC_Hybrid_Kundendienstfehler_Read_Data_By_Identifier
        enable-take-address=true, indirect-api=false, port=DataServices_Data_TABROW_IsolaResisSysteMinus_ReadDataByIdent
        enable-take-address=true, indirect-api=false, port=DataServices_Data_DiagnServi_TABROW_NeuMeasu_Read_43_1_1_1_1_1
        enable-take-address=true, indirect-api=false, port=DataServices_Data_BMC_IWU_Status_Read_Data_By_Identifier
        enable-take-address=true, indirect-api=false, port=DataServices_Data_DiagnServi_Type_number_BMCE_Read
        enable-take-address=true, indirect-api=false, port=DataServices_Data_HV_battery_continuous_discharge_power_Read_Data_By_Identifier
        enable-take-address=true, indirect-api=false, port=DataServices_Data_DiagnServi_TABROW_BootlTPBlock_Read
        enable-take-address=true, indirect-api=false, port=DataServices_Data_DiagnServi_ReadDataByIdentVWLogicBlockDowngProteVersi
        enable-take-address=true, indirect-api=false, port=DataServices_Data_DiagnServi_TABROW_NeuMeasu_Read_29_1_1_1_1
        enable-take-address=true, indirect-api=false, port=DataServices_Data_TABROW_ModeOfProteOfVehicDiagn_ReadDataByIdentifier
        enable-take-address=true, indirect-api=false, port=DataServices_Data_TABROW_TABROSyste_Read_1_1_1_1_1_1_1_1_1_1_1_1_1
        enable-take-address=true, indirect-api=false, port=DataServices_Data_Battery_energy_content_maximum_Read_Data_By_Identifier
        enable-take-address=true, indirect-api=false, port=DataServices_Data_DiagnServi_TABROW_TechnSpeciVersi_Read
        enable-take-address=true, indirect-api=false, port=DataServices_Data_BMC_Strom_Read_Data_By_Identifier
        enable-take-address=true, indirect-api=false, port=DataServices_Data_DiagnServi_TABROW_UnlocStatuOfECUOfProteOfVehicDiagn_Read
        enable-take-address=true, indirect-api=false, port=DataServices_Data_DiagnServi_TABROW_DID0x0EF_Read
        enable-take-address=true, indirect-api=false, port=DataServices_Data_DiagnServi_TABROW_ContrModulVolta_Read
        enable-take-address=true, indirect-api=false, port=DataServices_Data_TABROW_VkmsMissiKeyHisto_Read_Data_By_Identifier
        enable-take-address=true, indirect-api=false, port=DataServices_Data_DiagnServi_TABROW_AUTOSStandAppliSoftwIdent_Read
        enable-take-address=true, indirect-api=false, port=DataServices_Data_DiagnServi_TABROW_TABRORespo_Read_Data_By_Identifier
        enable-take-address=true, indirect-api=false, port=DataServices_Data_Battery_energy_content_actual_Read_Data_By_Identifier
        enable-take-address=true, indirect-api=false, port=DataServices_Data_TABROW_SOKGenerInfor_Read_Data_By_Identifier
        enable-take-address=true, indirect-api=false, port=DataServices_Data_DiagnServi_ReadDataByIdentVWLogicSoftwBlockVersi
        enable-take-address=true, indirect-api=false, port=DataServices_Data_HV_battery_maximum_charging_current_Read_Data_By_Identifier
        enable-take-address=true, indirect-api=false, port=DataServices_Data_DiagnServi_TABROW_VWFAZITIdentStrin_Read
        enable-take-address=true, indirect-api=false, port=DataServices_Data_DiagnServi_TABROW_NeuMeasu_Read_27_2_1
        enable-take-address=true, indirect-api=false, port=DataServices_Data_TABROW_StateOfBatteShutoCrash_ReadDataByIdent
        enable-take-address=true, indirect-api=false, port=DataServices_Data_BMC_Vorlade_Zielspannung_Read_Data_By_Identifier
        enable-take-address=true, indirect-api=false, port=DataServices_Data_TABROW_TABROSyste_Read_1_1_1_1_1_1_1_1_1_1
        enable-take-address=true, indirect-api=false, port=DataServices_Data_DiagnServi_TABROW_NeuMeasu_Read_43_1_1_1_1_1_1_1
        enable-take-address=true, indirect-api=false, port=DataServices_Data_HV_Battery_thermal_load_Read_Data_By_Identifier
        enable-take-address=true, indirect-api=false, port=DataServices_Data_DiagnServi_TABROW_NeuMeasu_Read_29_1_1_1_1_1
        enable-take-address=true, indirect-api=false, port=DataServices_Data_Prozessorauslastung_Read_Data_By_Identifier
        enable-take-address=true, indirect-api=false, port=DataServices_Data_State_Of_Charge_Battery_customer_Read_Data_By_Identifier
        enable-take-address=true, indirect-api=false, port=DataServices_Data_DiagnServi_TABROW_ActivOfDevelMessa_Read
        enable-take-address=true, indirect-api=false, port=DataServices_Data_DiagnServi_TABROW_NeuMeasu_Read_60_3
        enable-take-address=true, indirect-api=false, port=DataServices_Data_DiagnServi_TABROW_NeuMeasu_Read_60_1
        enable-take-address=true, indirect-api=false, port=DataServices_Data_DiagnServi_TABROW_CalcuLOADValue_Read
        enable-take-address=true, indirect-api=false, port=DataServices_Data_HV_battery_performance_indicator_charging_Read_Data_By_Identifier
        enable-take-address=true, indirect-api=false, port=DataServices_Data_Zero_Potential_Status_Read_Data_By_Identifier
        enable-take-address=true, indirect-api=false, port=DataServices_Data_DiagnServi_TABROW_NeuMeasu_Read_57_2_1
        enable-take-address=true, indirect-api=false, port=DataServices_Data_DiagnServi_BMC_serial_number_Read
        enable-take-address=true, indirect-api=false, port=DataServices_Data_HV_coordinator_requestet_voltage_hv_battery_Read_Data_By_Identifier
        enable-take-address=true, indirect-api=false, port=DataServices_Data_DiagnServi_TABROW_DID0xEFD_Read_{1..3}
        enable-take-address=true, indirect-api=false, port=DataServices_Data_DiagnServi_TABROW_NeuMeasu_Read_46_1_1_1_1
        enable-take-address=true, indirect-api=false, port=DataServices_Data_TABROW_ECUStandMode1_Read
        enable-take-address=true, indirect-api=false, port=DataServices_Data_TABROW_TABROSyste_Read_1_1_1_1_1
        enable-take-address=true, indirect-api=false, port=DataServices_Data_DiagnServi_TABROW_NeuMeasu_Read_29_1
        enable-take-address=true, indirect-api=false, port=DataServices_Data_DiagnServi_TABROW_NeuMeasu_Read_29_3
        enable-take-address=true, indirect-api=false, port=DataServices_Data_DiagnServi_TABROW_NeuMeasu_Read_46_1_1_1_1_1_1_2_1
        enable-take-address=true, indirect-api=false, port=DataServices_Data_DiagnServi_TABROW_NeuMeasu_Read_29_2
        enable-take-address=true, indirect-api=false, port=DataServices_Data_DiagnServi_TABROW_NeuMeasu_Read_29_5
        enable-take-address=true, indirect-api=false, port=DataServices_Data_DiagnServi_TABROW_NeuMeasu_Read_46_1_1_1_1_1_1_2_3
        enable-take-address=true, indirect-api=false, port=DataServices_Data_DiagnServi_TABROW_NeuMeasu_Read_29_4
        enable-take-address=true, indirect-api=false, port=DataServices_Data_DiagnServi_TABROW_NeuMeasu_Read_46_1_1_1_1_1_1_2_2
        enable-take-address=true, indirect-api=false, port=DataServices_Data_DiagnServi_TABROW_MonitStatuThisDriviCycle_Read
        enable-take-address=true, indirect-api=false, port=DataServices_Data_TABROW_TABROSyste_Read_1_1_1_1_1_1_1_1_1
        enable-take-address=true, indirect-api=false, port=DataServices_Data_TABROW_TABROSyste_Read_1_1_1
        enable-take-address=true, indirect-api=false, port=DataServices_Data_DiagnServi_TABROW_VWAppliDataSetIdent_Read
        enable-take-address=true, indirect-api=false, port=DataServices_Data_DiagnServi_TABROW_NeuMeasu_Read_43_1_1_1_1_1_1_1_1
        enable-take-address=true, indirect-api=false, port=DataServices_Data_TABROW_BatteTempeAvera_ReadDataByIdent
        enable-take-address=true, indirect-api=false, port=DataServices_Data_HV_battery_maximum_discharge_current_Read_Data_By_Identifier
        enable-take-address=true, indirect-api=false, port=DataServices_Data_DiagnServi_TABROW_NeuMeasu_Read_49_1
        enable-take-address=true, indirect-api=false, port=DataServices_Data_TABROW_VWLogicSoftwBlockCountOfProgrAttem_Read
        enable-take-address=true, indirect-api=false, port=DataServices_Data_DiagnServi_TABROW_VWSparePartNumbe_Read
        enable-take-address=true, indirect-api=false, port=DataServices_Data_Battery_banks_actual_voltage_Read_Data_By_Identifier
        enable-take-address=true, indirect-api=false, port=DataServices_Data_DiagnServi_TABROW_ECUNA_Read
        enable-take-address=true, indirect-api=false, port=DataServices_Data_HV_battery_maximum_charging_power_Read_Data_By_Identifier
        enable-take-address=true, indirect-api=false, port=DataServices_Data_DiagnServi_TABROW_NeuMeasu_Read_9_2_1_1_2
        enable-take-address=true, indirect-api=false, port=DataServices_Data_DiagnServi_TABROW_NeuMeasu_Read_9_2_1_1_1
        enable-take-address=true, indirect-api=false, port=DataServices_Data_DiagnServi_TABROW_NeuMeasu_Read_63_1_1
        enable-take-address=true, indirect-api=false, port=DataServices_Data_DiagnServi_Module_part_number_Read
        enable-take-address=true, indirect-api=false, port=DataServices_Data_Battery_displayed_state_of_charge_Read_Data_By_Identifier
        enable-take-address=true, indirect-api=false, port=DataServices_Data_DiagnServi_TABROW_NeuMeasu_Read_27_4_1
        enable-take-address=true, indirect-api=false, port=DataServices_Data_DiagnServi_TABROW_NeuMeasu_Read_27_1
        enable-take-address=true, indirect-api=false, port=DataServices_Data_DiagnServi_TABROW_NeuMeasu_Read_27_3
        enable-take-address=true, indirect-api=false, port=DataServices_Data_DiagnServi_TABROW_NeuMeasu_Read_27_2
        enable-take-address=true, indirect-api=false, port=DataServices_Data_DiagnServi_TABROW_NeuMeasu_Read_27_5
        enable-take-address=true, indirect-api=false, port=DataServices_Data_DiagnServi_TABROW_NeuMeasu_Read_27_4
        enable-take-address=true, indirect-api=false, port=DataServices_Data_DiagnServi_TABROW_NeuMeasu_Read_27_7
        enable-take-address=true, indirect-api=false, port=DataServices_Data_DiagnServi_TABROW_NeuMeasu_Read_27_6
        enable-take-address=true, indirect-api=false, port=DataServices_Data_DiagnServi_TABROW_NeuMeasu_Read_27_8
        enable-take-address=true, indirect-api=false, port=DataServices_Data_TABROW_StandAmbieCondi_ReadDataByIdent
        enable-take-address=true, indirect-api=false, port=DataServices_Data_DiagnServi_SOH_Read
        enable-take-address=true, indirect-api=false, port=DataServices_Data_DiagnServi_TABROW_DID0xEFD_Read_1_1_1
        enable-take-address=true, indirect-api=false, port=DataServices_Data_DiagnServi_TABROW_NeuMeasu_Read_8_1
        enable-take-address=true, indirect-api=false, port=DataServices_Data_DiagnServi_TABROW_NeuMeasu_Read_8_2
        enable-take-address=true, indirect-api=false, port=DataServices_Data_DiagnServi_TABROW_ProduDeact_Read
        enable-take-address=true, indirect-api=false, port=DataServices_Data_DiagnServi_TABROW_NeuMeasu_Read_57_11
        enable-take-address=true, indirect-api=false, port=DataServices_Data_DiagnServi_TABROW_NeuMeasu_Read_57_13
        enable-take-address=true, indirect-api=false, port=DataServices_Data_DiagnServi_TABROW_NeuMeasu_Read_57_14
        enable-take-address=true, indirect-api=false, port=DataServices_Data_DiagnServi_TABROW_AccelPedalPositD_Read
        enable-take-address=true, indirect-api=false, port=DataServices_Data_DiagnServi_TABROW_Finge_Read
        enable-take-address=true, indirect-api=false, port=DataServices_Data_TABROW_TABROSyste_Read_1_1
        enable-take-address=true, indirect-api=false, port=DataServices_Data_TABROW_ECUStandMode2_Read
        enable-take-address=true, indirect-api=false, port=DataServices_Data_DiagnServi_TABROW_NeuMeasu2_Read
        enable-take-address=true, indirect-api=false, port=DataServices_Data_DiagnServi_TABROW_NeuCalibData_Read
        enable-take-address=true, indirect-api=false, port=DataServices_Data_DiagnServi_TABROW_NeuMeasu_Read_46_1_1_1_1_1_1
        enable-take-address=true, indirect-api=false, port=DataServices_Data_DiagnServi_TABROW_TABROOBDDr_Read_Data_By_Identifier
        enable-take-address=true, indirect-api=false, port=DataServices_Data_DiagnServi_TABROW_NeuMeasu_Read_36_3
        enable-take-address=true, indirect-api=false, port=DataServices_Data_DiagnServi_TABROW_NeuMeasu_Read_36_1
        enable-take-address=true, indirect-api=false, port=DataServices_Data_DiagnServi_TABROW_NeuMeasu_Read_43_1_1_1_1_1_1_1_1_1_1
        enable-take-address=true, indirect-api=false, port=DataServices_Data_DiagnServi_TABROW_NeuMeasu_Read_43_1_1_1_1_1_1
        enable-take-address=true, indirect-api=false, port=DataServices_Data_TABROW_InUseMonitPerfoRatio_Read_Data_By_Identifier
        enable-take-address=true, indirect-api=false, port=DataServices_Data_DiagnServi_TABROW_NeuMeasu_Read_27_1_1_1_1
        enable-take-address=true, indirect-api=false, port=DataServices_Data_TABROW_BMCHVKEoHVLState_Read_Data_By_Identifier
        enable-take-address=true, indirect-api=false, port=DataServices_Data_DiagnServi_TABROW_NeuMeasu_Read_27_1_1_1_2
        enable-take-address=true, indirect-api=false, port=DataServices_Data_DiagnServi_BMCE_part_number_Read
        enable-take-address=true, indirect-api=false, port=DataServices_Data_DiagnServi_TABROW_NeuMeasu_Read_8
        enable-take-address=true, indirect-api=false, port=DataServices_Data_DiagnServi_TABROW_NeuMeasu_Read_9
        enable-take-address=true, indirect-api=false, port=DataServices_Data_TABROW_BMCHVKFehleInter_Read_Data_By_Identifier
        enable-take-address=true, indirect-api=false, port=DataServices_Data_DiagnServi_TABROW_NeuMeasu_Read_2
        enable-take-address=true, indirect-api=false, port=DataServices_Data_DiagnServi_TABROW_NeuMeasu_Read_3
        enable-take-address=true, indirect-api=false, port=DataServices_Data_TABROW_VkmsVkmsv_Read_Data_By_Identifier
        enable-take-address=true, indirect-api=false, port=DataServices_Data_DiagnServi_TABROW_NeuMeasu_Read_1
        enable-take-address=true, indirect-api=false, port=DataServices_Data_DiagnServi_TABROW_NeuMeasu_Read_6
        enable-take-address=true, indirect-api=false, port=DataServices_Data_TABROW_StatuProdu_Read_Data_By_Identifier
        enable-take-address=true, indirect-api=false, port=DataServices_Data_DiagnServi_TABROW_NeuMeasu_Read_7
        enable-take-address=true, indirect-api=false, port=DataServices_Data_DiagnServi_TABROW_NeuMeasu_Read_4
        enable-take-address=true, indirect-api=false, port=DataServices_Data_DiagnServi_TABROW_NeuMeasu_Read_5
        enable-take-address=true, indirect-api=false, port=DataServices_Data_TABROW_SysteIdent_Read
        enable-take-address=true, indirect-api=false, port=DataServices_Data_DiagnServi_TABROW_MonitStatuSinceDTCsClear_Read
        enable-take-address=true, indirect-api=false, port=DataServices_Data_TABROW_TABROSyste_Read_1_1_1_1_1_1_1_1_1_1_1_1_1_1_1
        enable-take-address=true, indirect-api=false, port=DataServices_Data_DiagnServi_TABROW_NeuMeasu_Read_29_1_1_1_1_1_1
        enable-take-address=true, indirect-api=false, port=DataServices_Data_DiagnServi_TABROW_DID0xEFD_Read
        enable-take-address=true, indirect-api=false, port=DataServices_Data_DiagnServi_ReadDataByIdentASAMODXFileVersi
        enable-take-address=true, indirect-api=false, port=DataServices_Data_DiagnServi_TABROW_AdaptOfChineSeriaNumbe_Read
        enable-take-address=true, indirect-api=false, port=DataServices_Data_BMC_Status_DCLS_Read_Data_By_Identifier
        enable-take-address=true, indirect-api=false, port=DataServices_Data_TABROW_VkmsKeyList_Read_Data_By_Identifier
        enable-take-address=true, indirect-api=false, port=DataServices_Data_DiagnServi_TABROW_Milea_Read
        enable-take-address=true, indirect-api=false, port=DataServices_Data_DiagnServi_TABROW_VehicSpeedSenso_Read
        enable-take-address=true, indirect-api=false, port=DataServices_Data_DiagnServi_TABROW_NeuMeasu_Read_29_1_1_1_1_1_1_1
        enable-take-address=true, indirect-api=false, port=DataServices_Data_DiagnServi_BCUe_part_number_Read
        enable-take-address=true, indirect-api=false, port=DataServices_Data_DiagnServi_TABROW_IntegValidDataConfiList_Read
        enable-take-address=true, indirect-api=false, port=DataServices_Data_TABROW_SOKFreshInfor_Read_Data_By_Identifier
        enable-take-address=true, indirect-api=false, port=DataServices_Data_DiagnServi_TABROW_NeuMeasu_Read_58_1
        enable-take-address=true, indirect-api=false, port=DataServices_Data_DiagnServi_TABROW_NeuMeasu_Read_43_1_1_1_1_1_1_1_1_1
        enable-take-address=true, indirect-api=false, port=DataServices_Data_Battery_return_flow_temperature_Read_Data_By_Identifier
        enable-take-address=true, indirect-api=false, port=DataServices_Data_DiagnServi_TABROW_NeuMeasu1_Read
        enable-take-address=true, indirect-api=false, port=DataServices_Data_DiagnServi_TABROW_NeuMeasu_Read_43_1
        enable-take-address=true, indirect-api=false, port=DataServices_Data_TABROW_VWECUHardwNumbe_Read
        enable-take-address=true, indirect-api=false, port=DataServices_Data_DiagnServi_TABROW_NeuMeasu_Read_9_2_1
        enable-take-address=true, indirect-api=false, port=DataServices_Data_Battery_banks_actual_mode_Read_Data_By_Identifier
        enable-take-address=true, indirect-api=false, port=DataServices_Data_DiagnServi_ReadDataByIdentASAMODXFileIdent
        enable-take-address=true, indirect-api=false, port=DataServices_Data_DiagnServi_TABROW_NeuMeasu_Read_21_1
        enable-take-address=true, indirect-api=false, port=DataServices_Data_DiagnServi_TABROW_NeuMeasu_Read_21_2
        enable-take-address=true, indirect-api=false, port=DataServices_Data_DiagnServi_TABROW_NeuMeasu_Read_33_1_1_1_1_1_1_1_1_1_1_1_1_1_1_1_1_1_1_1_1_1_1_1_2_1_1_1
        enable-take-address=true, indirect-api=false, port=DataServices_Data_TABROW_CellVoltaMinim_ReadDataByIdent
        enable-take-address=true, indirect-api=false, port=DataServices_Data_DiagnServi_ReadDataByIdentBasicSettiStatu
        enable-take-address=true, indirect-api=false, port=DataServices_Data_DiagnServi_TABROW_NeuMeasu_Read_43_1_1_1_1
        enable-take-address=true, indirect-api=false, port=DataServices_Data_TABROW_FingeAndProgrDateOfLogicSoftwBlock_Read
        enable-take-address=true, indirect-api=false, port=DataServices_Data_DiagnServi_TABROW_NeuMeasu_Read_30_2
        enable-take-address=true, indirect-api=false, port=DataServices_Data_DiagnServi_TABROW_NeuMeasu_Read_30_3
        enable-take-address=true, indirect-api=false, port=DataServices_Data_DiagnServi_TABROW_ActivDiagnSessi_Read
        enable-take-address=true, indirect-api=false, port=DataServices_Data_TABROW_VWSysteNameOrEnginType_Read
        enable-take-address=true, indirect-api=false, port=DataServices_Data_DiagnServi_TABROW_NeuMeasu_Read_27_1_1_1_1_1
        enable-take-address=true, indirect-api=false, port=DataServices_Data_DiagnServi_TABROW_NeuMeasu_Read_43_1_1_1
        enable-take-address=true, indirect-api=false, port=DataServices_Data_HV_battery_maximum_discharge_power_Read_Data_By_Identifier
        enable-take-address=true, indirect-api=false, port=DataServices_Data_DiagnServi_TABROW_NeuMeasu_Read_30_1
        enable-take-address=true, indirect-api=false, port=DataServices_Data_TABROW_StateOfBatteMIL_ReadDataByIdent
        enable-take-address=true, indirect-api=false, port=DataServices_Data_TABROW_BatteTempeMinim_ReadDataByIdent
        enable-take-address=true, indirect-api=false, port=DataServices_Data_TABROW_StateOfBattePowerReduc_ReadDataByIdent
        enable-take-address=true, indirect-api=false, port=DataServices_Data_DiagnServi_TABROW_NeuMeasu_Read_27_3_1
        enable-take-address=true, indirect-api=false, port=DataServices_Data_DiagnServi_HV_battery_modules_actual_voltage_Read
        enable-take-address=true, indirect-api=false, port=DataServices_Data_TABROW_IsolaResisSystePlus_ReadDataByIdent
        enable-take-address=true, indirect-api=false, port=DataServices_Data_DiagnServi_TABROW_VWDataSetNumbeOrECUDataContaNumbe_Read
        enable-take-address=true, indirect-api=false, port=DataServices_Data_DiagnServi_TABROW_NeuMeasu_Read_29_1_1_1
        enable-take-address=true, indirect-api=false, port=DataServices_Data_DiagnServi_TABROW_NeuMeasu_Read_7_1
        enable-take-address=true, indirect-api=false, port=DataServices_Data_DiagnServi_TABROW_NeuMeasu_Read_7_2
        enable-take-address=true, indirect-api=false, port=DataServices_Data_TABROW_BMCHVKFehleSD_Read_Data_By_Identifier
        enable-take-address=true, indirect-api=false, port=DataServices_Data_TABROW_CellVoltaMaxim_ReadDataByIdent
        enable-take-address=true, indirect-api=false, port=DataServices_Data_DiagnServi_TABROW_CalibIdent_Read
        enable-take-address=true, indirect-api=false, port=DataServices_Data_DiagnServi_TABROW_DID0xEFD_Read_1_2
        enable-take-address=true, indirect-api=false, port=DataServices_Data_DiagnServi_TABROW_DID0xEFD_Read_1_1
        enable-take-address=true, indirect-api=false, port=DataServices_Data_DiagnServi_TABROW_VWDataSetName_Read
        enable-take-address=true, indirect-api=false, port=DataServices_Data_DC_charging_station_actual_voltage_Read_Data_By_Identifier
        enable-take-address=true, indirect-api=false, port=DataServices_Data_TABROW_CellStateOfChargMinim_ReadDataByIdent
        enable-take-address=true, indirect-api=false, port=DataServices_Data_TABROW_TABROSyste_Read_1_1_1_1_1_1_1_1_1_1_1
        enable-take-address=true, indirect-api=false, port=DataServices_Data_DiagnServi_TABROW_NeuMeasu_Read
        enable-take-address=true, indirect-api=false, port=DataServices_Data_TABROW_TABROSyste_Read_1
        enable-take-address=true, indirect-api=false, port=DataServices_Data_Maximum_Charge_Voltage_Read_Data_By_Identifier
        enable-take-address=true, indirect-api=false, port=DataServices_Data_DiagnServi_TABROW_ECUSeriaNumbe_Read
        enable-take-address=true, indirect-api=false, port=DataServices_Data_TABROW_SOKVerifFaileList_Read_Data_By_Identifier
        enable-take-address=true, indirect-api=false, port=DataServices_Data_DiagnServi_TABROW_VWCodinValue_Read
        enable-take-address=true, indirect-api=false, port=DataServices_Data_TABROW_TABROSyste_Read_4
        enable-take-address=true, indirect-api=false, port=DataServices_Data_TABROW_TABROSyste_Read_2
        enable-take-address=true, indirect-api=false, port=DataServices_Data_TABROW_TABROSyste_Read_3
        enable-take-address=true, indirect-api=false, port=DataServices_Data_DiagnServi_TABROW_NeuMeasu_Read_63_1
        enable-take-address=true, indirect-api=false, port=DataServices_Data_Charisma_requestet_driving_program_hv_battery_Read_Data_By_Identifier
        enable-take-address=true, indirect-api=false, port=DataServices_Data_DiagnServi_TABROW_NeuMeasu_Read_27_1_1
        enable-take-address=true, indirect-api=false, port=DataServices_Data_DiagnServi_TABROW_NeuMeasu_Read_27_1_2
        enable-take-address=true, indirect-api=false, port=DataServices_Data_DiagnServi_TABROW_NeuMeasu_Read_43_1_1
        enable-take-address=true, indirect-api=false, port=DataServices_Data_DiagnServi_Type_number_assembly_Read
        enable-take-address=true, indirect-api=false, port=DataServices_Data_TABROW_OBDType_Read
        enable-take-address=true, indirect-api=false, port=DataServices_Data_TABROW_SOKMissiKeyList_Read_Data_By_Identifier
        enable-take-address=true, indirect-api=false, port=DataServices_Data_DiagnServi_TABROW_TABROFDSPr_Read
        enable-take-address=true, indirect-api=false, port=DataServices_Data_Battery_amount_of_modules_Read_Data_By_Identifier
        enable-take-address=true, indirect-api=false, port=DataServices_Data_DiagnServi_TABROW_EnginRPM_Read
        enable-take-address=true, indirect-api=false, port=DataServices_Data_DiagnServi_TABROW_Produ_Read
        enable-take-address=true, indirect-api=false, port=DataServices_Data_Battery_contactors_actual_states_Read_Data_By_Identifier
        enable-take-address=true, indirect-api=false, port=DataServices_Data_DiagnServi_TABROW_NeuMeasu_Read_27_1_1_1
        enable-take-address=true, indirect-api=false, port=DataServices_Data_DiagnServi_TABROW_NeuMeasu_Read_27_1_1_2
        enable-take-address=true, indirect-api=false, port=DataServices_Data_TABROW_OBDClassDescr_Read_Data_By_Identifier
        enable-take-address=true, indirect-api=false, port=DataServices_Data_DiagnServi_TABROW_TimeSinceEnginStart_Read
        enable-take-address=true, indirect-api=false, port=DataServices_Data_TABROW_TABROSyste_Read_1_1_1_1
        enable-take-address=true, indirect-api=false, port=DataServices_Data_DiagnServi_TABROW_NeuMeasu_Read_32
        enable-take-address=true, indirect-api=false, port=DataServices_Data_DiagnServi_TABROW_NeuMeasu_Read_31
        enable-take-address=true, indirect-api=false, port=DataServices_Data_DiagnServi_TABROW_NeuMeasu_Read_30
        enable-take-address=true, indirect-api=false, port=DataServices_Data_DiagnServi_TABROW_NeuMeasu_Read_28_2
        enable-take-address=true, indirect-api=false, port=DataServices_Data_DiagnServi_TABROW_NeuMeasu_Read_28_1
        enable-take-address=true, indirect-api=false, port=DataServices_Data_DiagnServi_TABROW_NeuMeasu_Read_28_4
        enable-take-address=true, indirect-api=false, port=DataServices_Data_TABROW_StatuECUStandMode_Read
        enable-take-address=true, indirect-api=false, port=DataServices_Data_DiagnServi_TABROW_NeuMeasu_Read_28_3
        enable-take-address=true, indirect-api=false, port=DataServices_Data_DiagnServi_TABROW_NeuMeasu_Read_28_6
        enable-take-address=true, indirect-api=false, port=DataServices_Data_DiagnServi_TABROW_NeuMeasu_Read_28_5
        enable-take-address=true, indirect-api=false, port=DataServices_Data_DiagnServi_TABROW_NeuMeasu_Read_33_1_1_1_1_1_1_1_1_1_1_1_1_1_1_1_1_1_1_1_1_1_1_1_2_1
        enable-take-address=true, indirect-api=false, port=DataServices_Data_TABROW_TABROVWDat_Read_1
        enable-take-address=true, indirect-api=false, port=DataServices_Data_DiagnServi_TABROW_NeuMeasu_Read_36
        enable-take-address=true, indirect-api=false, port=DataServices_Data_DiagnServi_TABROW_NeuMeasu_Read_35
        enable-take-address=true, indirect-api=false, port=DataServices_Data_DiagnServi_TABROW_NeuMeasu_Read_34
        enable-take-address=true, indirect-api=false, port=DataServices_Data_DiagnServi_TABROW_NeuMeasu_Read_33
        enable-take-address=true, indirect-api=false, port=DataServices_Data_DiagnServi_TABROW_NeuMeasu_Read_39
        enable-take-address=true, indirect-api=false, port=DataServices_Data_DiagnServi_TABROW_NeuMeasu_Read_38
        enable-take-address=true, indirect-api=false, port=DataServices_Data_DiagnServi_TABROW_NeuMeasu_Read_37
        enable-take-address=true, indirect-api=false, port=DataServices_Data_DiagnServi_TABROW_NeuMeasu_Read_46_1_1_1_1_1_1_2
        enable-take-address=true, indirect-api=false, port=DataServices_Data_DiagnServi_TABROW_NeuMeasu_Read_46_1_1_1_1_1_1_1
        enable-take-address=true, indirect-api=false, port=DataServices_Data_DiagnServi_TABROW_NeuMeasu_Read_43
        enable-take-address=true, indirect-api=false, port=DataServices_Data_DiagnServi_TABROW_NeuMeasu_Read_42
        enable-take-address=true, indirect-api=false, port=DataServices_Data_DiagnServi_TABROW_NeuMeasu_Read_41
        enable-take-address=true, indirect-api=false, port=DataServices_Data_DiagnServi_TABROW_NeuMeasu_Read_40
        enable-take-address=true, indirect-api=false, port=DataServices_Data_DiagnServi_Assembly_part_number_Read
        enable-take-address=true, indirect-api=false, port=DataServices_Data_DiagnServi_TABROW_NeuMeasu_Read_47
        enable-take-address=true, indirect-api=false, port=DataServices_Data_DiagnServi_TABROW_NeuMeasu_Read_46
        enable-take-address=true, indirect-api=false, port=DataServices_Data_DiagnServi_TABROW_NeuMeasu_Read_45
        enable-take-address=true, indirect-api=false, port=DataServices_Data_DiagnServi_TABROW_NeuMeasu_Read_49
        enable-take-address=true, indirect-api=false, port=DataServices_Data_DiagnServi_TABROW_NeuMeasu_Read_48
        enable-take-address=true, indirect-api=false, port=DataServices_Data_DiagnServi_TABROW_TABROECUPr_Read
        enable-take-address=true, indirect-api=false, port=DataServices_Data_TABROW_TABROSyste_Read_1_1_1_1_1_1_1_1_1_1_1_1
        enable-take-address=true, indirect-api=false, port=DataServices_Data_DiagnServi_TABROW_NeuMeasu_Read_10
        enable-take-address=true, indirect-api=false, port=DataServices_Data_DiagnServi_TABROW_NeuMeasu_Read_43_1_1_1_1_1_1_1_1_1_1_1
        enable-take-address=true, indirect-api=false, port=DataServices_Data_Minimum_Discharge_Voltage_Read_Data_By_Identifier
        enable-take-address=true, indirect-api=false, port=DataServices_Data_DiagnServi_TABROW_NeuMeasu_Read_19
        enable-take-address=true, indirect-api=false, port=DataServices_Data_DiagnServi_TABROW_NeuMeasu_Read_14
        enable-take-address=true, indirect-api=false, port=DataServices_Data_DiagnServi_TABROW_NeuMeasu_Read_70_1
        enable-take-address=true, indirect-api=false, port=DataServices_Data_DiagnServi_TABROW_NeuMeasu_Read_13
        enable-take-address=true, indirect-api=false, port=DataServices_Data_DiagnServi_TABROW_NeuMeasu_Read_12
        enable-take-address=true, indirect-api=false, port=DataServices_Data_DiagnServi_TABROW_NeuMeasu_Read_11
        enable-take-address=true, indirect-api=false, port=DataServices_Data_DiagnServi_TABROW_NeuMeasu_Read_18
        enable-take-address=true, indirect-api=false, port=DataServices_Data_DiagnServi_TABROW_NeuMeasu_Read_17
        enable-take-address=true, indirect-api=false, port=DataServices_Data_DiagnServi_TABROW_NeuMeasu_Read_16
        enable-take-address=true, indirect-api=false, port=DataServices_Data_DiagnServi_TABROW_NeuMeasu_Read_15
        enable-take-address=true, indirect-api=false, port=DataServices_Data_DiagnServi_TABROW_NeuMeasu_Read_27_2_1_1
        enable-take-address=true, indirect-api=false, port=DataServices_Data_DiagnServi_TABROW_NeuMeasu_Read_20
        enable-take-address=true, indirect-api=false, port=DataServices_Data_DiagnServi_Assembly_production_data_Read
        enable-take-address=true, indirect-api=false, port=DataServices_Data_TABROW_VkmsTrainCount_Read_Data_By_Identifier
        enable-take-address=true, indirect-api=false, port=DataServices_Data_DiagnServi_Cell_part_number_Read
        enable-take-address=true, indirect-api=false, port=DataServices_Data_TABROW_CellStateOfChargMaxim_ReadDataByIdent
        enable-take-address=true, indirect-api=false, port=DataServices_Data_DiagnServi_TABROW_NeuMeasu_Read_25
        enable-take-address=true, indirect-api=false, port=DataServices_Data_DiagnServi_TABROW_NeuMeasu_Read_24
        enable-take-address=true, indirect-api=false, port=DataServices_Data_DiagnServi_TABROW_NeuMeasu_Read_23
        enable-take-address=true, indirect-api=false, port=DataServices_Data_TABROW_ProgrPreco_Read
        enable-take-address=true, indirect-api=false, port=DataServices_Data_DiagnServi_TABROW_NeuMeasu_Read_29
        enable-take-address=true, indirect-api=false, port=DataServices_Data_DiagnServi_TABROW_NeuMeasu_Read_28
        enable-take-address=true, indirect-api=false, port=DataServices_Data_DiagnServi_TABROW_NeuMeasu_Read_27
        enable-take-address=true, indirect-api=false, port=DataServices_Data_DiagnServi_TABROW_NeuMeasu_Read_26
        enable-take-address=true, indirect-api=false, port=DataServices_Data_DiagnServi_TABROW_NeuMeasu_Read_72
        enable-take-address=true, indirect-api=false, port=DataServices_Data_DiagnServi_TABROW_NeuMeasu_Read_71
        enable-take-address=true, indirect-api=false, port=DataServices_Data_DiagnServi_TABROW_NeuMeasu_Read_70
        enable-take-address=true, indirect-api=false, port=DataServices_Data_DiagnServi_TABROW_NeuMeasu_Read_74
        enable-take-address=true, indirect-api=false, port=DataServices_Data_DiagnServi_TABROW_NeuMeasu_Read_73
        enable-take-address=true, indirect-api=false, port=DataServices_Data_TABROW_VWWorksSysteName_Read
        enable-take-address=true, indirect-api=false, port=DataServices_Data_DiagnServi_TABROW_NeuMeasu_Read_83
        enable-take-address=true, indirect-api=false, port=DataServices_Data_DiagnServi_TABROW_NeuMeasu_Read_9_2
        enable-take-address=true, indirect-api=false, port=DataServices_Data_DiagnServi_TABROW_NeuMeasu_Read_82
        enable-take-address=true, indirect-api=false, port=DataServices_Data_DiagnServi_TABROW_NeuMeasu_Read_29_1_1
        enable-take-address=true, indirect-api=false, port=DataServices_Data_DiagnServi_TABROW_NeuMeasu_Read_29_1_2
        enable-take-address=true, indirect-api=false, port=DataServices_Data_DiagnServi_TABROW_NeuMeasu_Read_84
        enable-take-address=true, indirect-api=false, port=DataServices_Data_DiagnServi_TABROW_NeuMeasu_Read_9_1
        enable-take-address=true, indirect-api=false, port=DataServices_Data_TABROW_BatteTempeMaxim_ReadDataByIdent
        enable-take-address=true, indirect-api=false, port=DataServices_Data_DiagnServi_TABROW_NeuMeasu_Read_50
        enable-take-address=true, indirect-api=false, port=DataServices_Data_DiagnServi_Type_number_BCUe_Read
        enable-take-address=true, indirect-api=false, port=DataServices_Data_DiagnServi_TABROW_NeuMeasu_Read_53
        enable-take-address=true, indirect-api=false, port=DataServices_Data_DiagnServi_TABROW_NeuMeasu_Read_52
        enable-take-address=true, indirect-api=false, port=DataServices_Data_DiagnServi_TABROW_NeuMeasu_Read_51
        enable-take-address=true, indirect-api=false, port=DataServices_Data_DiagnServi_TABROW_NeuMeasu_Read_56
        enable-take-address=true, indirect-api=false, port=DataServices_Data_DiagnServi_TABROW_NeuMeasu_Read_55
        enable-take-address=true, indirect-api=false, port=DataServices_Data_DiagnServi_TABROW_NeuMeasu_Read_61
        enable-take-address=true, indirect-api=false, port=DataServices_Data_DiagnServi_TABROW_NeuMeasu_Read_60
        enable-take-address=true, indirect-api=false, port=DataServices_Data_DiagnServi_TABROW_NeuMeasu_Read_63
        enable-take-address=true, indirect-api=false, port=DataServices_Data_DiagnServi_BMC_clamp_30c_Read
        enable-take-address=true, indirect-api=false, port=DataServices_Data_TABROW_CellVoltaSum_ReadDataByIdent
        enable-take-address=true, indirect-api=false, port=DataServices_Data_DiagnServi_TABROW_NeuMeasu_Read_27_3_1_1
        enable-take-address=true, indirect-api=false, port=DataServices_Data_Battery_isolation_measurement_actual_and_requested_state_Read_Data_By_Identifier
        enable-take-address=true, indirect-api=false, port=DataServices_Data_TABROW_ServiDiscoState_Read_Data_By_Identifier
        enable-take-address=true, indirect-api=false, port=DataServices_Data_TABROW_RegulXSoftwIdentNumbe_Read
        enable-take-address=true, indirect-api=false, port=DataServices_Data_TABROW_ConfiHash_Read
        enable-take-address=true, indirect-api=false, port=DataServices_Data_TABROW_VehicIdentNumbe_Read
        enable-take-address=true, indirect-api=false, port=DataServices_Data_TABROW_ProgrHash_Read
        enable-take-address=true, indirect-api=false, port=Dcm_Read_ExtendedSFDRole
        enable-take-address=true, indirect-api=false, port=Dcm_Read_EptiSFDRole
        enable-take-address=true, indirect-api=false, port=Dcm_Read_E2eSFDRole
        enable-take-address=true, indirect-api=false, port=Dcm_Read_OtaSFDRole
        enable-take-address=true, indirect-api=false, port=Dcm_Read_SuperUserSFDRole
        enable-take-address=true, indirect-api=false, port=Dcm_Read_BasicSFDRole
        enable-take-address=true, indirect-api=false, port=Dcm_Read_ProductionSFDRole
        enable-take-address=true, indirect-api=false, port=DataServices_Data_TABROW_SFDDevelModeActiv_Read
        enable-take-address=true, indirect-api=false, port=DataServices_Data_TABROW_VishnDID_Read
        enable-take-address=true, indirect-api=false, port=DataServices_Data_Vishnu_DID
        enable-take-address=true, indirect-api=false, port=DataServices_Data_TABROW_CanTPData_Read
        enable-take-address=true, indirect-api=false, port=DataServices_Data_TABROW_PIMDID_Read
        enable-take-address=true, indirect-api=false, port=RoutineServices_Routine_DiagnServi_TABROW_NewRoutiBasicSetti_Start_Routine
        enable-take-address=true, indirect-api=false, port=SecurityAccess_UnLock_L2
        enable-take-address=true, indirect-api=false, port=DataServices_Data_TABROW_HVBatteBackFlowTempeWrite_Read
